VERSION "created by canmatrix"

NS_ :

BS_:

BU_: FR GW

BO_ 33 ADCU_SYNC_FUP: 8 GW
 SG_ ADCU_TSYNC_Type M : 7|8@0+ (1,0) [0|255] ""  FR
 SG_ ADCU_TSYNC_Fup_CRC m40 : 15|8@0+ (1,0) [0|255] ""  FR
 SG_ ADCU_TSYNC_Sync_CRC m32 : 15|8@0+ (1,0) [0|255] ""  FR
 SG_ ADCU_TSYNC_Fup_TimeDomain m40 : 23|4@0+ (1,0) [0|15] ""  FR
 SG_ ADCU_TSYNC_Sync_TimeDomain m32 : 23|4@0+ (1,0) [0|15] ""  FR
 SG_ ADCU_TSYNC_Fup_SeqCounter m40 : 19|4@0+ (1,0) [0|15] ""  FR
 SG_ ADCU_TSYNC_Sync_SeqCounter m32 : 19|4@0+ (1,0) [0|15] ""  FR
 SG_ ADCU_TSYNC_Fup_Reserved m40 : 31|5@0+ (1,0) [0|1] ""  FR
 SG_ ADCU_TSYNC_Sync_UserByte0 m32 : 31|8@0+ (1,0) [0|255] ""  FR
 SG_ ADCU_TSYNC_Fup_SGW m40 : 26|1@0+ (1,0) [0|1] ""  FR
 SG_ ADCU_TSYNC_Fup_OVS m40 : 25|2@0+ (1,0) [0|3] "s"  FR
 SG_ ADCU_TSYNC_Fup_SyncTimeNSec m40 : 39|32@0+ (1,0) [0|4294967295] "ns"  FR
 SG_ ADCU_TSYNC_Sync_TimeSec m32 : 39|32@0+ (1,0) [0|4294967295] "s"  FR

BO_ 48 ARS_TIME_SYNC: 16 FR
 SG_ ARS_TSYNC_TimeStampGlobSec : 7|32@0+ (1,0) [0|4294967295] "s"  GW
 SG_ ARS_TSYNC_CRC16_Checksum : 119|16@0+ (1,0) [0|65535] ""  GW
 SG_ ARS_TSYNC_TimeStampGlobNSec : 39|32@0+ (1,0) [0|4294967295] "ns"  GW
 SG_ ARS_TSYNC_MaxTimeLeap : 71|12@0+ (1,0) [0|4095] "ms"  GW
 SG_ ARS_TSYNC_LastTimeLeap : 87|12@0+ (1,0) [0|4095] "ms"  GW
 SG_ ARS_TSYNC_MsgCounter : 111|8@0+ (1,0) [0|255] ""  GW

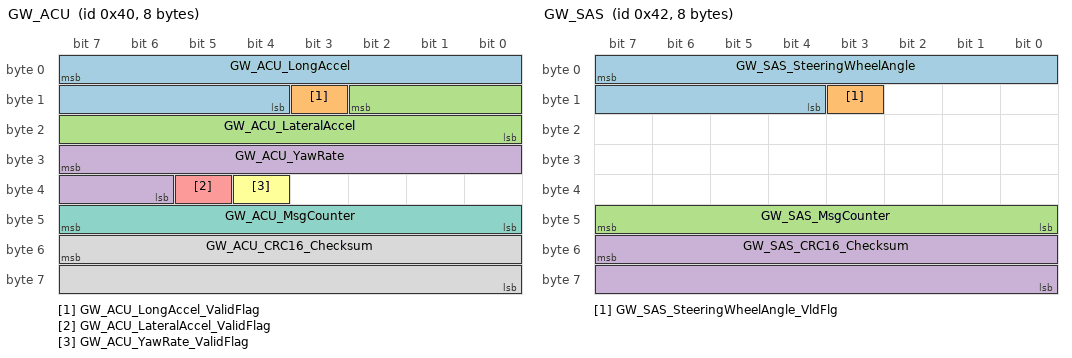
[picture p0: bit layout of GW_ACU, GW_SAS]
BO_ 64 GW_ACU: 8 GW
 SG_ GW_ACU_LongAccel : 7|12@0+ (0.01,-20.48) [-20.48|20.47] "m/s^2"  FR
 SG_ GW_ACU_LongAccel_ValidFlag : 11|1@0+ (1,0) [0|1] ""  FR
 SG_ GW_ACU_LateralAccel : 10|11@0+ (0.01,-10.24) [-10.24|10.23] "m/s^2"  FR
 SG_ GW_ACU_YawRate : 31|10@0+ (0.001,-0.511) [-0.511|0.512] "rad/s"  FR
 SG_ GW_ACU_LateralAccel_ValidFlag : 37|1@0+ (1,0) [0|1] ""  FR
 SG_ GW_ACU_YawRate_ValidFlag : 36|1@0+ (1,0) [0|1] ""  FR
 SG_ GW_ACU_MsgCounter : 47|8@0+ (1,0) [0|255] ""  FR
 SG_ GW_ACU_CRC16_Checksum : 55|16@0+ (1,0) [0|65535] ""  FR

BO_ 65 GW_ESC: 16 GW
 SG_ GW_ESC_WheelSpeed_FL : 7|13@0+ (0.01,0) [0|81.91] "m/s"  FR
 SG_ GW_ESC_MsgCounter : 111|8@0+ (1,0) [0|255] ""  FR
 SG_ GW_ESC_CRC16_Checksum : 119|16@0+ (1,0) [0|65535] ""  FR
 SG_ GW_ESC_WheelSpeed_FL_VldFlg : 10|1@0+ (1,0) [0|1] ""  FR
 SG_ GW_ESC_WheelDirection_FL : 9|2@0+ (1,0) [0|3] ""  FR
 SG_ GW_ESC_WheelSpeed_FR : 23|13@0+ (0.01,0) [0|81.91] "m/s"  FR
 SG_ GW_ESC_WheelSpeed_FR_VldFlg : 26|1@0+ (1,0) [0|1] ""  FR
 SG_ GW_ESC_WheelDirection_FR : 25|2@0+ (1,0) [0|3] ""  FR
 SG_ GW_ESC_WheelSpeed_RL : 39|13@0+ (0.01,0) [0|81.91] "m/s"  FR
 SG_ GW_ESC_WheelSpeed_RL_VldFlg : 42|1@0+ (1,0) [0|1] ""  FR
 SG_ GW_ESC_WheelDirection_RL : 41|2@0+ (1,0) [0|3] ""  FR
 SG_ GW_ESC_WheelSpeed_RR : 55|13@0+ (0.01,0) [0|81.91] "m/s"  FR
 SG_ GW_ESC_WheelSpeed_RR_VldFlg : 58|1@0+ (1,0) [0|1] ""  FR
 SG_ GW_ESC_WheelDirection_RR : 57|2@0+ (1,0) [0|3] ""  FR
 SG_ GW_ESC_WheelDirection_FL_VldFlg : 71|1@0+ (1,0) [0|1] ""  FR
 SG_ GW_ESC_WheelDirection_FR_VldFlg : 70|1@0+ (1,0) [0|1] ""  FR
 SG_ GW_ESC_WheelDirection_RL_VldFlg : 69|1@0+ (1,0) [0|1] ""  FR
 SG_ GW_ESC_WheelDirection_RR_VldFlg : 68|1@0+ (1,0) [0|1] ""  FR
 SG_ GW_ESC_ABS_ActiveFlag : 67|1@0+ (1,0) [0|1] ""  FR
 SG_ GW_ESC_ABS_ValidFlag : 66|1@0+ (1,0) [0|1] ""  FR
 SG_ GW_ESC_TCS_ActiveFlag : 65|1@0+ (1,0) [0|1] ""  FR
 SG_ GW_ESC_TCS_ValidFlag : 64|1@0+ (1,0) [0|1] ""  FR
 SG_ GW_ESC_VehicleSpeed : 79|13@0+ (0.01,0) [0|81.91] "m/s"  FR
 SG_ GW_ESC_VehicleSpeed_ValidFlag : 82|1@0+ (1,0) [0|1] ""  FR
 SG_ GW_ESC_EPB_ActiveFlag : 81|1@0+ (1,0) [0|1] ""  FR
 SG_ GW_ESC_EPB_ValidFlag : 80|1@0+ (1,0) [0|1] ""  FR

BO_ 66 GW_SAS: 8 GW
 SG_ GW_SAS_SteeringWheelAngle : 7|12@0+ (0.01,-20.48) [-20.48|20.47] "rad"  FR
 SG_ GW_SAS_SteeringWheelAngle_VldFlg : 11|1@0+ (1,0) [0|1] ""  FR
 SG_ GW_SAS_MsgCounter : 47|8@0+ (1,0) [0|255] ""  FR
 SG_ GW_SAS_CRC16_Checksum : 55|16@0+ (1,0) [0|65535] ""  FR

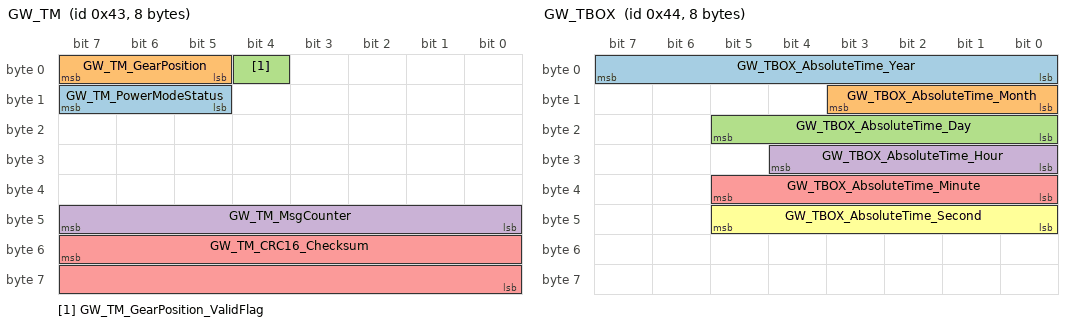
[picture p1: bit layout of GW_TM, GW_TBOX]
BO_ 67 GW_TM: 8 GW
 SG_ GW_TM_PowerModeStatus : 15|3@0+ (1,0) [0|7] ""  FR
 SG_ GW_TM_GearPosition : 7|3@0+ (1,0) [0|7] ""  FR
 SG_ GW_TM_GearPosition_ValidFlag : 4|1@0+ (1,0) [0|1] ""  FR
 SG_ GW_TM_MsgCounter : 47|8@0+ (1,0) [0|255] ""  FR
 SG_ GW_TM_CRC16_Checksum : 55|16@0+ (1,0) [0|65535] ""  FR

BO_ 68 GW_TBOX: 8 GW
 SG_ GW_TBOX_AbsoluteTime_Year : 7|8@0+ (1,1970) [1970|2100] "Year"  FR
 SG_ GW_TBOX_AbsoluteTime_Month : 11|4@0+ (1,0) [1|12] "Month"  FR
 SG_ GW_TBOX_AbsoluteTime_Day : 21|6@0+ (1,0) [1|31] "Day"  FR
 SG_ GW_TBOX_AbsoluteTime_Hour : 28|5@0+ (1,0) [0|23] "Hour"  FR
 SG_ GW_TBOX_AbsoluteTime_Minute : 37|6@0+ (1,0) [0|59] "Minute"  FR
 SG_ GW_TBOX_AbsoluteTime_Second : 45|6@0+ (1,0) [0|59] "Second"  FR

BO_ 69 GW_IDCM: 8 GW
 SG_ GW_IDCM_VehicleTotalMileage : 7|24@0+ (0.1,0) [0|999999.9] ""  FR

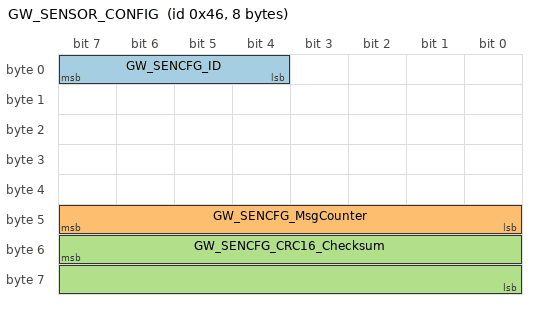
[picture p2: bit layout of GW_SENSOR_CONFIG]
BO_ 70 GW_SENSOR_CONFIG: 8 GW
 SG_ GW_SENCFG_ID : 7|4@0+ (1,0) [0|15] ""  FR
 SG_ GW_SENCFG_MsgCounter : 47|8@0+ (1,0) [0|255] ""  FR
 SG_ GW_SENCFG_CRC16_Checksum : 55|16@0+ (1,0) [0|65535] ""  FR

BO_ 80 ARS_CONFIG_STATE: 32 FR
 SG_ ARS_CFG_Mode : 7|8@0+ (1,0) [0|255] ""  GW
 SG_ ARS_CFG_VParAxisLdDistr_CFGflag : 15|1@0+ (1,0) [0|1] ""  GW
 SG_ ARS_CFG_VParCntrOGrvHght_CFGflag : 14|1@0+ (1,0) [0|1] ""  GW
 SG_ ARS_CFG_VParCntrOGrvHght : 111|10@0+ (0.001,0) [0|1.023] "m"  GW
 SG_ ARS_CFG_VParVehWeight_CFGflag : 13|1@0+ (1,0) [0|1] ""  GW
 SG_ ARS_CFG_VParTrkWdthRear_CFGflag : 12|1@0+ (1,0) [0|1] ""  GW
 SG_ ARS_CFG_VParAxisLdDistr : 127|10@0+ (0.1,0) [0|102.3] "%"  GW
 SG_ ARS_CFG_VParTrkWdthFrnt_CFGflag : 11|1@0+ (1,0) [0|1] ""  GW
 SG_ ARS_CFG_VParLatPos : 143|11@0+ (0.001,-1.023) [-1.023|1.024] "m"  GW
 SG_ ARS_CFG_VParWheelBase_CFGflag : 10|1@0+ (1,0) [0|1] ""  GW
 SG_ ARS_CFG_VParStrRatio_CFGflag : 9|1@0+ (1,0) [0|1] ""  GW
 SG_ ARS_CFG_VParLongPos : 159|13@0+ (0.001,-4.095) [-4.095|4.096] "m"  GW
 SG_ ARS_CFG_TimeSyncEnableFlag : 8|1@0+ (1,0) [0|1] ""  GW
 SG_ ARS_CFG_VParVertPos : 175|10@0+ (0.001,0) [0|1.023] "m"  GW
 SG_ ARS_CFG_VParStrRatio : 23|11@0+ (0.01,0) [0|20.47] ""  GW
 SG_ ARS_CFG_VParLatPos_CFGflag : 181|1@0+ (1,0) [0|1] ""  GW
 SG_ ARS_CFG_SensorID : 180|4@0+ (1,0) [0|15] "" Vector__XXX
 SG_ ARS_CFG_SensorID_CFGflag : 176|1@0+ (1,0) [0|1] "" Vector__XXX
 SG_ ARS_CFG_VParLngPos2CoG : 191|13@0+ (0.001,-4.095) [-4.095|4.096] "m"  GW
 SG_ ARS_CFG_VParYawAngle : 207|13@0+ (0.001,-4.095) [-4.095|4.096] "rad"  GW
 SG_ ARS_CFG_VParLongPos_CFGflag : 210|1@0+ (1,0) [0|1] ""  GW
 SG_ ARS_CFG_VParVertPos_CFGflag : 209|1@0+ (1,0) [0|1] ""  GW
 SG_ ARS_CFG_VParLngPos2CoG_CFGflag : 208|1@0+ (1,0) [0|1] ""  GW
 SG_ ARS_CFG_VParSnsrOrnt : 223|1@0+ (1,0) [0|1] ""  GW
 SG_ ARS_CFG_VParSnsrOrnt_CFGflag : 222|1@0+ (1,0) [0|1] ""  GW
 SG_ ARS_CFG_VParYawAngle_CFGflag : 221|1@0+ (1,0) [0|1] ""  GW
 SG_ ARS_CFG_VParCoverDamping_CFGflag : 220|1@0+ (1,0) [0|1] ""  GW
 SG_ ARS_CFG_VParCoverDamping : 219|12@0+ (0.001,0) [0|4.095] "dB"  GW
 SG_ ARS_CFG_MsgCounter : 239|8@0+ (1,0) [0|255] ""  GW
 SG_ ARS_CFG_CRC16_Checksum : 247|16@0+ (1,0) [0|65535] ""  GW
 SG_ ARS_CFG_VParWheelBase : 28|9@0+ (0.01,0) [0|5.11] "m"  GW
 SG_ ARS_CFG_VParTrkWdthFrnt : 47|11@0+ (0.001,0) [0|2.047] "m"  GW
 SG_ ARS_CFG_VParTrkWdthRear : 63|11@0+ (0.001,0) [0|2.047] "m"  GW
 SG_ ARS_CFG_VParVehWeight : 79|12@0+ (1,0) [0|4095] "kg"  GW

BO_ 82 ARS_SYS_PERFORM: 16 FR
 SG_ ARS_SP_OperationMode : 7|4@0+ (1,0) [0|15] ""  GW
 SG_ ARS_SP_CalibrationState : 3|3@0+ (1,0) [0|7] ""  GW
 SG_ ARS_SP_TunnelFlag : 0|1@0+ (1,0) [0|1] ""  GW
 SG_ ARS_SP_AzimuthCorrection : 15|8@0+ (0.0015,-0.1905) [-0.1905|0.192] "rad"  GW
 SG_ ARS_SP_MsgCounter : 111|8@0+ (1,0) [0|255] ""  GW
 SG_ ARS_SP_CRC16_Checksum : 119|16@0+ (1,0) [0|65535] ""  GW
 SG_ ARS_SP_ElevationCorrection : 23|8@0+ (0.0015,-0.1905) [-0.1905|0.192] "rad"  GW
 SG_ ARS_SP_ErrStateGroup_1 : 31|8@0+ (1,0) [0|255] ""  GW
 SG_ ARS_SP_ErrStateGroup_2 : 39|8@0+ (1,0) [0|255] ""  GW
 SG_ ARS_SP_ErrStateGroup_3 : 47|8@0+ (1,0) [0|255] ""  GW
 SG_ ARS_SP_ErrStateGroup_4 : 55|8@0+ (1,0) [0|255] ""  GW
 SG_ ARS_SP_VisibilityRange : 63|9@0+ (1,0) [0|511] "m"  GW
 SG_ ARS_SP_VisibilityState : 70|2@0+ (1,0) [0|3] ""  GW

BO_ 256 ARS_RDI_Header: 32 FR
 SG_ ARS_RDI_TimeStampGlobSec : 7|32@0+ (1,0) [0|4294967295] "s"  GW
 SG_ ARS_RDI_CycleCounter : 119|16@0+ (1,0) [0|65535] ""  GW
 SG_ ARS_RDI_NumOfClusters : 135|9@0+ (1,0) [0|511] ""  GW
 SG_ ARS_RDI_RangeResolution : 142|7@0+ (0.01,0) [0|1.27] "m"  GW
 SG_ ARS_RDI_MaxDetectionRange : 151|8@0+ (1,0) [0|255] "m"  GW
 SG_ ARS_RDI_EgoVelocity : 159|11@0+ (0.05,-17) [-17|85.35] "m/s"  GW
 SG_ ARS_RDI_EgoYawRate : 164|10@0+ (0.001,-0.511) [-0.511|0.512] "rad/s"  GW
 SG_ ARS_RDI_Latency : 170|11@0+ (0.1,30) [30|234.7] "ms"  GW
 SG_ ARS_RDI_EgoVelocityStd : 191|7@0+ (0.1,0) [0|12.7] "m/s"  GW
 SG_ ARS_RDI_EgoAcceleration : 184|9@0+ (0.0625,-10) [-10|21.9375] "m/s^2"  GW
 SG_ ARS_RDI_EgoCurvature : 207|10@0+ (0.001,-0.511) [-0.511|0.512] "1/m"  GW
 SG_ ARS_RDI_AmbigFreeDopplerRange : 213|12@0+ (0.01,0) [0|40.95] "m/s"  GW
 SG_ ARS_RDI_TaskValidFlag : 217|1@0+ (1,0) [0|1] ""  GW
 SG_ ARS_RDI_ExtendedCycleFlag : 216|1@0+ (1,0) [0|1] ""  GW
 SG_ ARS_RDI_MsgCounter_Header : 239|8@0+ (1,0) [0|255] ""  GW
 SG_ ARS_RDI_CRC16_Checksum_Header : 247|16@0+ (1,0) [0|65535] ""  GW
 SG_ ARS_RDI_TimeStampGlobNSec : 39|32@0+ (1,0) [0|4294967295] "ns"  GW
 SG_ ARS_RDI_TimeStampLocal : 71|32@0+ (1,0) [0|4294967295] "us"  GW
 SG_ ARS_RDI_MeasCounter : 103|16@0+ (1,0) [0|65535] ""  GW

BO_ 257 ARS_RDI_000_007: 64 FR
 SG_ ARS_RDI_Range_Clu_000 : 7|12@0+ (0.0625,0) [0|255.9375] "m"  GW
 SG_ ARS_RDI_ElevationAng_Clu_001 : 109|7@0+ (0.005,-0.315) [-0.315|0.32] "rad"  GW
 SG_ ARS_RDI_SNR_Clu_001 : 118|7@0+ (0.5,0) [0|63.5] "dB"  GW
 SG_ ARS_RDI_Range_Clu_002 : 127|12@0+ (0.0625,0) [0|255.9375] "m"  GW
 SG_ ARS_RDI_VradRel_Clu_000 : 11|11@0+ (0.1,-120) [-120|84.7] "m/s"  GW
 SG_ ARS_RDI_VradRel_Clu_002 : 131|11@0+ (0.1,-120) [-120|84.7] "m/s"  GW
 SG_ ARS_RDI_RCS_Clu_002 : 136|9@0+ (0.2,-51.2) [-51.2|51] "dBsm"  GW
 SG_ ARS_RDI_AzimuthAng_Clu_002 : 159|10@0+ (0.002,-1.022) [-1.022|1.024] "rad"  GW
 SG_ ARS_RDI_ElevationAng_Clu_002 : 165|7@0+ (0.005,-0.315) [-0.315|0.32] "rad"  GW
 SG_ ARS_RDI_SNR_Clu_002 : 174|7@0+ (0.5,0) [0|63.5] "dB"  GW
 SG_ ARS_RDI_DynProp_Clu_002 : 183|2@0+ (1,0) [0|3] ""  GW
 SG_ ARS_RDI_Quality_Clu_002 : 181|2@0+ (1,0) [0|3] ""  GW
 SG_ ARS_RDI_DynProp_Clu_003 : 179|2@0+ (1,0) [0|3] ""  GW
 SG_ ARS_RDI_Quality_Clu_003 : 177|2@0+ (1,0) [0|3] ""  GW
 SG_ ARS_RDI_Range_Clu_003 : 191|12@0+ (0.0625,0) [0|255.9375] "m"  GW
 SG_ ARS_RDI_VradRel_Clu_003 : 195|11@0+ (0.1,-120) [-120|84.7] "m/s"  GW
 SG_ ARS_RDI_RCS_Clu_003 : 200|9@0+ (0.2,-51.2) [-51.2|51] "dBsm"  GW
 SG_ ARS_RDI_AzimuthAng_Clu_003 : 223|10@0+ (0.002,-1.022) [-1.022|1.024] "rad"  GW
 SG_ ARS_RDI_ElevationAng_Clu_003 : 229|7@0+ (0.005,-0.315) [-0.315|0.32] "rad"  GW
 SG_ ARS_RDI_SNR_Clu_003 : 238|7@0+ (0.5,0) [0|63.5] "dB"  GW
 SG_ ARS_RDI_RCS_Clu_000 : 16|9@0+ (0.2,-51.2) [-51.2|51] "dBsm"  GW
 SG_ ARS_RDI_Range_Clu_004 : 247|12@0+ (0.0625,0) [0|255.9375] "m"  GW
 SG_ ARS_RDI_VradRel_Clu_004 : 251|11@0+ (0.1,-120) [-120|84.7] "m/s"  GW
 SG_ ARS_RDI_RCS_Clu_004 : 256|9@0+ (0.2,-51.2) [-51.2|51] "dBsm"  GW
 SG_ ARS_RDI_AzimuthAng_Clu_004 : 279|10@0+ (0.002,-1.022) [-1.022|1.024] "rad"  GW
 SG_ ARS_RDI_ElevationAng_Clu_004 : 285|7@0+ (0.005,-0.315) [-0.315|0.32] "rad"  GW
 SG_ ARS_RDI_SNR_Clu_004 : 294|7@0+ (0.5,0) [0|63.5] "dB"  GW
 SG_ ARS_RDI_DynProp_Clu_004 : 303|2@0+ (1,0) [0|3] ""  GW
 SG_ ARS_RDI_Quality_Clu_004 : 301|2@0+ (1,0) [0|3] ""  GW
 SG_ ARS_RDI_DynProp_Clu_005 : 299|2@0+ (1,0) [0|3] ""  GW
 SG_ ARS_RDI_Quality_Clu_005 : 297|2@0+ (1,0) [0|3] ""  GW
 SG_ ARS_RDI_Range_Clu_005 : 311|12@0+ (0.0625,0) [0|255.9375] "m"  GW
 SG_ ARS_RDI_VradRel_Clu_005 : 315|11@0+ (0.1,-120) [-120|84.7] "m/s"  GW
 SG_ ARS_RDI_RCS_Clu_005 : 320|9@0+ (0.2,-51.2) [-51.2|51] "dBsm"  GW
 SG_ ARS_RDI_AzimuthAng_Clu_000 : 39|10@0+ (0.002,-1.022) [-1.022|1.024] "rad"  GW
 SG_ ARS_RDI_AzimuthAng_Clu_005 : 343|10@0+ (0.002,-1.022) [-1.022|1.024] "rad"  GW
 SG_ ARS_RDI_ElevationAng_Clu_005 : 349|7@0+ (0.005,-0.315) [-0.315|0.32] "rad"  GW
 SG_ ARS_RDI_SNR_Clu_005 : 358|7@0+ (0.5,0) [0|63.5] "dB"  GW
 SG_ ARS_RDI_Range_Clu_006 : 367|12@0+ (0.0625,0) [0|255.9375] "m"  GW
 SG_ ARS_RDI_VradRel_Clu_006 : 371|11@0+ (0.1,-120) [-120|84.7] "m/s"  GW
 SG_ ARS_RDI_RCS_Clu_006 : 376|9@0+ (0.2,-51.2) [-51.2|51] "dBsm"  GW
 SG_ ARS_RDI_AzimuthAng_Clu_006 : 399|10@0+ (0.002,-1.022) [-1.022|1.024] "rad"  GW
 SG_ ARS_RDI_ElevationAng_Clu_006 : 405|7@0+ (0.005,-0.315) [-0.315|0.32] "rad"  GW
 SG_ ARS_RDI_SNR_Clu_006 : 414|7@0+ (0.5,0) [0|63.5] "dB"  GW
 SG_ ARS_RDI_DynProp_Clu_006 : 423|2@0+ (1,0) [0|3] ""  GW
 SG_ ARS_RDI_Quality_Clu_006 : 421|2@0+ (1,0) [0|3] ""  GW
 SG_ ARS_RDI_DynProp_Clu_007 : 419|2@0+ (1,0) [0|3] ""  GW
 SG_ ARS_RDI_Quality_Clu_007 : 417|2@0+ (1,0) [0|3] ""  GW
 SG_ ARS_RDI_Range_Clu_007 : 431|12@0+ (0.0625,0) [0|255.9375] "m"  GW
 SG_ ARS_RDI_ElevationAng_Clu_000 : 45|7@0+ (0.005,-0.315) [-0.315|0.32] "rad"  GW
 SG_ ARS_RDI_VradRel_Clu_007 : 435|11@0+ (0.1,-120) [-120|84.7] "m/s"  GW
 SG_ ARS_RDI_RCS_Clu_007 : 440|9@0+ (0.2,-51.2) [-51.2|51] "dBsm"  GW
 SG_ ARS_RDI_AzimuthAng_Clu_007 : 463|10@0+ (0.002,-1.022) [-1.022|1.024] "rad"  GW
 SG_ ARS_RDI_ElevationAng_Clu_007 : 469|7@0+ (0.005,-0.315) [-0.315|0.32] "rad"  GW
 SG_ ARS_RDI_SNR_Clu_007 : 478|7@0+ (0.5,0) [0|63.5] "dB"  GW
 SG_ ARS_RDI_MsgCounter_Clu_000_007 : 495|8@0+ (1,0) [0|255] ""  GW
 SG_ ARS_RDI_CRC16_Checksum_Clu_000_0 : 503|16@0+ (1,0) [0|65535] ""  GW
 SG_ ARS_RDI_SNR_Clu_000 : 54|7@0+ (0.5,0) [0|63.5] "dB"  GW
 SG_ ARS_RDI_DynProp_Clu_000 : 63|2@0+ (1,0) [0|3] ""  GW
 SG_ ARS_RDI_Quality_Clu_000 : 61|2@0+ (1,0) [0|3] ""  GW
 SG_ ARS_RDI_DynProp_Clu_001 : 59|2@0+ (1,0) [0|3] ""  GW
 SG_ ARS_RDI_Quality_Clu_001 : 57|2@0+ (1,0) [0|3] ""  GW
 SG_ ARS_RDI_Range_Clu_001 : 71|12@0+ (0.0625,0) [0|255.9375] "m"  GW
 SG_ ARS_RDI_VradRel_Clu_001 : 75|11@0+ (0.1,-120) [-120|84.7] "m/s"  GW
 SG_ ARS_RDI_RCS_Clu_001 : 80|9@0+ (0.2,-51.2) [-51.2|51] "dBsm"  GW
 SG_ ARS_RDI_AzimuthAng_Clu_001 : 103|10@0+ (0.002,-1.022) [-1.022|1.024] "rad"  GW

BO_ 258 ARS_RDI_008_015: 64 FR
 SG_ ARS_RDI_Range_Clu_008 : 7|12@0+ (0.0625,0) [0|255.9375] "m"  GW
 SG_ ARS_RDI_ElevationAng_Clu_009 : 109|7@0+ (0.005,-0.315) [-0.315|0.32] "rad"  GW
 SG_ ARS_RDI_SNR_Clu_009 : 118|7@0+ (0.5,0) [0|63.5] "dB"  GW
 SG_ ARS_RDI_Range_Clu_010 : 127|12@0+ (0.0625,0) [0|255.9375] "m"  GW
 SG_ ARS_RDI_VradRel_Clu_008 : 11|11@0+ (0.1,-120) [-120|84.7] "m/s"  GW
 SG_ ARS_RDI_VradRel_Clu_010 : 131|11@0+ (0.1,-120) [-120|84.7] "m/s"  GW
 SG_ ARS_RDI_RCS_Clu_010 : 136|9@0+ (0.2,-51.2) [-51.2|51] "dBsm"  GW
 SG_ ARS_RDI_AzimuthAng_Clu_010 : 159|10@0+ (0.002,-1.022) [-1.022|1.024] "rad"  GW
 SG_ ARS_RDI_ElevationAng_Clu_010 : 165|7@0+ (0.005,-0.315) [-0.315|0.32] "rad"  GW
 SG_ ARS_RDI_SNR_Clu_010 : 174|7@0+ (0.5,0) [0|63.5] "dB"  GW
 SG_ ARS_RDI_DynProp_Clu_010 : 183|2@0+ (1,0) [0|3] ""  GW
 SG_ ARS_RDI_Quality_Clu_010 : 181|2@0+ (1,0) [0|3] ""  GW
 SG_ ARS_RDI_DynProp_Clu_011 : 179|2@0+ (1,0) [0|3] ""  GW
 SG_ ARS_RDI_Quality_Clu_011 : 177|2@0+ (1,0) [0|3] ""  GW
 SG_ ARS_RDI_Range_Clu_011 : 191|12@0+ (0.0625,0) [0|255.9375] "m"  GW
 SG_ ARS_RDI_VradRel_Clu_011 : 195|11@0+ (0.1,-120) [-120|84.7] "m/s"  GW
 SG_ ARS_RDI_RCS_Clu_011 : 200|9@0+ (0.2,-51.2) [-51.2|51] "dBsm"  GW
 SG_ ARS_RDI_AzimuthAng_Clu_011 : 223|10@0+ (0.002,-1.022) [-1.022|1.024] "rad"  GW
 SG_ ARS_RDI_ElevationAng_Clu_011 : 229|7@0+ (0.005,-0.315) [-0.315|0.32] "rad"  GW
 SG_ ARS_RDI_SNR_Clu_011 : 238|7@0+ (0.5,0) [0|63.5] "dB"  GW
 SG_ ARS_RDI_RCS_Clu_008 : 16|9@0+ (0.2,-51.2) [-51.2|51] "dBsm"  GW
 SG_ ARS_RDI_Range_Clu_012 : 247|12@0+ (0.0625,0) [0|255.9375] "m"  GW
 SG_ ARS_RDI_VradRel_Clu_012 : 251|11@0+ (0.1,-120) [-120|84.7] "m/s"  GW
 SG_ ARS_RDI_RCS_Clu_012 : 256|9@0+ (0.2,-51.2) [-51.2|51] "dBsm"  GW
 SG_ ARS_RDI_AzimuthAng_Clu_012 : 279|10@0+ (0.002,-1.022) [-1.022|1.024] "rad"  GW
 SG_ ARS_RDI_ElevationAng_Clu_012 : 285|7@0+ (0.005,-0.315) [-0.315|0.32] "rad"  GW
 SG_ ARS_RDI_SNR_Clu_012 : 294|7@0+ (0.5,0) [0|63.5] "dB"  GW
 SG_ ARS_RDI_DynProp_Clu_012 : 303|2@0+ (1,0) [0|3] ""  GW
 SG_ ARS_RDI_Quality_Clu_012 : 301|2@0+ (1,0) [0|3] ""  GW
 SG_ ARS_RDI_DynProp_Clu_013 : 299|2@0+ (1,0) [0|3] ""  GW
 SG_ ARS_RDI_Quality_Clu_013 : 297|2@0+ (1,0) [0|3] ""  GW
 SG_ ARS_RDI_Range_Clu_013 : 311|12@0+ (0.0625,0) [0|255.9375] "m"  GW
 SG_ ARS_RDI_VradRel_Clu_013 : 315|11@0+ (0.1,-120) [-120|84.7] "m/s"  GW
 SG_ ARS_RDI_RCS_Clu_013 : 320|9@0+ (0.2,-51.2) [-51.2|51] "dBsm"  GW
 SG_ ARS_RDI_AzimuthAng_Clu_008 : 39|10@0+ (0.002,-1.022) [-1.022|1.024] "rad"  GW
 SG_ ARS_RDI_AzimuthAng_Clu_013 : 343|10@0+ (0.002,-1.022) [-1.022|1.024] "rad"  GW
 SG_ ARS_RDI_ElevationAng_Clu_013 : 349|7@0+ (0.005,-0.315) [-0.315|0.32] "rad"  GW
 SG_ ARS_RDI_SNR_Clu_013 : 358|7@0+ (0.5,0) [0|63.5] "dB"  GW
 SG_ ARS_RDI_Range_Clu_014 : 367|12@0+ (0.0625,0) [0|255.9375] "m"  GW
 SG_ ARS_RDI_VradRel_Clu_014 : 371|11@0+ (0.1,-120) [-120|84.7] "m/s"  GW
 SG_ ARS_RDI_RCS_Clu_014 : 376|9@0+ (0.2,-51.2) [-51.2|51] "dBsm"  GW
 SG_ ARS_RDI_AzimuthAng_Clu_014 : 399|10@0+ (0.002,-1.022) [-1.022|1.024] "rad"  GW
 SG_ ARS_RDI_ElevationAng_Clu_014 : 405|7@0+ (0.005,-0.315) [-0.315|0.32] "rad"  GW
 SG_ ARS_RDI_SNR_Clu_014 : 414|7@0+ (0.5,0) [0|63.5] "dB"  GW
 SG_ ARS_RDI_DynProp_Clu_014 : 423|2@0+ (1,0) [0|3] ""  GW
 SG_ ARS_RDI_Quality_Clu_014 : 421|2@0+ (1,0) [0|3] ""  GW
 SG_ ARS_RDI_DynProp_Clu_015 : 419|2@0+ (1,0) [0|3] ""  GW
 SG_ ARS_RDI_Quality_Clu_015 : 417|2@0+ (1,0) [0|3] ""  GW
 SG_ ARS_RDI_Range_Clu_015 : 431|12@0+ (0.0625,0) [0|255.9375] "m"  GW
 SG_ ARS_RDI_ElevationAng_Clu_008 : 45|7@0+ (0.005,-0.315) [-0.315|0.32] "rad"  GW
 SG_ ARS_RDI_VradRel_Clu_015 : 435|11@0+ (0.1,-120) [-120|84.7] "m/s"  GW
 SG_ ARS_RDI_RCS_Clu_015 : 440|9@0+ (0.2,-51.2) [-51.2|51] "dBsm"  GW
 SG_ ARS_RDI_AzimuthAng_Clu_015 : 463|10@0+ (0.002,-1.022) [-1.022|1.024] "rad"  GW
 SG_ ARS_RDI_ElevationAng_Clu_015 : 469|7@0+ (0.005,-0.315) [-0.315|0.32] "rad"  GW
 SG_ ARS_RDI_SNR_Clu_015 : 478|7@0+ (0.5,0) [0|63.5] "dB"  GW
 SG_ ARS_RDI_MsgCounter_Clu_008_015 : 495|8@0+ (1,0) [0|255] ""  GW
 SG_ ARS_RDI_CRC16_Checksum_Clu_008_0 : 503|16@0+ (1,0) [0|65535] ""  GW
 SG_ ARS_RDI_SNR_Clu_008 : 54|7@0+ (0.5,0) [0|63.5] "dB"  GW
 SG_ ARS_RDI_DynProp_Clu_008 : 63|2@0+ (1,0) [0|3] ""  GW
 SG_ ARS_RDI_Quality_Clu_008 : 61|2@0+ (1,0) [0|3] ""  GW
 SG_ ARS_RDI_DynProp_Clu_009 : 59|2@0+ (1,0) [0|3] ""  GW
 SG_ ARS_RDI_Quality_Clu_009 : 57|2@0+ (1,0) [0|3] ""  GW
 SG_ ARS_RDI_Range_Clu_009 : 71|12@0+ (0.0625,0) [0|255.9375] "m"  GW
 SG_ ARS_RDI_VradRel_Clu_009 : 75|11@0+ (0.1,-120) [-120|84.7] "m/s"  GW
 SG_ ARS_RDI_RCS_Clu_009 : 80|9@0+ (0.2,-51.2) [-51.2|51] "dBsm"  GW
 SG_ ARS_RDI_AzimuthAng_Clu_009 : 103|10@0+ (0.002,-1.022) [-1.022|1.024] "rad"  GW

BO_ 259 ARS_RDI_016_023: 64 FR
 SG_ ARS_RDI_Range_Clu_016 : 7|12@0+ (0.0625,0) [0|255.9375] "m"  GW
 SG_ ARS_RDI_ElevationAng_Clu_017 : 109|7@0+ (0.005,-0.315) [-0.315|0.32] "rad"  GW
 SG_ ARS_RDI_SNR_Clu_017 : 118|7@0+ (0.5,0) [0|63.5] "dB"  GW
 SG_ ARS_RDI_Range_Clu_018 : 127|12@0+ (0.0625,0) [0|255.9375] "m"  GW
 SG_ ARS_RDI_VradRel_Clu_016 : 11|11@0+ (0.1,-120) [-120|84.7] "m/s"  GW
 SG_ ARS_RDI_VradRel_Clu_018 : 131|11@0+ (0.1,-120) [-120|84.7] "m/s"  GW
 SG_ ARS_RDI_RCS_Clu_018 : 136|9@0+ (0.2,-51.2) [-51.2|51] "dBsm"  GW
 SG_ ARS_RDI_AzimuthAng_Clu_018 : 159|10@0+ (0.002,-1.022) [-1.022|1.024] "rad"  GW
 SG_ ARS_RDI_ElevationAng_Clu_018 : 165|7@0+ (0.005,-0.315) [-0.315|0.32] "rad"  GW
 SG_ ARS_RDI_SNR_Clu_018 : 174|7@0+ (0.5,0) [0|63.5] "dB"  GW
 SG_ ARS_RDI_DynProp_Clu_018 : 183|2@0+ (1,0) [0|3] ""  GW
 SG_ ARS_RDI_Quality_Clu_018 : 181|2@0+ (1,0) [0|3] ""  GW
 SG_ ARS_RDI_DynProp_Clu_019 : 179|2@0+ (1,0) [0|3] ""  GW
 SG_ ARS_RDI_Quality_Clu_019 : 177|2@0+ (1,0) [0|3] ""  GW
 SG_ ARS_RDI_Range_Clu_019 : 191|12@0+ (0.0625,0) [0|255.9375] "m"  GW
 SG_ ARS_RDI_VradRel_Clu_019 : 195|11@0+ (0.1,-120) [-120|84.7] "m/s"  GW
 SG_ ARS_RDI_RCS_Clu_019 : 200|9@0+ (0.2,-51.2) [-51.2|51] "dBsm"  GW
 SG_ ARS_RDI_AzimuthAng_Clu_019 : 223|10@0+ (0.002,-1.022) [-1.022|1.024] "rad"  GW
 SG_ ARS_RDI_ElevationAng_Clu_019 : 229|7@0+ (0.005,-0.315) [-0.315|0.32] "rad"  GW
 SG_ ARS_RDI_SNR_Clu_019 : 238|7@0+ (0.5,0) [0|63.5] "dB"  GW
 SG_ ARS_RDI_RCS_Clu_016 : 16|9@0+ (0.2,-51.2) [-51.2|51] "dBsm"  GW
 SG_ ARS_RDI_Range_Clu_020 : 247|12@0+ (0.0625,0) [0|255.9375] "m"  GW
 SG_ ARS_RDI_VradRel_Clu_020 : 251|11@0+ (0.1,-120) [-120|84.7] "m/s"  GW
 SG_ ARS_RDI_RCS_Clu_020 : 256|9@0+ (0.2,-51.2) [-51.2|51] "dBsm"  GW
 SG_ ARS_RDI_AzimuthAng_Clu_020 : 279|10@0+ (0.002,-1.022) [-1.022|1.024] "rad"  GW
 SG_ ARS_RDI_ElevationAng_Clu_020 : 285|7@0+ (0.005,-0.315) [-0.315|0.32] "rad"  GW
 SG_ ARS_RDI_SNR_Clu_020 : 294|7@0+ (0.5,0) [0|63.5] "dB"  GW
 SG_ ARS_RDI_DynProp_Clu_020 : 303|2@0+ (1,0) [0|3] ""  GW
 SG_ ARS_RDI_Quality_Clu_020 : 301|2@0+ (1,0) [0|3] ""  GW
 SG_ ARS_RDI_DynProp_Clu_021 : 299|2@0+ (1,0) [0|3] ""  GW
 SG_ ARS_RDI_Quality_Clu_021 : 297|2@0+ (1,0) [0|3] ""  GW
 SG_ ARS_RDI_Range_Clu_021 : 311|12@0+ (0.0625,0) [0|255.9375] "m"  GW
 SG_ ARS_RDI_VradRel_Clu_021 : 315|11@0+ (0.1,-120) [-120|84.7] "m/s"  GW
 SG_ ARS_RDI_RCS_Clu_021 : 320|9@0+ (0.2,-51.2) [-51.2|51] "dBsm"  GW
 SG_ ARS_RDI_AzimuthAng_Clu_016 : 39|10@0+ (0.002,-1.022) [-1.022|1.024] "rad"  GW
 SG_ ARS_RDI_AzimuthAng_Clu_021 : 343|10@0+ (0.002,-1.022) [-1.022|1.024] "rad"  GW
 SG_ ARS_RDI_ElevationAng_Clu_021 : 349|7@0+ (0.005,-0.315) [-0.315|0.32] "rad"  GW
 SG_ ARS_RDI_SNR_Clu_021 : 358|7@0+ (0.5,0) [0|63.5] "dB"  GW
 SG_ ARS_RDI_Range_Clu_022 : 367|12@0+ (0.0625,0) [0|255.9375] "m"  GW
 SG_ ARS_RDI_VradRel_Clu_022 : 371|11@0+ (0.1,-120) [-120|84.7] "m/s"  GW
 SG_ ARS_RDI_RCS_Clu_022 : 376|9@0+ (0.2,-51.2) [-51.2|51] "dBsm"  GW
 SG_ ARS_RDI_AzimuthAng_Clu_022 : 399|10@0+ (0.002,-1.022) [-1.022|1.024] "rad"  GW
 SG_ ARS_RDI_ElevationAng_Clu_022 : 405|7@0+ (0.005,-0.315) [-0.315|0.32] "rad"  GW
 SG_ ARS_RDI_SNR_Clu_022 : 414|7@0+ (0.5,0) [0|63.5] "dB"  GW
 SG_ ARS_RDI_DynProp_Clu_022 : 423|2@0+ (1,0) [0|3] ""  GW
 SG_ ARS_RDI_Quality_Clu_022 : 421|2@0+ (1,0) [0|3] ""  GW
 SG_ ARS_RDI_DynProp_Clu_023 : 419|2@0+ (1,0) [0|3] ""  GW
 SG_ ARS_RDI_Quality_Clu_023 : 417|2@0+ (1,0) [0|3] ""  GW
 SG_ ARS_RDI_Range_Clu_023 : 431|12@0+ (0.0625,0) [0|255.9375] "m"  GW
 SG_ ARS_RDI_ElevationAng_Clu_016 : 45|7@0+ (0.005,-0.315) [-0.315|0.32] "rad"  GW
 SG_ ARS_RDI_VradRel_Clu_023 : 435|11@0+ (0.1,-120) [-120|84.7] "m/s"  GW
 SG_ ARS_RDI_RCS_Clu_023 : 440|9@0+ (0.2,-51.2) [-51.2|51] "dBsm"  GW
 SG_ ARS_RDI_AzimuthAng_Clu_023 : 463|10@0+ (0.002,-1.022) [-1.022|1.024] "rad"  GW
 SG_ ARS_RDI_ElevationAng_Clu_023 : 469|7@0+ (0.005,-0.315) [-0.315|0.32] "rad"  GW
 SG_ ARS_RDI_SNR_Clu_023 : 478|7@0+ (0.5,0) [0|63.5] "dB"  GW
 SG_ ARS_RDI_MsgCounter_Clu_016_023 : 495|8@0+ (1,0) [0|255] ""  GW
 SG_ ARS_RDI_CRC16_Checksum_Clu_016_0 : 503|16@0+ (1,0) [0|65535] ""  GW
 SG_ ARS_RDI_SNR_Clu_016 : 54|7@0+ (0.5,0) [0|63.5] "dB"  GW
 SG_ ARS_RDI_DynProp_Clu_016 : 63|2@0+ (1,0) [0|3] ""  GW
 SG_ ARS_RDI_Quality_Clu_016 : 61|2@0+ (1,0) [0|3] ""  GW
 SG_ ARS_RDI_DynProp_Clu_017 : 59|2@0+ (1,0) [0|3] ""  GW
 SG_ ARS_RDI_Quality_Clu_017 : 57|2@0+ (1,0) [0|3] ""  GW
 SG_ ARS_RDI_Range_Clu_017 : 71|12@0+ (0.0625,0) [0|255.9375] "m"  GW
 SG_ ARS_RDI_VradRel_Clu_017 : 75|11@0+ (0.1,-120) [-120|84.7] "m/s"  GW
 SG_ ARS_RDI_RCS_Clu_017 : 80|9@0+ (0.2,-51.2) [-51.2|51] "dBsm"  GW
 SG_ ARS_RDI_AzimuthAng_Clu_017 : 103|10@0+ (0.002,-1.022) [-1.022|1.024] "rad"  GW

BO_ 260 ARS_RDI_024_031: 64 FR
 SG_ ARS_RDI_Range_Clu_024 : 7|12@0+ (0.0625,0) [0|255.9375] "m"  GW
 SG_ ARS_RDI_ElevationAng_Clu_025 : 109|7@0+ (0.005,-0.315) [-0.315|0.32] "rad"  GW
 SG_ ARS_RDI_SNR_Clu_025 : 118|7@0+ (0.5,0) [0|63.5] "dB"  GW
 SG_ ARS_RDI_Range_Clu_026 : 127|12@0+ (0.0625,0) [0|255.9375] "m"  GW
 SG_ ARS_RDI_VradRel_Clu_024 : 11|11@0+ (0.1,-120) [-120|84.7] "m/s"  GW
 SG_ ARS_RDI_VradRel_Clu_026 : 131|11@0+ (0.1,-120) [-120|84.7] "m/s"  GW
 SG_ ARS_RDI_RCS_Clu_026 : 136|9@0+ (0.2,-51.2) [-51.2|51] "dBsm"  GW
 SG_ ARS_RDI_AzimuthAng_Clu_026 : 159|10@0+ (0.002,-1.022) [-1.022|1.024] "rad"  GW
 SG_ ARS_RDI_ElevationAng_Clu_026 : 165|7@0+ (0.005,-0.315) [-0.315|0.32] "rad"  GW
 SG_ ARS_RDI_SNR_Clu_026 : 174|7@0+ (0.5,0) [0|63.5] "dB"  GW
 SG_ ARS_RDI_DynProp_Clu_026 : 183|2@0+ (1,0) [0|3] ""  GW
 SG_ ARS_RDI_Quality_Clu_026 : 181|2@0+ (1,0) [0|3] ""  GW
 SG_ ARS_RDI_DynProp_Clu_027 : 179|2@0+ (1,0) [0|3] ""  GW
 SG_ ARS_RDI_Quality_Clu_027 : 177|2@0+ (1,0) [0|3] ""  GW
 SG_ ARS_RDI_Range_Clu_027 : 191|12@0+ (0.0625,0) [0|255.9375] "m"  GW
 SG_ ARS_RDI_VradRel_Clu_027 : 195|11@0+ (0.1,-120) [-120|84.7] "m/s"  GW
 SG_ ARS_RDI_RCS_Clu_027 : 200|9@0+ (0.2,-51.2) [-51.2|51] "dBsm"  GW
 SG_ ARS_RDI_AzimuthAng_Clu_027 : 223|10@0+ (0.002,-1.022) [-1.022|1.024] "rad"  GW
 SG_ ARS_RDI_ElevationAng_Clu_027 : 229|7@0+ (0.005,-0.315) [-0.315|0.32] "rad"  GW
 SG_ ARS_RDI_SNR_Clu_027 : 238|7@0+ (0.5,0) [0|63.5] "dB"  GW
 SG_ ARS_RDI_RCS_Clu_024 : 16|9@0+ (0.2,-51.2) [-51.2|51] "dBsm"  GW
 SG_ ARS_RDI_Range_Clu_028 : 247|12@0+ (0.0625,0) [0|255.9375] "m"  GW
 SG_ ARS_RDI_VradRel_Clu_028 : 251|11@0+ (0.1,-120) [-120|84.7] "m/s"  GW
 SG_ ARS_RDI_RCS_Clu_028 : 256|9@0+ (0.2,-51.2) [-51.2|51] "dBsm"  GW
 SG_ ARS_RDI_AzimuthAng_Clu_028 : 279|10@0+ (0.002,-1.022) [-1.022|1.024] "rad"  GW
 SG_ ARS_RDI_ElevationAng_Clu_028 : 285|7@0+ (0.005,-0.315) [-0.315|0.32] "rad"  GW
 SG_ ARS_RDI_SNR_Clu_028 : 294|7@0+ (0.5,0) [0|63.5] "dB"  GW
 SG_ ARS_RDI_DynProp_Clu_028 : 303|2@0+ (1,0) [0|3] ""  GW
 SG_ ARS_RDI_Quality_Clu_028 : 301|2@0+ (1,0) [0|3] ""  GW
 SG_ ARS_RDI_DynProp_Clu_029 : 299|2@0+ (1,0) [0|3] ""  GW
 SG_ ARS_RDI_Quality_Clu_029 : 297|2@0+ (1,0) [0|3] ""  GW
 SG_ ARS_RDI_Range_Clu_029 : 311|12@0+ (0.0625,0) [0|255.9375] "m"  GW
 SG_ ARS_RDI_VradRel_Clu_029 : 315|11@0+ (0.1,-120) [-120|84.7] "m/s"  GW
 SG_ ARS_RDI_RCS_Clu_029 : 320|9@0+ (0.2,-51.2) [-51.2|51] "dBsm"  GW
 SG_ ARS_RDI_AzimuthAng_Clu_024 : 39|10@0+ (0.002,-1.022) [-1.022|1.024] "rad"  GW
 SG_ ARS_RDI_AzimuthAng_Clu_029 : 343|10@0+ (0.002,-1.022) [-1.022|1.024] "rad"  GW
 SG_ ARS_RDI_ElevationAng_Clu_029 : 349|7@0+ (0.005,-0.315) [-0.315|0.32] "rad"  GW
 SG_ ARS_RDI_SNR_Clu_029 : 358|7@0+ (0.5,0) [0|63.5] "dB"  GW
 SG_ ARS_RDI_Range_Clu_030 : 367|12@0+ (0.0625,0) [0|255.9375] "m"  GW
 SG_ ARS_RDI_VradRel_Clu_030 : 371|11@0+ (0.1,-120) [-120|84.7] "m/s"  GW
 SG_ ARS_RDI_RCS_Clu_030 : 376|9@0+ (0.2,-51.2) [-51.2|51] "dBsm"  GW
 SG_ ARS_RDI_AzimuthAng_Clu_030 : 399|10@0+ (0.002,-1.022) [-1.022|1.024] "rad"  GW
 SG_ ARS_RDI_ElevationAng_Clu_030 : 405|7@0+ (0.005,-0.315) [-0.315|0.32] "rad"  GW
 SG_ ARS_RDI_SNR_Clu_030 : 414|7@0+ (0.5,0) [0|63.5] "dB"  GW
 SG_ ARS_RDI_DynProp_Clu_030 : 423|2@0+ (1,0) [0|3] ""  GW
 SG_ ARS_RDI_Quality_Clu_030 : 421|2@0+ (1,0) [0|3] ""  GW
 SG_ ARS_RDI_DynProp_Clu_031 : 419|2@0+ (1,0) [0|3] ""  GW
 SG_ ARS_RDI_Quality_Clu_031 : 417|2@0+ (1,0) [0|3] ""  GW
 SG_ ARS_RDI_Range_Clu_031 : 431|12@0+ (0.0625,0) [0|255.9375] "m"  GW
 SG_ ARS_RDI_ElevationAng_Clu_024 : 45|7@0+ (0.005,-0.315) [-0.315|0.32] "rad"  GW
 SG_ ARS_RDI_VradRel_Clu_031 : 435|11@0+ (0.1,-120) [-120|84.7] "m/s"  GW
 SG_ ARS_RDI_RCS_Clu_031 : 440|9@0+ (0.2,-51.2) [-51.2|51] "dBsm"  GW
 SG_ ARS_RDI_AzimuthAng_Clu_031 : 463|10@0+ (0.002,-1.022) [-1.022|1.024] "rad"  GW
 SG_ ARS_RDI_ElevationAng_Clu_031 : 469|7@0+ (0.005,-0.315) [-0.315|0.32] "rad"  GW
 SG_ ARS_RDI_SNR_Clu_031 : 478|7@0+ (0.5,0) [0|63.5] "dB"  GW
 SG_ ARS_RDI_MsgCounter_Clu_024_031 : 495|8@0+ (1,0) [0|255] ""  GW
 SG_ ARS_RDI_CRC16_Checksum_Clu_024_0 : 503|16@0+ (1,0) [0|65535] ""  GW
 SG_ ARS_RDI_SNR_Clu_024 : 54|7@0+ (0.5,0) [0|63.5] "dB"  GW
 SG_ ARS_RDI_DynProp_Clu_024 : 63|2@0+ (1,0) [0|3] ""  GW
 SG_ ARS_RDI_Quality_Clu_024 : 61|2@0+ (1,0) [0|3] ""  GW
 SG_ ARS_RDI_DynProp_Clu_025 : 59|2@0+ (1,0) [0|3] ""  GW
 SG_ ARS_RDI_Quality_Clu_025 : 57|2@0+ (1,0) [0|3] ""  GW
 SG_ ARS_RDI_Range_Clu_025 : 71|12@0+ (0.0625,0) [0|255.9375] "m"  GW
 SG_ ARS_RDI_VradRel_Clu_025 : 75|11@0+ (0.1,-120) [-120|84.7] "m/s"  GW
 SG_ ARS_RDI_RCS_Clu_025 : 80|9@0+ (0.2,-51.2) [-51.2|51] "dBsm"  GW
 SG_ ARS_RDI_AzimuthAng_Clu_025 : 103|10@0+ (0.002,-1.022) [-1.022|1.024] "rad"  GW

BO_ 261 ARS_RDI_032_039: 64 FR
 SG_ ARS_RDI_Range_Clu_032 : 7|12@0+ (0.0625,0) [0|255.9375] "m"  GW
 SG_ ARS_RDI_ElevationAng_Clu_033 : 109|7@0+ (0.005,-0.315) [-0.315|0.32] "rad"  GW
 SG_ ARS_RDI_SNR_Clu_033 : 118|7@0+ (0.5,0) [0|63.5] "dB"  GW
 SG_ ARS_RDI_Range_Clu_034 : 127|12@0+ (0.0625,0) [0|255.9375] "m"  GW
 SG_ ARS_RDI_VradRel_Clu_032 : 11|11@0+ (0.1,-120) [-120|84.7] "m/s"  GW
 SG_ ARS_RDI_VradRel_Clu_034 : 131|11@0+ (0.1,-120) [-120|84.7] "m/s"  GW
 SG_ ARS_RDI_RCS_Clu_034 : 136|9@0+ (0.2,-51.2) [-51.2|51] "dBsm"  GW
 SG_ ARS_RDI_AzimuthAng_Clu_034 : 159|10@0+ (0.002,-1.022) [-1.022|1.024] "rad"  GW
 SG_ ARS_RDI_ElevationAng_Clu_034 : 165|7@0+ (0.005,-0.315) [-0.315|0.32] "rad"  GW
 SG_ ARS_RDI_SNR_Clu_034 : 174|7@0+ (0.5,0) [0|63.5] "dB"  GW
 SG_ ARS_RDI_DynProp_Clu_034 : 183|2@0+ (1,0) [0|3] ""  GW
 SG_ ARS_RDI_Quality_Clu_034 : 181|2@0+ (1,0) [0|3] ""  GW
 SG_ ARS_RDI_DynProp_Clu_035 : 179|2@0+ (1,0) [0|3] ""  GW
 SG_ ARS_RDI_Quality_Clu_035 : 177|2@0+ (1,0) [0|3] ""  GW
 SG_ ARS_RDI_Range_Clu_035 : 191|12@0+ (0.0625,0) [0|255.9375] "m"  GW
 SG_ ARS_RDI_VradRel_Clu_035 : 195|11@0+ (0.1,-120) [-120|84.7] "m/s"  GW
 SG_ ARS_RDI_RCS_Clu_035 : 200|9@0+ (0.2,-51.2) [-51.2|51] "dBsm"  GW
 SG_ ARS_RDI_AzimuthAng_Clu_035 : 223|10@0+ (0.002,-1.022) [-1.022|1.024] "rad"  GW
 SG_ ARS_RDI_ElevationAng_Clu_035 : 229|7@0+ (0.005,-0.315) [-0.315|0.32] "rad"  GW
 SG_ ARS_RDI_SNR_Clu_035 : 238|7@0+ (0.5,0) [0|63.5] "dB"  GW
 SG_ ARS_RDI_RCS_Clu_032 : 16|9@0+ (0.2,-51.2) [-51.2|51] "dBsm"  GW
 SG_ ARS_RDI_Range_Clu_036 : 247|12@0+ (0.0625,0) [0|255.9375] "m"  GW
 SG_ ARS_RDI_VradRel_Clu_036 : 251|11@0+ (0.1,-120) [-120|84.7] "m/s"  GW
 SG_ ARS_RDI_RCS_Clu_036 : 256|9@0+ (0.2,-51.2) [-51.2|51] "dBsm"  GW
 SG_ ARS_RDI_AzimuthAng_Clu_036 : 279|10@0+ (0.002,-1.022) [-1.022|1.024] "rad"  GW
 SG_ ARS_RDI_ElevationAng_Clu_036 : 285|7@0+ (0.005,-0.315) [-0.315|0.32] "rad"  GW
 SG_ ARS_RDI_SNR_Clu_036 : 294|7@0+ (0.5,0) [0|63.5] "dB"  GW
 SG_ ARS_RDI_DynProp_Clu_036 : 303|2@0+ (1,0) [0|3] ""  GW
 SG_ ARS_RDI_Quality_Clu_036 : 301|2@0+ (1,0) [0|3] ""  GW
 SG_ ARS_RDI_DynProp_Clu_037 : 299|2@0+ (1,0) [0|3] ""  GW
 SG_ ARS_RDI_Quality_Clu_037 : 297|2@0+ (1,0) [0|3] ""  GW
 SG_ ARS_RDI_Range_Clu_037 : 311|12@0+ (0.0625,0) [0|255.9375] "m"  GW
 SG_ ARS_RDI_VradRel_Clu_037 : 315|11@0+ (0.1,-120) [-120|84.7] "m/s"  GW
 SG_ ARS_RDI_RCS_Clu_037 : 320|9@0+ (0.2,-51.2) [-51.2|51] "dBsm"  GW
 SG_ ARS_RDI_AzimuthAng_Clu_032 : 39|10@0+ (0.002,-1.022) [-1.022|1.024] "rad"  GW
 SG_ ARS_RDI_AzimuthAng_Clu_037 : 343|10@0+ (0.002,-1.022) [-1.022|1.024] "rad"  GW
 SG_ ARS_RDI_ElevationAng_Clu_037 : 349|7@0+ (0.005,-0.315) [-0.315|0.32] "rad"  GW
 SG_ ARS_RDI_SNR_Clu_037 : 358|7@0+ (0.5,0) [0|63.5] "dB"  GW
 SG_ ARS_RDI_Range_Clu_038 : 367|12@0+ (0.0625,0) [0|255.9375] "m"  GW
 SG_ ARS_RDI_VradRel_Clu_038 : 371|11@0+ (0.1,-120) [-120|84.7] "m/s"  GW
 SG_ ARS_RDI_RCS_Clu_038 : 376|9@0+ (0.2,-51.2) [-51.2|51] "dBsm"  GW
 SG_ ARS_RDI_AzimuthAng_Clu_038 : 399|10@0+ (0.002,-1.022) [-1.022|1.024] "rad"  GW
 SG_ ARS_RDI_ElevationAng_Clu_038 : 405|7@0+ (0.005,-0.315) [-0.315|0.32] "rad"  GW
 SG_ ARS_RDI_SNR_Clu_038 : 414|7@0+ (0.5,0) [0|63.5] "dB"  GW
 SG_ ARS_RDI_DynProp_Clu_038 : 423|2@0+ (1,0) [0|3] ""  GW
 SG_ ARS_RDI_Quality_Clu_038 : 421|2@0+ (1,0) [0|3] ""  GW
 SG_ ARS_RDI_DynProp_Clu_039 : 419|2@0+ (1,0) [0|3] ""  GW
 SG_ ARS_RDI_Quality_Clu_039 : 417|2@0+ (1,0) [0|3] ""  GW
 SG_ ARS_RDI_Range_Clu_039 : 431|12@0+ (0.0625,0) [0|255.9375] "m"  GW
 SG_ ARS_RDI_ElevationAng_Clu_032 : 45|7@0+ (0.005,-0.315) [-0.315|0.32] "rad"  GW
 SG_ ARS_RDI_VradRel_Clu_039 : 435|11@0+ (0.1,-120) [-120|84.7] "m/s"  GW
 SG_ ARS_RDI_RCS_Clu_039 : 440|9@0+ (0.2,-51.2) [-51.2|51] "dBsm"  GW
 SG_ ARS_RDI_AzimuthAng_Clu_039 : 463|10@0+ (0.002,-1.022) [-1.022|1.024] "rad"  GW
 SG_ ARS_RDI_ElevationAng_Clu_039 : 469|7@0+ (0.005,-0.315) [-0.315|0.32] "rad"  GW
 SG_ ARS_RDI_SNR_Clu_039 : 478|7@0+ (0.5,0) [0|63.5] "dB"  GW
 SG_ ARS_RDI_MsgCounter_Clu_032_039 : 495|8@0+ (1,0) [0|255] ""  GW
 SG_ ARS_RDI_CRC16_Checksum_Clu_032_0 : 503|16@0+ (1,0) [0|65535] ""  GW
 SG_ ARS_RDI_SNR_Clu_032 : 54|7@0+ (0.5,0) [0|63.5] "dB"  GW
 SG_ ARS_RDI_DynProp_Clu_032 : 63|2@0+ (1,0) [0|3] ""  GW
 SG_ ARS_RDI_Quality_Clu_032 : 61|2@0+ (1,0) [0|3] ""  GW
 SG_ ARS_RDI_DynProp_Clu_033 : 59|2@0+ (1,0) [0|3] ""  GW
 SG_ ARS_RDI_Quality_Clu_033 : 57|2@0+ (1,0) [0|3] ""  GW
 SG_ ARS_RDI_Range_Clu_033 : 71|12@0+ (0.0625,0) [0|255.9375] "m"  GW
 SG_ ARS_RDI_VradRel_Clu_033 : 75|11@0+ (0.1,-120) [-120|84.7] "m/s"  GW
 SG_ ARS_RDI_RCS_Clu_033 : 80|9@0+ (0.2,-51.2) [-51.2|51] "dBsm"  GW
 SG_ ARS_RDI_AzimuthAng_Clu_033 : 103|10@0+ (0.002,-1.022) [-1.022|1.024] "rad"  GW

BO_ 262 ARS_RDI_040_047: 64 FR
 SG_ ARS_RDI_Range_Clu_040 : 7|12@0+ (0.0625,0) [0|255.9375] "m"  GW
 SG_ ARS_RDI_ElevationAng_Clu_041 : 109|7@0+ (0.005,-0.315) [-0.315|0.32] "rad"  GW
 SG_ ARS_RDI_SNR_Clu_041 : 118|7@0+ (0.5,0) [0|63.5] "dB"  GW
 SG_ ARS_RDI_Range_Clu_042 : 127|12@0+ (0.0625,0) [0|255.9375] "m"  GW
 SG_ ARS_RDI_VradRel_Clu_040 : 11|11@0+ (0.1,-120) [-120|84.7] "m/s"  GW
 SG_ ARS_RDI_VradRel_Clu_042 : 131|11@0+ (0.1,-120) [-120|84.7] "m/s"  GW
 SG_ ARS_RDI_RCS_Clu_042 : 136|9@0+ (0.2,-51.2) [-51.2|51] "dBsm"  GW
 SG_ ARS_RDI_AzimuthAng_Clu_042 : 159|10@0+ (0.002,-1.022) [-1.022|1.024] "rad"  GW
 SG_ ARS_RDI_ElevationAng_Clu_042 : 165|7@0+ (0.005,-0.315) [-0.315|0.32] "rad"  GW
 SG_ ARS_RDI_SNR_Clu_042 : 174|7@0+ (0.5,0) [0|63.5] "dB"  GW
 SG_ ARS_RDI_DynProp_Clu_042 : 183|2@0+ (1,0) [0|3] ""  GW
 SG_ ARS_RDI_Quality_Clu_042 : 181|2@0+ (1,0) [0|3] ""  GW
 SG_ ARS_RDI_DynProp_Clu_043 : 179|2@0+ (1,0) [0|3] ""  GW
 SG_ ARS_RDI_Quality_Clu_043 : 177|2@0+ (1,0) [0|3] ""  GW
 SG_ ARS_RDI_Range_Clu_043 : 191|12@0+ (0.0625,0) [0|255.9375] "m"  GW
 SG_ ARS_RDI_VradRel_Clu_043 : 195|11@0+ (0.1,-120) [-120|84.7] "m/s"  GW
 SG_ ARS_RDI_RCS_Clu_043 : 200|9@0+ (0.2,-51.2) [-51.2|51] "dBsm"  GW
 SG_ ARS_RDI_AzimuthAng_Clu_043 : 223|10@0+ (0.002,-1.022) [-1.022|1.024] "rad"  GW
 SG_ ARS_RDI_ElevationAng_Clu_043 : 229|7@0+ (0.005,-0.315) [-0.315|0.32] "rad"  GW
 SG_ ARS_RDI_SNR_Clu_043 : 238|7@0+ (0.5,0) [0|63.5] "dB"  GW
 SG_ ARS_RDI_RCS_Clu_040 : 16|9@0+ (0.2,-51.2) [-51.2|51] "dBsm"  GW
 SG_ ARS_RDI_Range_Clu_044 : 247|12@0+ (0.0625,0) [0|255.9375] "m"  GW
 SG_ ARS_RDI_VradRel_Clu_044 : 251|11@0+ (0.1,-120) [-120|84.7] "m/s"  GW
 SG_ ARS_RDI_RCS_Clu_044 : 256|9@0+ (0.2,-51.2) [-51.2|51] "dBsm"  GW
 SG_ ARS_RDI_AzimuthAng_Clu_044 : 279|10@0+ (0.002,-1.022) [-1.022|1.024] "rad"  GW
 SG_ ARS_RDI_ElevationAng_Clu_044 : 285|7@0+ (0.005,-0.315) [-0.315|0.32] "rad"  GW
 SG_ ARS_RDI_SNR_Clu_044 : 294|7@0+ (0.5,0) [0|63.5] "dB"  GW
 SG_ ARS_RDI_DynProp_Clu_044 : 303|2@0+ (1,0) [0|3] ""  GW
 SG_ ARS_RDI_Quality_Clu_044 : 301|2@0+ (1,0) [0|3] ""  GW
 SG_ ARS_RDI_DynProp_Clu_045 : 299|2@0+ (1,0) [0|3] ""  GW
 SG_ ARS_RDI_Quality_Clu_045 : 297|2@0+ (1,0) [0|3] ""  GW
 SG_ ARS_RDI_Range_Clu_045 : 311|12@0+ (0.0625,0) [0|255.9375] "m"  GW
 SG_ ARS_RDI_VradRel_Clu_045 : 315|11@0+ (0.1,-120) [-120|84.7] "m/s"  GW
 SG_ ARS_RDI_RCS_Clu_045 : 320|9@0+ (0.2,-51.2) [-51.2|51] "dBsm"  GW
 SG_ ARS_RDI_AzimuthAng_Clu_040 : 39|10@0+ (0.002,-1.022) [-1.022|1.024] "rad"  GW
 SG_ ARS_RDI_AzimuthAng_Clu_045 : 343|10@0+ (0.002,-1.022) [-1.022|1.024] "rad"  GW
 SG_ ARS_RDI_ElevationAng_Clu_045 : 349|7@0+ (0.005,-0.315) [-0.315|0.32] "rad"  GW
 SG_ ARS_RDI_SNR_Clu_045 : 358|7@0+ (0.5,0) [0|63.5] "dB"  GW
 SG_ ARS_RDI_Range_Clu_046 : 367|12@0+ (0.0625,0) [0|255.9375] "m"  GW
 SG_ ARS_RDI_VradRel_Clu_046 : 371|11@0+ (0.1,-120) [-120|84.7] "m/s"  GW
 SG_ ARS_RDI_RCS_Clu_046 : 376|9@0+ (0.2,-51.2) [-51.2|51] "dBsm"  GW
 SG_ ARS_RDI_AzimuthAng_Clu_046 : 399|10@0+ (0.002,-1.022) [-1.022|1.024] "rad"  GW
 SG_ ARS_RDI_ElevationAng_Clu_046 : 405|7@0+ (0.005,-0.315) [-0.315|0.32] "rad"  GW
 SG_ ARS_RDI_SNR_Clu_046 : 414|7@0+ (0.5,0) [0|63.5] "dB"  GW
 SG_ ARS_RDI_DynProp_Clu_046 : 423|2@0+ (1,0) [0|3] ""  GW
 SG_ ARS_RDI_Quality_Clu_046 : 421|2@0+ (1,0) [0|3] ""  GW
 SG_ ARS_RDI_DynProp_Clu_047 : 419|2@0+ (1,0) [0|3] ""  GW
 SG_ ARS_RDI_Quality_Clu_047 : 417|2@0+ (1,0) [0|3] ""  GW
 SG_ ARS_RDI_Range_Clu_047 : 431|12@0+ (0.0625,0) [0|255.9375] "m"  GW
 SG_ ARS_RDI_ElevationAng_Clu_040 : 45|7@0+ (0.005,-0.315) [-0.315|0.32] "rad"  GW
 SG_ ARS_RDI_VradRel_Clu_047 : 435|11@0+ (0.1,-120) [-120|84.7] "m/s"  GW
 SG_ ARS_RDI_RCS_Clu_047 : 440|9@0+ (0.2,-51.2) [-51.2|51] "dBsm"  GW
 SG_ ARS_RDI_AzimuthAng_Clu_047 : 463|10@0+ (0.002,-1.022) [-1.022|1.024] "rad"  GW
 SG_ ARS_RDI_ElevationAng_Clu_047 : 469|7@0+ (0.005,-0.315) [-0.315|0.32] "rad"  GW
 SG_ ARS_RDI_SNR_Clu_047 : 478|7@0+ (0.5,0) [0|63.5] "dB"  GW
 SG_ ARS_RDI_MsgCounter_Clu_040_047 : 495|8@0+ (1,0) [0|255] ""  GW
 SG_ ARS_RDI_CRC16_Checksum_Clu_040_0 : 503|16@0+ (1,0) [0|65535] ""  GW
 SG_ ARS_RDI_SNR_Clu_040 : 54|7@0+ (0.5,0) [0|63.5] "dB"  GW
 SG_ ARS_RDI_DynProp_Clu_040 : 63|2@0+ (1,0) [0|3] ""  GW
 SG_ ARS_RDI_Quality_Clu_040 : 61|2@0+ (1,0) [0|3] ""  GW
 SG_ ARS_RDI_DynProp_Clu_041 : 59|2@0+ (1,0) [0|3] ""  GW
 SG_ ARS_RDI_Quality_Clu_041 : 57|2@0+ (1,0) [0|3] ""  GW
 SG_ ARS_RDI_Range_Clu_041 : 71|12@0+ (0.0625,0) [0|255.9375] "m"  GW
 SG_ ARS_RDI_VradRel_Clu_041 : 75|11@0+ (0.1,-120) [-120|84.7] "m/s"  GW
 SG_ ARS_RDI_RCS_Clu_041 : 80|9@0+ (0.2,-51.2) [-51.2|51] "dBsm"  GW
 SG_ ARS_RDI_AzimuthAng_Clu_041 : 103|10@0+ (0.002,-1.022) [-1.022|1.024] "rad"  GW

BO_ 263 ARS_RDI_048_055: 64 FR
 SG_ ARS_RDI_Range_Clu_048 : 7|12@0+ (0.0625,0) [0|255.9375] "m"  GW
 SG_ ARS_RDI_ElevationAng_Clu_049 : 109|7@0+ (0.005,-0.315) [-0.315|0.32] "rad"  GW
 SG_ ARS_RDI_SNR_Clu_049 : 118|7@0+ (0.5,0) [0|63.5] "dB"  GW
 SG_ ARS_RDI_Range_Clu_050 : 127|12@0+ (0.0625,0) [0|255.9375] "m"  GW
 SG_ ARS_RDI_VradRel_Clu_048 : 11|11@0+ (0.1,-120) [-120|84.7] "m/s"  GW
 SG_ ARS_RDI_VradRel_Clu_050 : 131|11@0+ (0.1,-120) [-120|84.7] "m/s"  GW
 SG_ ARS_RDI_RCS_Clu_050 : 136|9@0+ (0.2,-51.2) [-51.2|51] "dBsm"  GW
 SG_ ARS_RDI_AzimuthAng_Clu_050 : 159|10@0+ (0.002,-1.022) [-1.022|1.024] "rad"  GW
 SG_ ARS_RDI_ElevationAng_Clu_050 : 165|7@0+ (0.005,-0.315) [-0.315|0.32] "rad"  GW
 SG_ ARS_RDI_SNR_Clu_050 : 174|7@0+ (0.5,0) [0|63.5] "dB"  GW
 SG_ ARS_RDI_DynProp_Clu_050 : 183|2@0+ (1,0) [0|3] ""  GW
 SG_ ARS_RDI_Quality_Clu_050 : 181|2@0+ (1,0) [0|3] ""  GW
 SG_ ARS_RDI_DynProp_Clu_051 : 179|2@0+ (1,0) [0|3] ""  GW
 SG_ ARS_RDI_Quality_Clu_051 : 177|2@0+ (1,0) [0|3] ""  GW
 SG_ ARS_RDI_Range_Clu_051 : 191|12@0+ (0.0625,0) [0|255.9375] "m"  GW
 SG_ ARS_RDI_VradRel_Clu_051 : 195|11@0+ (0.1,-120) [-120|84.7] "m/s"  GW
 SG_ ARS_RDI_RCS_Clu_051 : 200|9@0+ (0.2,-51.2) [-51.2|51] "dBsm"  GW
 SG_ ARS_RDI_AzimuthAng_Clu_051 : 223|10@0+ (0.002,-1.022) [-1.022|1.024] "rad"  GW
 SG_ ARS_RDI_ElevationAng_Clu_051 : 229|7@0+ (0.005,-0.315) [-0.315|0.32] "rad"  GW
 SG_ ARS_RDI_SNR_Clu_051 : 238|7@0+ (0.5,0) [0|63.5] "dB"  GW
 SG_ ARS_RDI_RCS_Clu_048 : 16|9@0+ (0.2,-51.2) [-51.2|51] "dBsm"  GW
 SG_ ARS_RDI_Range_Clu_052 : 247|12@0+ (0.0625,0) [0|255.9375] "m"  GW
 SG_ ARS_RDI_VradRel_Clu_052 : 251|11@0+ (0.1,-120) [-120|84.7] "m/s"  GW
 SG_ ARS_RDI_RCS_Clu_052 : 256|9@0+ (0.2,-51.2) [-51.2|51] "dBsm"  GW
 SG_ ARS_RDI_AzimuthAng_Clu_052 : 279|10@0+ (0.002,-1.022) [-1.022|1.024] "rad"  GW
 SG_ ARS_RDI_ElevationAng_Clu_052 : 285|7@0+ (0.005,-0.315) [-0.315|0.32] "rad"  GW
 SG_ ARS_RDI_SNR_Clu_052 : 294|7@0+ (0.5,0) [0|63.5] "dB"  GW
 SG_ ARS_RDI_DynProp_Clu_052 : 303|2@0+ (1,0) [0|3] ""  GW
 SG_ ARS_RDI_Quality_Clu_052 : 301|2@0+ (1,0) [0|3] ""  GW
 SG_ ARS_RDI_DynProp_Clu_053 : 299|2@0+ (1,0) [0|3] ""  GW
 SG_ ARS_RDI_Quality_Clu_053 : 297|2@0+ (1,0) [0|3] ""  GW
 SG_ ARS_RDI_Range_Clu_053 : 311|12@0+ (0.0625,0) [0|255.9375] "m"  GW
 SG_ ARS_RDI_VradRel_Clu_053 : 315|11@0+ (0.1,-120) [-120|84.7] "m/s"  GW
 SG_ ARS_RDI_RCS_Clu_053 : 320|9@0+ (0.2,-51.2) [-51.2|51] "dBsm"  GW
 SG_ ARS_RDI_AzimuthAng_Clu_048 : 39|10@0+ (0.002,-1.022) [-1.022|1.024] "rad"  GW
 SG_ ARS_RDI_AzimuthAng_Clu_053 : 343|10@0+ (0.002,-1.022) [-1.022|1.024] "rad"  GW
 SG_ ARS_RDI_ElevationAng_Clu_053 : 349|7@0+ (0.005,-0.315) [-0.315|0.32] "rad"  GW
 SG_ ARS_RDI_SNR_Clu_053 : 358|7@0+ (0.5,0) [0|63.5] "dB"  GW
 SG_ ARS_RDI_Range_Clu_054 : 367|12@0+ (0.0625,0) [0|255.9375] "m"  GW
 SG_ ARS_RDI_VradRel_Clu_054 : 371|11@0+ (0.1,-120) [-120|84.7] "m/s"  GW
 SG_ ARS_RDI_RCS_Clu_054 : 376|9@0+ (0.2,-51.2) [-51.2|51] "dBsm"  GW
 SG_ ARS_RDI_AzimuthAng_Clu_054 : 399|10@0+ (0.002,-1.022) [-1.022|1.024] "rad"  GW
 SG_ ARS_RDI_ElevationAng_Clu_054 : 405|7@0+ (0.005,-0.315) [-0.315|0.32] "rad"  GW
 SG_ ARS_RDI_SNR_Clu_054 : 414|7@0+ (0.5,0) [0|63.5] "dB"  GW
 SG_ ARS_RDI_DynProp_Clu_054 : 423|2@0+ (1,0) [0|3] ""  GW
 SG_ ARS_RDI_Quality_Clu_054 : 421|2@0+ (1,0) [0|3] ""  GW
 SG_ ARS_RDI_DynProp_Clu_055 : 419|2@0+ (1,0) [0|3] ""  GW
 SG_ ARS_RDI_Quality_Clu_055 : 417|2@0+ (1,0) [0|3] ""  GW
 SG_ ARS_RDI_Range_Clu_055 : 431|12@0+ (0.0625,0) [0|255.9375] "m"  GW
 SG_ ARS_RDI_ElevationAng_Clu_048 : 45|7@0+ (0.005,-0.315) [-0.315|0.32] "rad"  GW
 SG_ ARS_RDI_VradRel_Clu_055 : 435|11@0+ (0.1,-120) [-120|84.7] "m/s"  GW
 SG_ ARS_RDI_RCS_Clu_055 : 440|9@0+ (0.2,-51.2) [-51.2|51] "dBsm"  GW
 SG_ ARS_RDI_AzimuthAng_Clu_055 : 463|10@0+ (0.002,-1.022) [-1.022|1.024] "rad"  GW
 SG_ ARS_RDI_ElevationAng_Clu_055 : 469|7@0+ (0.005,-0.315) [-0.315|0.32] "rad"  GW
 SG_ ARS_RDI_SNR_Clu_055 : 478|7@0+ (0.5,0) [0|63.5] "dB"  GW
 SG_ ARS_RDI_MsgCounter_Clu_048_055 : 495|8@0+ (1,0) [0|255] ""  GW
 SG_ ARS_RDI_CRC16_Checksum_Clu_048_0 : 503|16@0+ (1,0) [0|65535] ""  GW
 SG_ ARS_RDI_SNR_Clu_048 : 54|7@0+ (0.5,0) [0|63.5] "dB"  GW
 SG_ ARS_RDI_DynProp_Clu_048 : 63|2@0+ (1,0) [0|3] ""  GW
 SG_ ARS_RDI_Quality_Clu_048 : 61|2@0+ (1,0) [0|3] ""  GW
 SG_ ARS_RDI_DynProp_Clu_049 : 59|2@0+ (1,0) [0|3] ""  GW
 SG_ ARS_RDI_Quality_Clu_049 : 57|2@0+ (1,0) [0|3] ""  GW
 SG_ ARS_RDI_Range_Clu_049 : 71|12@0+ (0.0625,0) [0|255.9375] "m"  GW
 SG_ ARS_RDI_VradRel_Clu_049 : 75|11@0+ (0.1,-120) [-120|84.7] "m/s"  GW
 SG_ ARS_RDI_RCS_Clu_049 : 80|9@0+ (0.2,-51.2) [-51.2|51] "dBsm"  GW
 SG_ ARS_RDI_AzimuthAng_Clu_049 : 103|10@0+ (0.002,-1.022) [-1.022|1.024] "rad"  GW

BO_ 264 ARS_RDI_056_063: 64 FR
 SG_ ARS_RDI_Range_Clu_056 : 7|12@0+ (0.0625,0) [0|255.9375] "m"  GW
 SG_ ARS_RDI_ElevationAng_Clu_057 : 109|7@0+ (0.005,-0.315) [-0.315|0.32] "rad"  GW
 SG_ ARS_RDI_SNR_Clu_057 : 118|7@0+ (0.5,0) [0|63.5] "dB"  GW
 SG_ ARS_RDI_Range_Clu_058 : 127|12@0+ (0.0625,0) [0|255.9375] "m"  GW
 SG_ ARS_RDI_VradRel_Clu_056 : 11|11@0+ (0.1,-120) [-120|84.7] "m/s"  GW
 SG_ ARS_RDI_VradRel_Clu_058 : 131|11@0+ (0.1,-120) [-120|84.7] "m/s"  GW
 SG_ ARS_RDI_RCS_Clu_058 : 136|9@0+ (0.2,-51.2) [-51.2|51] "dBsm"  GW
 SG_ ARS_RDI_AzimuthAng_Clu_058 : 159|10@0+ (0.002,-1.022) [-1.022|1.024] "rad"  GW
 SG_ ARS_RDI_ElevationAng_Clu_058 : 165|7@0+ (0.005,-0.315) [-0.315|0.32] "rad"  GW
 SG_ ARS_RDI_SNR_Clu_058 : 174|7@0+ (0.5,0) [0|63.5] "dB"  GW
 SG_ ARS_RDI_DynProp_Clu_058 : 183|2@0+ (1,0) [0|3] ""  GW
 SG_ ARS_RDI_Quality_Clu_058 : 181|2@0+ (1,0) [0|3] ""  GW
 SG_ ARS_RDI_DynProp_Clu_059 : 179|2@0+ (1,0) [0|3] ""  GW
 SG_ ARS_RDI_Quality_Clu_059 : 177|2@0+ (1,0) [0|3] ""  GW
 SG_ ARS_RDI_Range_Clu_059 : 191|12@0+ (0.0625,0) [0|255.9375] "m"  GW
 SG_ ARS_RDI_VradRel_Clu_059 : 195|11@0+ (0.1,-120) [-120|84.7] "m/s"  GW
 SG_ ARS_RDI_RCS_Clu_059 : 200|9@0+ (0.2,-51.2) [-51.2|51] "dBsm"  GW
 SG_ ARS_RDI_AzimuthAng_Clu_059 : 223|10@0+ (0.002,-1.022) [-1.022|1.024] "rad"  GW
 SG_ ARS_RDI_ElevationAng_Clu_059 : 229|7@0+ (0.005,-0.315) [-0.315|0.32] "rad"  GW
 SG_ ARS_RDI_SNR_Clu_059 : 238|7@0+ (0.5,0) [0|63.5] "dB"  GW
 SG_ ARS_RDI_RCS_Clu_056 : 16|9@0+ (0.2,-51.2) [-51.2|51] "dBsm"  GW
 SG_ ARS_RDI_Range_Clu_060 : 247|12@0+ (0.0625,0) [0|255.9375] "m"  GW
 SG_ ARS_RDI_VradRel_Clu_060 : 251|11@0+ (0.1,-120) [-120|84.7] "m/s"  GW
 SG_ ARS_RDI_RCS_Clu_060 : 256|9@0+ (0.2,-51.2) [-51.2|51] "dBsm"  GW
 SG_ ARS_RDI_AzimuthAng_Clu_060 : 279|10@0+ (0.002,-1.022) [-1.022|1.024] "rad"  GW
 SG_ ARS_RDI_ElevationAng_Clu_060 : 285|7@0+ (0.005,-0.315) [-0.315|0.32] "rad"  GW
 SG_ ARS_RDI_SNR_Clu_060 : 294|7@0+ (0.5,0) [0|63.5] "dB"  GW
 SG_ ARS_RDI_DynProp_Clu_060 : 303|2@0+ (1,0) [0|3] ""  GW
 SG_ ARS_RDI_Quality_Clu_060 : 301|2@0+ (1,0) [0|3] ""  GW
 SG_ ARS_RDI_DynProp_Clu_061 : 299|2@0+ (1,0) [0|3] ""  GW
 SG_ ARS_RDI_Quality_Clu_061 : 297|2@0+ (1,0) [0|3] ""  GW
 SG_ ARS_RDI_Range_Clu_061 : 311|12@0+ (0.0625,0) [0|255.9375] "m"  GW
 SG_ ARS_RDI_VradRel_Clu_061 : 315|11@0+ (0.1,-120) [-120|84.7] "m/s"  GW
 SG_ ARS_RDI_RCS_Clu_061 : 320|9@0+ (0.2,-51.2) [-51.2|51] "dBsm"  GW
 SG_ ARS_RDI_AzimuthAng_Clu_056 : 39|10@0+ (0.002,-1.022) [-1.022|1.024] "rad"  GW
 SG_ ARS_RDI_AzimuthAng_Clu_061 : 343|10@0+ (0.002,-1.022) [-1.022|1.024] "rad"  GW
 SG_ ARS_RDI_ElevationAng_Clu_061 : 349|7@0+ (0.005,-0.315) [-0.315|0.32] "rad"  GW
 SG_ ARS_RDI_SNR_Clu_061 : 358|7@0+ (0.5,0) [0|63.5] "dB"  GW
 SG_ ARS_RDI_Range_Clu_062 : 367|12@0+ (0.0625,0) [0|255.9375] "m"  GW
 SG_ ARS_RDI_VradRel_Clu_062 : 371|11@0+ (0.1,-120) [-120|84.7] "m/s"  GW
 SG_ ARS_RDI_RCS_Clu_062 : 376|9@0+ (0.2,-51.2) [-51.2|51] "dBsm"  GW
 SG_ ARS_RDI_AzimuthAng_Clu_062 : 399|10@0+ (0.002,-1.022) [-1.022|1.024] "rad"  GW
 SG_ ARS_RDI_ElevationAng_Clu_062 : 405|7@0+ (0.005,-0.315) [-0.315|0.32] "rad"  GW
 SG_ ARS_RDI_SNR_Clu_062 : 414|7@0+ (0.5,0) [0|63.5] "dB"  GW
 SG_ ARS_RDI_DynProp_Clu_062 : 423|2@0+ (1,0) [0|3] ""  GW
 SG_ ARS_RDI_Quality_Clu_062 : 421|2@0+ (1,0) [0|3] ""  GW
 SG_ ARS_RDI_DynProp_Clu_063 : 419|2@0+ (1,0) [0|3] ""  GW
 SG_ ARS_RDI_Quality_Clu_063 : 417|2@0+ (1,0) [0|3] ""  GW
 SG_ ARS_RDI_Range_Clu_063 : 431|12@0+ (0.0625,0) [0|255.9375] "m"  GW
 SG_ ARS_RDI_ElevationAng_Clu_056 : 45|7@0+ (0.005,-0.315) [-0.315|0.32] "rad"  GW
 SG_ ARS_RDI_VradRel_Clu_063 : 435|11@0+ (0.1,-120) [-120|84.7] "m/s"  GW
 SG_ ARS_RDI_RCS_Clu_063 : 440|9@0+ (0.2,-51.2) [-51.2|51] "dBsm"  GW
 SG_ ARS_RDI_AzimuthAng_Clu_063 : 463|10@0+ (0.002,-1.022) [-1.022|1.024] "rad"  GW
 SG_ ARS_RDI_ElevationAng_Clu_063 : 469|7@0+ (0.005,-0.315) [-0.315|0.32] "rad"  GW
 SG_ ARS_RDI_SNR_Clu_063 : 478|7@0+ (0.5,0) [0|63.5] "dB"  GW
 SG_ ARS_RDI_MsgCounter_Clu_056_063 : 495|8@0+ (1,0) [0|255] ""  GW
 SG_ ARS_RDI_CRC16_Checksum_Clu_056_0 : 503|16@0+ (1,0) [0|65535] ""  GW
 SG_ ARS_RDI_SNR_Clu_056 : 54|7@0+ (0.5,0) [0|63.5] "dB"  GW
 SG_ ARS_RDI_DynProp_Clu_056 : 63|2@0+ (1,0) [0|3] ""  GW
 SG_ ARS_RDI_Quality_Clu_056 : 61|2@0+ (1,0) [0|3] ""  GW
 SG_ ARS_RDI_DynProp_Clu_057 : 59|2@0+ (1,0) [0|3] ""  GW
 SG_ ARS_RDI_Quality_Clu_057 : 57|2@0+ (1,0) [0|3] ""  GW
 SG_ ARS_RDI_Range_Clu_057 : 71|12@0+ (0.0625,0) [0|255.9375] "m"  GW
 SG_ ARS_RDI_VradRel_Clu_057 : 75|11@0+ (0.1,-120) [-120|84.7] "m/s"  GW
 SG_ ARS_RDI_RCS_Clu_057 : 80|9@0+ (0.2,-51.2) [-51.2|51] "dBsm"  GW
 SG_ ARS_RDI_AzimuthAng_Clu_057 : 103|10@0+ (0.002,-1.022) [-1.022|1.024] "rad"  GW

BO_ 265 ARS_RDI_064_071: 64 FR
 SG_ ARS_RDI_Range_Clu_064 : 7|12@0+ (0.0625,0) [0|255.9375] "m"  GW
 SG_ ARS_RDI_ElevationAng_Clu_065 : 109|7@0+ (0.005,-0.315) [-0.315|0.32] "rad"  GW
 SG_ ARS_RDI_SNR_Clu_065 : 118|7@0+ (0.5,0) [0|63.5] "dB"  GW
 SG_ ARS_RDI_Range_Clu_066 : 127|12@0+ (0.0625,0) [0|255.9375] "m"  GW
 SG_ ARS_RDI_VradRel_Clu_064 : 11|11@0+ (0.1,-120) [-120|84.7] "m/s"  GW
 SG_ ARS_RDI_VradRel_Clu_066 : 131|11@0+ (0.1,-120) [-120|84.7] "m/s"  GW
 SG_ ARS_RDI_RCS_Clu_066 : 136|9@0+ (0.2,-51.2) [-51.2|51] "dBsm"  GW
 SG_ ARS_RDI_AzimuthAng_Clu_066 : 159|10@0+ (0.002,-1.022) [-1.022|1.024] "rad"  GW
 SG_ ARS_RDI_ElevationAng_Clu_066 : 165|7@0+ (0.005,-0.315) [-0.315|0.32] "rad"  GW
 SG_ ARS_RDI_SNR_Clu_066 : 174|7@0+ (0.5,0) [0|63.5] "dB"  GW
 SG_ ARS_RDI_DynProp_Clu_066 : 183|2@0+ (1,0) [0|3] ""  GW
 SG_ ARS_RDI_Quality_Clu_066 : 181|2@0+ (1,0) [0|3] ""  GW
 SG_ ARS_RDI_DynProp_Clu_067 : 179|2@0+ (1,0) [0|3] ""  GW
 SG_ ARS_RDI_Quality_Clu_067 : 177|2@0+ (1,0) [0|3] ""  GW
 SG_ ARS_RDI_Range_Clu_067 : 191|12@0+ (0.0625,0) [0|255.9375] "m"  GW
 SG_ ARS_RDI_VradRel_Clu_067 : 195|11@0+ (0.1,-120) [-120|84.7] "m/s"  GW
 SG_ ARS_RDI_RCS_Clu_067 : 200|9@0+ (0.2,-51.2) [-51.2|51] "dBsm"  GW
 SG_ ARS_RDI_AzimuthAng_Clu_067 : 223|10@0+ (0.002,-1.022) [-1.022|1.024] "rad"  GW
 SG_ ARS_RDI_ElevationAng_Clu_067 : 229|7@0+ (0.005,-0.315) [-0.315|0.32] "rad"  GW
 SG_ ARS_RDI_SNR_Clu_067 : 238|7@0+ (0.5,0) [0|63.5] "dB"  GW
 SG_ ARS_RDI_RCS_Clu_064 : 16|9@0+ (0.2,-51.2) [-51.2|51] "dBsm"  GW
 SG_ ARS_RDI_Range_Clu_068 : 247|12@0+ (0.0625,0) [0|255.9375] "m"  GW
 SG_ ARS_RDI_VradRel_Clu_068 : 251|11@0+ (0.1,-120) [-120|84.7] "m/s"  GW
 SG_ ARS_RDI_RCS_Clu_068 : 256|9@0+ (0.2,-51.2) [-51.2|51] "dBsm"  GW
 SG_ ARS_RDI_AzimuthAng_Clu_068 : 279|10@0+ (0.002,-1.022) [-1.022|1.024] "rad"  GW
 SG_ ARS_RDI_ElevationAng_Clu_068 : 285|7@0+ (0.005,-0.315) [-0.315|0.32] "rad"  GW
 SG_ ARS_RDI_SNR_Clu_068 : 294|7@0+ (0.5,0) [0|63.5] "dB"  GW
 SG_ ARS_RDI_DynProp_Clu_068 : 303|2@0+ (1,0) [0|3] ""  GW
 SG_ ARS_RDI_Quality_Clu_068 : 301|2@0+ (1,0) [0|3] ""  GW
 SG_ ARS_RDI_DynProp_Clu_069 : 299|2@0+ (1,0) [0|3] ""  GW
 SG_ ARS_RDI_Quality_Clu_069 : 297|2@0+ (1,0) [0|3] ""  GW
 SG_ ARS_RDI_Range_Clu_069 : 311|12@0+ (0.0625,0) [0|255.9375] "m"  GW
 SG_ ARS_RDI_VradRel_Clu_069 : 315|11@0+ (0.1,-120) [-120|84.7] "m/s"  GW
 SG_ ARS_RDI_RCS_Clu_069 : 320|9@0+ (0.2,-51.2) [-51.2|51] "dBsm"  GW
 SG_ ARS_RDI_AzimuthAng_Clu_064 : 39|10@0+ (0.002,-1.022) [-1.022|1.024] "rad"  GW
 SG_ ARS_RDI_AzimuthAng_Clu_069 : 343|10@0+ (0.002,-1.022) [-1.022|1.024] "rad"  GW
 SG_ ARS_RDI_ElevationAng_Clu_069 : 349|7@0+ (0.005,-0.315) [-0.315|0.32] "rad"  GW
 SG_ ARS_RDI_SNR_Clu_069 : 358|7@0+ (0.5,0) [0|63.5] "dB"  GW
 SG_ ARS_RDI_Range_Clu_070 : 367|12@0+ (0.0625,0) [0|255.9375] "m"  GW
 SG_ ARS_RDI_VradRel_Clu_070 : 371|11@0+ (0.1,-120) [-120|84.7] "m/s"  GW
 SG_ ARS_RDI_RCS_Clu_070 : 376|9@0+ (0.2,-51.2) [-51.2|51] "dBsm"  GW
 SG_ ARS_RDI_AzimuthAng_Clu_070 : 399|10@0+ (0.002,-1.022) [-1.022|1.024] "rad"  GW
 SG_ ARS_RDI_ElevationAng_Clu_070 : 405|7@0+ (0.005,-0.315) [-0.315|0.32] "rad"  GW
 SG_ ARS_RDI_SNR_Clu_070 : 414|7@0+ (0.5,0) [0|63.5] "dB"  GW
 SG_ ARS_RDI_DynProp_Clu_070 : 423|2@0+ (1,0) [0|3] ""  GW
 SG_ ARS_RDI_Quality_Clu_070 : 421|2@0+ (1,0) [0|3] ""  GW
 SG_ ARS_RDI_DynProp_Clu_071 : 419|2@0+ (1,0) [0|3] ""  GW
 SG_ ARS_RDI_Quality_Clu_071 : 417|2@0+ (1,0) [0|3] ""  GW
 SG_ ARS_RDI_Range_Clu_071 : 431|12@0+ (0.0625,0) [0|255.9375] "m"  GW
 SG_ ARS_RDI_ElevationAng_Clu_064 : 45|7@0+ (0.005,-0.315) [-0.315|0.32] "rad"  GW
 SG_ ARS_RDI_VradRel_Clu_071 : 435|11@0+ (0.1,-120) [-120|84.7] "m/s"  GW
 SG_ ARS_RDI_RCS_Clu_071 : 440|9@0+ (0.2,-51.2) [-51.2|51] "dBsm"  GW
 SG_ ARS_RDI_AzimuthAng_Clu_071 : 463|10@0+ (0.002,-1.022) [-1.022|1.024] "rad"  GW
 SG_ ARS_RDI_ElevationAng_Clu_071 : 469|7@0+ (0.005,-0.315) [-0.315|0.32] "rad"  GW
 SG_ ARS_RDI_SNR_Clu_071 : 478|7@0+ (0.5,0) [0|63.5] "dB"  GW
 SG_ ARS_RDI_MsgCounter_Clu_064_071 : 495|8@0+ (1,0) [0|255] ""  GW
 SG_ ARS_RDI_CRC16_Checksum_Clu_064_0 : 503|16@0+ (1,0) [0|65535] ""  GW
 SG_ ARS_RDI_SNR_Clu_064 : 54|7@0+ (0.5,0) [0|63.5] "dB"  GW
 SG_ ARS_RDI_DynProp_Clu_064 : 63|2@0+ (1,0) [0|3] ""  GW
 SG_ ARS_RDI_Quality_Clu_064 : 61|2@0+ (1,0) [0|3] ""  GW
 SG_ ARS_RDI_DynProp_Clu_065 : 59|2@0+ (1,0) [0|3] ""  GW
 SG_ ARS_RDI_Quality_Clu_065 : 57|2@0+ (1,0) [0|3] ""  GW
 SG_ ARS_RDI_Range_Clu_065 : 71|12@0+ (0.0625,0) [0|255.9375] "m"  GW
 SG_ ARS_RDI_VradRel_Clu_065 : 75|11@0+ (0.1,-120) [-120|84.7] "m/s"  GW
 SG_ ARS_RDI_RCS_Clu_065 : 80|9@0+ (0.2,-51.2) [-51.2|51] "dBsm"  GW
 SG_ ARS_RDI_AzimuthAng_Clu_065 : 103|10@0+ (0.002,-1.022) [-1.022|1.024] "rad"  GW

BO_ 266 ARS_RDI_072_079: 64 FR
 SG_ ARS_RDI_Range_Clu_072 : 7|12@0+ (0.0625,0) [0|255.9375] "m"  GW
 SG_ ARS_RDI_ElevationAng_Clu_073 : 109|7@0+ (0.005,-0.315) [-0.315|0.32] "rad"  GW
 SG_ ARS_RDI_SNR_Clu_073 : 118|7@0+ (0.5,0) [0|63.5] "dB"  GW
 SG_ ARS_RDI_Range_Clu_074 : 127|12@0+ (0.0625,0) [0|255.9375] "m"  GW
 SG_ ARS_RDI_VradRel_Clu_072 : 11|11@0+ (0.1,-120) [-120|84.7] "m/s"  GW
 SG_ ARS_RDI_VradRel_Clu_074 : 131|11@0+ (0.1,-120) [-120|84.7] "m/s"  GW
 SG_ ARS_RDI_RCS_Clu_074 : 136|9@0+ (0.2,-51.2) [-51.2|51] "dBsm"  GW
 SG_ ARS_RDI_AzimuthAng_Clu_074 : 159|10@0+ (0.002,-1.022) [-1.022|1.024] "rad"  GW
 SG_ ARS_RDI_ElevationAng_Clu_074 : 165|7@0+ (0.005,-0.315) [-0.315|0.32] "rad"  GW
 SG_ ARS_RDI_SNR_Clu_074 : 174|7@0+ (0.5,0) [0|63.5] "dB"  GW
 SG_ ARS_RDI_DynProp_Clu_074 : 183|2@0+ (1,0) [0|3] ""  GW
 SG_ ARS_RDI_Quality_Clu_074 : 181|2@0+ (1,0) [0|3] ""  GW
 SG_ ARS_RDI_DynProp_Clu_075 : 179|2@0+ (1,0) [0|3] ""  GW
 SG_ ARS_RDI_Quality_Clu_075 : 177|2@0+ (1,0) [0|3] ""  GW
 SG_ ARS_RDI_Range_Clu_075 : 191|12@0+ (0.0625,0) [0|255.9375] "m"  GW
 SG_ ARS_RDI_VradRel_Clu_075 : 195|11@0+ (0.1,-120) [-120|84.7] "m/s"  GW
 SG_ ARS_RDI_RCS_Clu_075 : 200|9@0+ (0.2,-51.2) [-51.2|51] "dBsm"  GW
 SG_ ARS_RDI_AzimuthAng_Clu_075 : 223|10@0+ (0.002,-1.022) [-1.022|1.024] "rad"  GW
 SG_ ARS_RDI_ElevationAng_Clu_075 : 229|7@0+ (0.005,-0.315) [-0.315|0.32] "rad"  GW
 SG_ ARS_RDI_SNR_Clu_075 : 238|7@0+ (0.5,0) [0|63.5] "dB"  GW
 SG_ ARS_RDI_RCS_Clu_072 : 16|9@0+ (0.2,-51.2) [-51.2|51] "dBsm"  GW
 SG_ ARS_RDI_Range_Clu_076 : 247|12@0+ (0.0625,0) [0|255.9375] "m"  GW
 SG_ ARS_RDI_VradRel_Clu_076 : 251|11@0+ (0.1,-120) [-120|84.7] "m/s"  GW
 SG_ ARS_RDI_RCS_Clu_076 : 256|9@0+ (0.2,-51.2) [-51.2|51] "dBsm"  GW
 SG_ ARS_RDI_AzimuthAng_Clu_076 : 279|10@0+ (0.002,-1.022) [-1.022|1.024] "rad"  GW
 SG_ ARS_RDI_ElevationAng_Clu_076 : 285|7@0+ (0.005,-0.315) [-0.315|0.32] "rad"  GW
 SG_ ARS_RDI_SNR_Clu_076 : 294|7@0+ (0.5,0) [0|63.5] "dB"  GW
 SG_ ARS_RDI_DynProp_Clu_076 : 303|2@0+ (1,0) [0|3] ""  GW
 SG_ ARS_RDI_Quality_Clu_076 : 301|2@0+ (1,0) [0|3] ""  GW
 SG_ ARS_RDI_DynProp_Clu_077 : 299|2@0+ (1,0) [0|3] ""  GW
 SG_ ARS_RDI_Quality_Clu_077 : 297|2@0+ (1,0) [0|3] ""  GW
 SG_ ARS_RDI_Range_Clu_077 : 311|12@0+ (0.0625,0) [0|255.9375] "m"  GW
 SG_ ARS_RDI_VradRel_Clu_077 : 315|11@0+ (0.1,-120) [-120|84.7] "m/s"  GW
 SG_ ARS_RDI_RCS_Clu_077 : 320|9@0+ (0.2,-51.2) [-51.2|51] "dBsm"  GW
 SG_ ARS_RDI_AzimuthAng_Clu_072 : 39|10@0+ (0.002,-1.022) [-1.022|1.024] "rad"  GW
 SG_ ARS_RDI_AzimuthAng_Clu_077 : 343|10@0+ (0.002,-1.022) [-1.022|1.024] "rad"  GW
 SG_ ARS_RDI_ElevationAng_Clu_077 : 349|7@0+ (0.005,-0.315) [-0.315|0.32] "rad"  GW
 SG_ ARS_RDI_SNR_Clu_077 : 358|7@0+ (0.5,0) [0|63.5] "dB"  GW
 SG_ ARS_RDI_Range_Clu_078 : 367|12@0+ (0.0625,0) [0|255.9375] "m"  GW
 SG_ ARS_RDI_VradRel_Clu_078 : 371|11@0+ (0.1,-120) [-120|84.7] "m/s"  GW
 SG_ ARS_RDI_RCS_Clu_078 : 376|9@0+ (0.2,-51.2) [-51.2|51] "dBsm"  GW
 SG_ ARS_RDI_AzimuthAng_Clu_078 : 399|10@0+ (0.002,-1.022) [-1.022|1.024] "rad"  GW
 SG_ ARS_RDI_ElevationAng_Clu_078 : 405|7@0+ (0.005,-0.315) [-0.315|0.32] "rad"  GW
 SG_ ARS_RDI_SNR_Clu_078 : 414|7@0+ (0.5,0) [0|63.5] "dB"  GW
 SG_ ARS_RDI_DynProp_Clu_078 : 423|2@0+ (1,0) [0|3] ""  GW
 SG_ ARS_RDI_Quality_Clu_078 : 421|2@0+ (1,0) [0|3] ""  GW
 SG_ ARS_RDI_DynProp_Clu_079 : 419|2@0+ (1,0) [0|3] ""  GW
 SG_ ARS_RDI_Quality_Clu_079 : 417|2@0+ (1,0) [0|3] ""  GW
 SG_ ARS_RDI_Range_Clu_079 : 431|12@0+ (0.0625,0) [0|255.9375] "m"  GW
 SG_ ARS_RDI_ElevationAng_Clu_072 : 45|7@0+ (0.005,-0.315) [-0.315|0.32] "rad"  GW
 SG_ ARS_RDI_VradRel_Clu_079 : 435|11@0+ (0.1,-120) [-120|84.7] "m/s"  GW
 SG_ ARS_RDI_RCS_Clu_079 : 440|9@0+ (0.2,-51.2) [-51.2|51] "dBsm"  GW
 SG_ ARS_RDI_AzimuthAng_Clu_079 : 463|10@0+ (0.002,-1.022) [-1.022|1.024] "rad"  GW
 SG_ ARS_RDI_ElevationAng_Clu_079 : 469|7@0+ (0.005,-0.315) [-0.315|0.32] "rad"  GW
 SG_ ARS_RDI_SNR_Clu_079 : 478|7@0+ (0.5,0) [0|63.5] "dB"  GW
 SG_ ARS_RDI_MsgCounter_Clu_072_079 : 495|8@0+ (1,0) [0|255] ""  GW
 SG_ ARS_RDI_CRC16_Checksum_Clu_072_0 : 503|16@0+ (1,0) [0|65535] ""  GW
 SG_ ARS_RDI_SNR_Clu_072 : 54|7@0+ (0.5,0) [0|63.5] "dB"  GW
 SG_ ARS_RDI_DynProp_Clu_072 : 63|2@0+ (1,0) [0|3] ""  GW
 SG_ ARS_RDI_Quality_Clu_072 : 61|2@0+ (1,0) [0|3] ""  GW
 SG_ ARS_RDI_DynProp_Clu_073 : 59|2@0+ (1,0) [0|3] ""  GW
 SG_ ARS_RDI_Quality_Clu_073 : 57|2@0+ (1,0) [0|3] ""  GW
 SG_ ARS_RDI_Range_Clu_073 : 71|12@0+ (0.0625,0) [0|255.9375] "m"  GW
 SG_ ARS_RDI_VradRel_Clu_073 : 75|11@0+ (0.1,-120) [-120|84.7] "m/s"  GW
 SG_ ARS_RDI_RCS_Clu_073 : 80|9@0+ (0.2,-51.2) [-51.2|51] "dBsm"  GW
 SG_ ARS_RDI_AzimuthAng_Clu_073 : 103|10@0+ (0.002,-1.022) [-1.022|1.024] "rad"  GW

BO_ 267 ARS_RDI_080_087: 64 FR
 SG_ ARS_RDI_Range_Clu_080 : 7|12@0+ (0.0625,0) [0|255.9375] "m"  GW
 SG_ ARS_RDI_ElevationAng_Clu_081 : 109|7@0+ (0.005,-0.315) [-0.315|0.32] "rad"  GW
 SG_ ARS_RDI_SNR_Clu_081 : 118|7@0+ (0.5,0) [0|63.5] "dB"  GW
 SG_ ARS_RDI_Range_Clu_082 : 127|12@0+ (0.0625,0) [0|255.9375] "m"  GW
 SG_ ARS_RDI_VradRel_Clu_080 : 11|11@0+ (0.1,-120) [-120|84.7] "m/s"  GW
 SG_ ARS_RDI_VradRel_Clu_082 : 131|11@0+ (0.1,-120) [-120|84.7] "m/s"  GW
 SG_ ARS_RDI_RCS_Clu_082 : 136|9@0+ (0.2,-51.2) [-51.2|51] "dBsm"  GW
 SG_ ARS_RDI_AzimuthAng_Clu_082 : 159|10@0+ (0.002,-1.022) [-1.022|1.024] "rad"  GW
 SG_ ARS_RDI_ElevationAng_Clu_082 : 165|7@0+ (0.005,-0.315) [-0.315|0.32] "rad"  GW
 SG_ ARS_RDI_SNR_Clu_082 : 174|7@0+ (0.5,0) [0|63.5] "dB"  GW
 SG_ ARS_RDI_DynProp_Clu_082 : 183|2@0+ (1,0) [0|3] ""  GW
 SG_ ARS_RDI_Quality_Clu_082 : 181|2@0+ (1,0) [0|3] ""  GW
 SG_ ARS_RDI_DynProp_Clu_083 : 179|2@0+ (1,0) [0|3] ""  GW
 SG_ ARS_RDI_Quality_Clu_083 : 177|2@0+ (1,0) [0|3] ""  GW
 SG_ ARS_RDI_Range_Clu_083 : 191|12@0+ (0.0625,0) [0|255.9375] "m"  GW
 SG_ ARS_RDI_VradRel_Clu_083 : 195|11@0+ (0.1,-120) [-120|84.7] "m/s"  GW
 SG_ ARS_RDI_RCS_Clu_083 : 200|9@0+ (0.2,-51.2) [-51.2|51] "dBsm"  GW
 SG_ ARS_RDI_AzimuthAng_Clu_083 : 223|10@0+ (0.002,-1.022) [-1.022|1.024] "rad"  GW
 SG_ ARS_RDI_ElevationAng_Clu_083 : 229|7@0+ (0.005,-0.315) [-0.315|0.32] "rad"  GW
 SG_ ARS_RDI_SNR_Clu_083 : 238|7@0+ (0.5,0) [0|63.5] "dB"  GW
 SG_ ARS_RDI_RCS_Clu_080 : 16|9@0+ (0.2,-51.2) [-51.2|51] "dBsm"  GW
 SG_ ARS_RDI_Range_Clu_084 : 247|12@0+ (0.0625,0) [0|255.9375] "m"  GW
 SG_ ARS_RDI_VradRel_Clu_084 : 251|11@0+ (0.1,-120) [-120|84.7] "m/s"  GW
 SG_ ARS_RDI_RCS_Clu_084 : 256|9@0+ (0.2,-51.2) [-51.2|51] "dBsm"  GW
 SG_ ARS_RDI_AzimuthAng_Clu_084 : 279|10@0+ (0.002,-1.022) [-1.022|1.024] "rad"  GW
 SG_ ARS_RDI_ElevationAng_Clu_084 : 285|7@0+ (0.005,-0.315) [-0.315|0.32] "rad"  GW
 SG_ ARS_RDI_SNR_Clu_084 : 294|7@0+ (0.5,0) [0|63.5] "dB"  GW
 SG_ ARS_RDI_DynProp_Clu_084 : 303|2@0+ (1,0) [0|3] ""  GW
 SG_ ARS_RDI_Quality_Clu_084 : 301|2@0+ (1,0) [0|3] ""  GW
 SG_ ARS_RDI_DynProp_Clu_085 : 299|2@0+ (1,0) [0|3] ""  GW
 SG_ ARS_RDI_Quality_Clu_085 : 297|2@0+ (1,0) [0|3] ""  GW
 SG_ ARS_RDI_Range_Clu_085 : 311|12@0+ (0.0625,0) [0|255.9375] "m"  GW
 SG_ ARS_RDI_VradRel_Clu_085 : 315|11@0+ (0.1,-120) [-120|84.7] "m/s"  GW
 SG_ ARS_RDI_RCS_Clu_085 : 320|9@0+ (0.2,-51.2) [-51.2|51] "dBsm"  GW
 SG_ ARS_RDI_AzimuthAng_Clu_080 : 39|10@0+ (0.002,-1.022) [-1.022|1.024] "rad"  GW
 SG_ ARS_RDI_AzimuthAng_Clu_085 : 343|10@0+ (0.002,-1.022) [-1.022|1.024] "rad"  GW
 SG_ ARS_RDI_ElevationAng_Clu_085 : 349|7@0+ (0.005,-0.315) [-0.315|0.32] "rad"  GW
 SG_ ARS_RDI_SNR_Clu_085 : 358|7@0+ (0.5,0) [0|63.5] "dB"  GW
 SG_ ARS_RDI_Range_Clu_086 : 367|12@0+ (0.0625,0) [0|255.9375] "m"  GW
 SG_ ARS_RDI_VradRel_Clu_086 : 371|11@0+ (0.1,-120) [-120|84.7] "m/s"  GW
 SG_ ARS_RDI_RCS_Clu_086 : 376|9@0+ (0.2,-51.2) [-51.2|51] "dBsm"  GW
 SG_ ARS_RDI_AzimuthAng_Clu_086 : 399|10@0+ (0.002,-1.022) [-1.022|1.024] "rad"  GW
 SG_ ARS_RDI_ElevationAng_Clu_086 : 405|7@0+ (0.005,-0.315) [-0.315|0.32] "rad"  GW
 SG_ ARS_RDI_SNR_Clu_086 : 414|7@0+ (0.5,0) [0|63.5] "dB"  GW
 SG_ ARS_RDI_DynProp_Clu_086 : 423|2@0+ (1,0) [0|3] ""  GW
 SG_ ARS_RDI_Quality_Clu_086 : 421|2@0+ (1,0) [0|3] ""  GW
 SG_ ARS_RDI_DynProp_Clu_087 : 419|2@0+ (1,0) [0|3] ""  GW
 SG_ ARS_RDI_Quality_Clu_087 : 417|2@0+ (1,0) [0|3] ""  GW
 SG_ ARS_RDI_Range_Clu_087 : 431|12@0+ (0.0625,0) [0|255.9375] "m"  GW
 SG_ ARS_RDI_ElevationAng_Clu_080 : 45|7@0+ (0.005,-0.315) [-0.315|0.32] "rad"  GW
 SG_ ARS_RDI_VradRel_Clu_087 : 435|11@0+ (0.1,-120) [-120|84.7] "m/s"  GW
 SG_ ARS_RDI_RCS_Clu_087 : 440|9@0+ (0.2,-51.2) [-51.2|51] "dBsm"  GW
 SG_ ARS_RDI_AzimuthAng_Clu_087 : 463|10@0+ (0.002,-1.022) [-1.022|1.024] "rad"  GW
 SG_ ARS_RDI_ElevationAng_Clu_087 : 469|7@0+ (0.005,-0.315) [-0.315|0.32] "rad"  GW
 SG_ ARS_RDI_SNR_Clu_087 : 478|7@0+ (0.5,0) [0|63.5] "dB"  GW
 SG_ ARS_RDI_MsgCounter_Clu_080_087 : 495|8@0+ (1,0) [0|255] ""  GW
 SG_ ARS_RDI_CRC16_Checksum_Clu_080_0 : 503|16@0+ (1,0) [0|65535] ""  GW
 SG_ ARS_RDI_SNR_Clu_080 : 54|7@0+ (0.5,0) [0|63.5] "dB"  GW
 SG_ ARS_RDI_DynProp_Clu_080 : 63|2@0+ (1,0) [0|3] ""  GW
 SG_ ARS_RDI_Quality_Clu_080 : 61|2@0+ (1,0) [0|3] ""  GW
 SG_ ARS_RDI_DynProp_Clu_081 : 59|2@0+ (1,0) [0|3] ""  GW
 SG_ ARS_RDI_Quality_Clu_081 : 57|2@0+ (1,0) [0|3] ""  GW
 SG_ ARS_RDI_Range_Clu_081 : 71|12@0+ (0.0625,0) [0|255.9375] "m"  GW
 SG_ ARS_RDI_VradRel_Clu_081 : 75|11@0+ (0.1,-120) [-120|84.7] "m/s"  GW
 SG_ ARS_RDI_RCS_Clu_081 : 80|9@0+ (0.2,-51.2) [-51.2|51] "dBsm"  GW
 SG_ ARS_RDI_AzimuthAng_Clu_081 : 103|10@0+ (0.002,-1.022) [-1.022|1.024] "rad"  GW

BO_ 268 ARS_RDI_088_095: 64 FR
 SG_ ARS_RDI_Range_Clu_088 : 7|12@0+ (0.0625,0) [0|255.9375] "m"  GW
 SG_ ARS_RDI_ElevationAng_Clu_089 : 109|7@0+ (0.005,-0.315) [-0.315|0.32] "rad"  GW
 SG_ ARS_RDI_SNR_Clu_089 : 118|7@0+ (0.5,0) [0|63.5] "dB"  GW
 SG_ ARS_RDI_Range_Clu_090 : 127|12@0+ (0.0625,0) [0|255.9375] "m"  GW
 SG_ ARS_RDI_VradRel_Clu_088 : 11|11@0+ (0.1,-120) [-120|84.7] "m/s"  GW
 SG_ ARS_RDI_VradRel_Clu_090 : 131|11@0+ (0.1,-120) [-120|84.7] "m/s"  GW
 SG_ ARS_RDI_RCS_Clu_090 : 136|9@0+ (0.2,-51.2) [-51.2|51] "dBsm"  GW
 SG_ ARS_RDI_AzimuthAng_Clu_090 : 159|10@0+ (0.002,-1.022) [-1.022|1.024] "rad"  GW
 SG_ ARS_RDI_ElevationAng_Clu_090 : 165|7@0+ (0.005,-0.315) [-0.315|0.32] "rad"  GW
 SG_ ARS_RDI_SNR_Clu_090 : 174|7@0+ (0.5,0) [0|63.5] "dB"  GW
 SG_ ARS_RDI_DynProp_Clu_090 : 183|2@0+ (1,0) [0|3] ""  GW
 SG_ ARS_RDI_Quality_Clu_090 : 181|2@0+ (1,0) [0|3] ""  GW
 SG_ ARS_RDI_DynProp_Clu_091 : 179|2@0+ (1,0) [0|3] ""  GW
 SG_ ARS_RDI_Quality_Clu_091 : 177|2@0+ (1,0) [0|3] ""  GW
 SG_ ARS_RDI_Range_Clu_091 : 191|12@0+ (0.0625,0) [0|255.9375] "m"  GW
 SG_ ARS_RDI_VradRel_Clu_091 : 195|11@0+ (0.1,-120) [-120|84.7] "m/s"  GW
 SG_ ARS_RDI_RCS_Clu_091 : 200|9@0+ (0.2,-51.2) [-51.2|51] "dBsm"  GW
 SG_ ARS_RDI_AzimuthAng_Clu_091 : 223|10@0+ (0.002,-1.022) [-1.022|1.024] "rad"  GW
 SG_ ARS_RDI_ElevationAng_Clu_091 : 229|7@0+ (0.005,-0.315) [-0.315|0.32] "rad"  GW
 SG_ ARS_RDI_SNR_Clu_091 : 238|7@0+ (0.5,0) [0|63.5] "dB"  GW
 SG_ ARS_RDI_RCS_Clu_088 : 16|9@0+ (0.2,-51.2) [-51.2|51] "dBsm"  GW
 SG_ ARS_RDI_Range_Clu_092 : 247|12@0+ (0.0625,0) [0|255.9375] "m"  GW
 SG_ ARS_RDI_VradRel_Clu_092 : 251|11@0+ (0.1,-120) [-120|84.7] "m/s"  GW
 SG_ ARS_RDI_RCS_Clu_092 : 256|9@0+ (0.2,-51.2) [-51.2|51] "dBsm"  GW
 SG_ ARS_RDI_AzimuthAng_Clu_092 : 279|10@0+ (0.002,-1.022) [-1.022|1.024] "rad"  GW
 SG_ ARS_RDI_ElevationAng_Clu_092 : 285|7@0+ (0.005,-0.315) [-0.315|0.32] "rad"  GW
 SG_ ARS_RDI_SNR_Clu_092 : 294|7@0+ (0.5,0) [0|63.5] "dB"  GW
 SG_ ARS_RDI_DynProp_Clu_092 : 303|2@0+ (1,0) [0|3] ""  GW
 SG_ ARS_RDI_Quality_Clu_092 : 301|2@0+ (1,0) [0|3] ""  GW
 SG_ ARS_RDI_DynProp_Clu_093 : 299|2@0+ (1,0) [0|3] ""  GW
 SG_ ARS_RDI_Quality_Clu_093 : 297|2@0+ (1,0) [0|3] ""  GW
 SG_ ARS_RDI_Range_Clu_093 : 311|12@0+ (0.0625,0) [0|255.9375] "m"  GW
 SG_ ARS_RDI_VradRel_Clu_093 : 315|11@0+ (0.1,-120) [-120|84.7] "m/s"  GW
 SG_ ARS_RDI_RCS_Clu_093 : 320|9@0+ (0.2,-51.2) [-51.2|51] "dBsm"  GW
 SG_ ARS_RDI_AzimuthAng_Clu_088 : 39|10@0+ (0.002,-1.022) [-1.022|1.024] "rad"  GW
 SG_ ARS_RDI_AzimuthAng_Clu_093 : 343|10@0+ (0.002,-1.022) [-1.022|1.024] "rad"  GW
 SG_ ARS_RDI_ElevationAng_Clu_093 : 349|7@0+ (0.005,-0.315) [-0.315|0.32] "rad"  GW
 SG_ ARS_RDI_SNR_Clu_093 : 358|7@0+ (0.5,0) [0|63.5] "dB"  GW
 SG_ ARS_RDI_Range_Clu_094 : 367|12@0+ (0.0625,0) [0|255.9375] "m"  GW
 SG_ ARS_RDI_VradRel_Clu_094 : 371|11@0+ (0.1,-120) [-120|84.7] "m/s"  GW
 SG_ ARS_RDI_RCS_Clu_094 : 376|9@0+ (0.2,-51.2) [-51.2|51] "dBsm"  GW
 SG_ ARS_RDI_AzimuthAng_Clu_094 : 399|10@0+ (0.002,-1.022) [-1.022|1.024] "rad"  GW
 SG_ ARS_RDI_ElevationAng_Clu_094 : 405|7@0+ (0.005,-0.315) [-0.315|0.32] "rad"  GW
 SG_ ARS_RDI_SNR_Clu_094 : 414|7@0+ (0.5,0) [0|63.5] "dB"  GW
 SG_ ARS_RDI_DynProp_Clu_094 : 423|2@0+ (1,0) [0|3] ""  GW
 SG_ ARS_RDI_Quality_Clu_094 : 421|2@0+ (1,0) [0|3] ""  GW
 SG_ ARS_RDI_DynProp_Clu_095 : 419|2@0+ (1,0) [0|3] ""  GW
 SG_ ARS_RDI_Quality_Clu_095 : 417|2@0+ (1,0) [0|3] ""  GW
 SG_ ARS_RDI_Range_Clu_095 : 431|12@0+ (0.0625,0) [0|255.9375] "m"  GW
 SG_ ARS_RDI_ElevationAng_Clu_088 : 45|7@0+ (0.005,-0.315) [-0.315|0.32] "rad"  GW
 SG_ ARS_RDI_VradRel_Clu_095 : 435|11@0+ (0.1,-120) [-120|84.7] "m/s"  GW
 SG_ ARS_RDI_RCS_Clu_095 : 440|9@0+ (0.2,-51.2) [-51.2|51] "dBsm"  GW
 SG_ ARS_RDI_AzimuthAng_Clu_095 : 463|10@0+ (0.002,-1.022) [-1.022|1.024] "rad"  GW
 SG_ ARS_RDI_ElevationAng_Clu_095 : 469|7@0+ (0.005,-0.315) [-0.315|0.32] "rad"  GW
 SG_ ARS_RDI_SNR_Clu_095 : 478|7@0+ (0.5,0) [0|63.5] "dB"  GW
 SG_ ARS_RDI_MsgCounter_Clu_088_095 : 495|8@0+ (1,0) [0|255] ""  GW
 SG_ ARS_RDI_CRC16_Checksum_Clu_088_0 : 503|16@0+ (1,0) [0|65535] ""  GW
 SG_ ARS_RDI_SNR_Clu_088 : 54|7@0+ (0.5,0) [0|63.5] "dB"  GW
 SG_ ARS_RDI_DynProp_Clu_088 : 63|2@0+ (1,0) [0|3] ""  GW
 SG_ ARS_RDI_Quality_Clu_088 : 61|2@0+ (1,0) [0|3] ""  GW
 SG_ ARS_RDI_DynProp_Clu_089 : 59|2@0+ (1,0) [0|3] ""  GW
 SG_ ARS_RDI_Quality_Clu_089 : 57|2@0+ (1,0) [0|3] ""  GW
 SG_ ARS_RDI_Range_Clu_089 : 71|12@0+ (0.0625,0) [0|255.9375] "m"  GW
 SG_ ARS_RDI_VradRel_Clu_089 : 75|11@0+ (0.1,-120) [-120|84.7] "m/s"  GW
 SG_ ARS_RDI_RCS_Clu_089 : 80|9@0+ (0.2,-51.2) [-51.2|51] "dBsm"  GW
 SG_ ARS_RDI_AzimuthAng_Clu_089 : 103|10@0+ (0.002,-1.022) [-1.022|1.024] "rad"  GW

BO_ 269 ARS_RDI_096_103: 64 FR
 SG_ ARS_RDI_Range_Clu_096 : 7|12@0+ (0.0625,0) [0|255.9375] "m"  GW
 SG_ ARS_RDI_ElevationAng_Clu_097 : 109|7@0+ (0.005,-0.315) [-0.315|0.32] "rad"  GW
 SG_ ARS_RDI_SNR_Clu_097 : 118|7@0+ (0.5,0) [0|63.5] "dB"  GW
 SG_ ARS_RDI_Range_Clu_098 : 127|12@0+ (0.0625,0) [0|255.9375] "m"  GW
 SG_ ARS_RDI_VradRel_Clu_096 : 11|11@0+ (0.1,-120) [-120|84.7] "m/s"  GW
 SG_ ARS_RDI_VradRel_Clu_098 : 131|11@0+ (0.1,-120) [-120|84.7] "m/s"  GW
 SG_ ARS_RDI_RCS_Clu_098 : 136|9@0+ (0.2,-51.2) [-51.2|51] "dBsm"  GW
 SG_ ARS_RDI_AzimuthAng_Clu_098 : 159|10@0+ (0.002,-1.022) [-1.022|1.024] "rad"  GW
 SG_ ARS_RDI_ElevationAng_Clu_098 : 165|7@0+ (0.005,-0.315) [-0.315|0.32] "rad"  GW
 SG_ ARS_RDI_SNR_Clu_098 : 174|7@0+ (0.5,0) [0|63.5] "dB"  GW
 SG_ ARS_RDI_DynProp_Clu_098 : 183|2@0+ (1,0) [0|3] ""  GW
 SG_ ARS_RDI_Quality_Clu_098 : 181|2@0+ (1,0) [0|3] ""  GW
 SG_ ARS_RDI_DynProp_Clu_099 : 179|2@0+ (1,0) [0|3] ""  GW
 SG_ ARS_RDI_Quality_Clu_099 : 177|2@0+ (1,0) [0|3] ""  GW
 SG_ ARS_RDI_Range_Clu_099 : 191|12@0+ (0.0625,0) [0|255.9375] "m"  GW
 SG_ ARS_RDI_VradRel_Clu_099 : 195|11@0+ (0.1,-120) [-120|84.7] "m/s"  GW
 SG_ ARS_RDI_RCS_Clu_099 : 200|9@0+ (0.2,-51.2) [-51.2|51] "dBsm"  GW
 SG_ ARS_RDI_AzimuthAng_Clu_099 : 223|10@0+ (0.002,-1.022) [-1.022|1.024] "rad"  GW
 SG_ ARS_RDI_ElevationAng_Clu_099 : 229|7@0+ (0.005,-0.315) [-0.315|0.32] "rad"  GW
 SG_ ARS_RDI_SNR_Clu_099 : 238|7@0+ (0.5,0) [0|63.5] "dB"  GW
 SG_ ARS_RDI_RCS_Clu_096 : 16|9@0+ (0.2,-51.2) [-51.2|51] "dBsm"  GW
 SG_ ARS_RDI_Range_Clu_100 : 247|12@0+ (0.0625,0) [0|255.9375] "m"  GW
 SG_ ARS_RDI_VradRel_Clu_100 : 251|11@0+ (0.1,-120) [-120|84.7] "m/s"  GW
 SG_ ARS_RDI_RCS_Clu_100 : 256|9@0+ (0.2,-51.2) [-51.2|51] "dBsm"  GW
 SG_ ARS_RDI_AzimuthAng_Clu_100 : 279|10@0+ (0.002,-1.022) [-1.022|1.024] "rad"  GW
 SG_ ARS_RDI_ElevationAng_Clu_100 : 285|7@0+ (0.005,-0.315) [-0.315|0.32] "rad"  GW
 SG_ ARS_RDI_SNR_Clu_100 : 294|7@0+ (0.5,0) [0|63.5] "dB"  GW
 SG_ ARS_RDI_DynProp_Clu_100 : 303|2@0+ (1,0) [0|3] ""  GW
 SG_ ARS_RDI_Quality_Clu_100 : 301|2@0+ (1,0) [0|3] ""  GW
 SG_ ARS_RDI_DynProp_Clu_101 : 299|2@0+ (1,0) [0|3] ""  GW
 SG_ ARS_RDI_Quality_Clu_101 : 297|2@0+ (1,0) [0|3] ""  GW
 SG_ ARS_RDI_Range_Clu_101 : 311|12@0+ (0.0625,0) [0|255.9375] "m"  GW
 SG_ ARS_RDI_VradRel_Clu_101 : 315|11@0+ (0.1,-120) [-120|84.7] "m/s"  GW
 SG_ ARS_RDI_RCS_Clu_101 : 320|9@0+ (0.2,-51.2) [-51.2|51] "dBsm"  GW
 SG_ ARS_RDI_AzimuthAng_Clu_096 : 39|10@0+ (0.002,-1.022) [-1.022|1.024] "rad"  GW
 SG_ ARS_RDI_AzimuthAng_Clu_101 : 343|10@0+ (0.002,-1.022) [-1.022|1.024] "rad"  GW
 SG_ ARS_RDI_ElevationAng_Clu_101 : 349|7@0+ (0.005,-0.315) [-0.315|0.32] "rad"  GW
 SG_ ARS_RDI_SNR_Clu_101 : 358|7@0+ (0.5,0) [0|63.5] "dB"  GW
 SG_ ARS_RDI_Range_Clu_102 : 367|12@0+ (0.0625,0) [0|255.9375] "m"  GW
 SG_ ARS_RDI_VradRel_Clu_102 : 371|11@0+ (0.1,-120) [-120|84.7] "m/s"  GW
 SG_ ARS_RDI_RCS_Clu_102 : 376|9@0+ (0.2,-51.2) [-51.2|51] "dBsm"  GW
 SG_ ARS_RDI_AzimuthAng_Clu_102 : 399|10@0+ (0.002,-1.022) [-1.022|1.024] "rad"  GW
 SG_ ARS_RDI_ElevationAng_Clu_102 : 405|7@0+ (0.005,-0.315) [-0.315|0.32] "rad"  GW
 SG_ ARS_RDI_SNR_Clu_102 : 414|7@0+ (0.5,0) [0|63.5] "dB"  GW
 SG_ ARS_RDI_DynProp_Clu_102 : 423|2@0+ (1,0) [0|3] ""  GW
 SG_ ARS_RDI_Quality_Clu_102 : 421|2@0+ (1,0) [0|3] ""  GW
 SG_ ARS_RDI_DynProp_Clu_103 : 419|2@0+ (1,0) [0|3] ""  GW
 SG_ ARS_RDI_Quality_Clu_103 : 417|2@0+ (1,0) [0|3] ""  GW
 SG_ ARS_RDI_Range_Clu_103 : 431|12@0+ (0.0625,0) [0|255.9375] "m"  GW
 SG_ ARS_RDI_ElevationAng_Clu_096 : 45|7@0+ (0.005,-0.315) [-0.315|0.32] "rad"  GW
 SG_ ARS_RDI_VradRel_Clu_103 : 435|11@0+ (0.1,-120) [-120|84.7] "m/s"  GW
 SG_ ARS_RDI_RCS_Clu_103 : 440|9@0+ (0.2,-51.2) [-51.2|51] "dBsm"  GW
 SG_ ARS_RDI_AzimuthAng_Clu_103 : 463|10@0+ (0.002,-1.022) [-1.022|1.024] "rad"  GW
 SG_ ARS_RDI_ElevationAng_Clu_103 : 469|7@0+ (0.005,-0.315) [-0.315|0.32] "rad"  GW
 SG_ ARS_RDI_SNR_Clu_103 : 478|7@0+ (0.5,0) [0|63.5] "dB"  GW
 SG_ ARS_RDI_MsgCounter_Clu_096_103 : 495|8@0+ (1,0) [0|255] ""  GW
 SG_ ARS_RDI_CRC16_Checksum_Clu_096_1 : 503|16@0+ (1,0) [0|65535] ""  GW
 SG_ ARS_RDI_SNR_Clu_096 : 54|7@0+ (0.5,0) [0|63.5] "dB"  GW
 SG_ ARS_RDI_DynProp_Clu_096 : 63|2@0+ (1,0) [0|3] ""  GW
 SG_ ARS_RDI_Quality_Clu_096 : 61|2@0+ (1,0) [0|3] ""  GW
 SG_ ARS_RDI_DynProp_Clu_097 : 59|2@0+ (1,0) [0|3] ""  GW
 SG_ ARS_RDI_Quality_Clu_097 : 57|2@0+ (1,0) [0|3] ""  GW
 SG_ ARS_RDI_Range_Clu_097 : 71|12@0+ (0.0625,0) [0|255.9375] "m"  GW
 SG_ ARS_RDI_VradRel_Clu_097 : 75|11@0+ (0.1,-120) [-120|84.7] "m/s"  GW
 SG_ ARS_RDI_RCS_Clu_097 : 80|9@0+ (0.2,-51.2) [-51.2|51] "dBsm"  GW
 SG_ ARS_RDI_AzimuthAng_Clu_097 : 103|10@0+ (0.002,-1.022) [-1.022|1.024] "rad"  GW

BO_ 270 ARS_RDI_104_111: 64 FR
 SG_ ARS_RDI_Range_Clu_104 : 7|12@0+ (0.0625,0) [0|255.9375] "m"  GW
 SG_ ARS_RDI_ElevationAng_Clu_105 : 109|7@0+ (0.005,-0.315) [-0.315|0.32] "rad"  GW
 SG_ ARS_RDI_SNR_Clu_105 : 118|7@0+ (0.5,0) [0|63.5] "dB"  GW
 SG_ ARS_RDI_Range_Clu_106 : 127|12@0+ (0.0625,0) [0|255.9375] "m"  GW
 SG_ ARS_RDI_VradRel_Clu_104 : 11|11@0+ (0.1,-120) [-120|84.7] "m/s"  GW
 SG_ ARS_RDI_VradRel_Clu_106 : 131|11@0+ (0.1,-120) [-120|84.7] "m/s"  GW
 SG_ ARS_RDI_RCS_Clu_106 : 136|9@0+ (0.2,-51.2) [-51.2|51] "dBsm"  GW
 SG_ ARS_RDI_AzimuthAng_Clu_106 : 159|10@0+ (0.002,-1.022) [-1.022|1.024] "rad"  GW
 SG_ ARS_RDI_ElevationAng_Clu_106 : 165|7@0+ (0.005,-0.315) [-0.315|0.32] "rad"  GW
 SG_ ARS_RDI_SNR_Clu_106 : 174|7@0+ (0.5,0) [0|63.5] "dB"  GW
 SG_ ARS_RDI_DynProp_Clu_106 : 183|2@0+ (1,0) [0|3] ""  GW
 SG_ ARS_RDI_Quality_Clu_106 : 181|2@0+ (1,0) [0|3] ""  GW
 SG_ ARS_RDI_DynProp_Clu_107 : 179|2@0+ (1,0) [0|3] ""  GW
 SG_ ARS_RDI_Quality_Clu_107 : 177|2@0+ (1,0) [0|3] ""  GW
 SG_ ARS_RDI_Range_Clu_107 : 191|12@0+ (0.0625,0) [0|255.9375] "m"  GW
 SG_ ARS_RDI_VradRel_Clu_107 : 195|11@0+ (0.1,-120) [-120|84.7] "m/s"  GW
 SG_ ARS_RDI_RCS_Clu_107 : 200|9@0+ (0.2,-51.2) [-51.2|51] "dBsm"  GW
 SG_ ARS_RDI_AzimuthAng_Clu_107 : 223|10@0+ (0.002,-1.022) [-1.022|1.024] "rad"  GW
 SG_ ARS_RDI_ElevationAng_Clu_107 : 229|7@0+ (0.005,-0.315) [-0.315|0.32] "rad"  GW
 SG_ ARS_RDI_SNR_Clu_107 : 238|7@0+ (0.5,0) [0|63.5] "dB"  GW
 SG_ ARS_RDI_RCS_Clu_104 : 16|9@0+ (0.2,-51.2) [-51.2|51] "dBsm"  GW
 SG_ ARS_RDI_Range_Clu_108 : 247|12@0+ (0.0625,0) [0|255.9375] "m"  GW
 SG_ ARS_RDI_VradRel_Clu_108 : 251|11@0+ (0.1,-120) [-120|84.7] "m/s"  GW
 SG_ ARS_RDI_RCS_Clu_108 : 256|9@0+ (0.2,-51.2) [-51.2|51] "dBsm"  GW
 SG_ ARS_RDI_AzimuthAng_Clu_108 : 279|10@0+ (0.002,-1.022) [-1.022|1.024] "rad"  GW
 SG_ ARS_RDI_ElevationAng_Clu_108 : 285|7@0+ (0.005,-0.315) [-0.315|0.32] "rad"  GW
 SG_ ARS_RDI_SNR_Clu_108 : 294|7@0+ (0.5,0) [0|63.5] "dB"  GW
 SG_ ARS_RDI_DynProp_Clu_108 : 303|2@0+ (1,0) [0|3] ""  GW
 SG_ ARS_RDI_Quality_Clu_108 : 301|2@0+ (1,0) [0|3] ""  GW
 SG_ ARS_RDI_DynProp_Clu_109 : 299|2@0+ (1,0) [0|3] ""  GW
 SG_ ARS_RDI_Quality_Clu_109 : 297|2@0+ (1,0) [0|3] ""  GW
 SG_ ARS_RDI_Range_Clu_109 : 311|12@0+ (0.0625,0) [0|255.9375] "m"  GW
 SG_ ARS_RDI_VradRel_Clu_109 : 315|11@0+ (0.1,-120) [-120|84.7] "m/s"  GW
 SG_ ARS_RDI_RCS_Clu_109 : 320|9@0+ (0.2,-51.2) [-51.2|51] "dBsm"  GW
 SG_ ARS_RDI_AzimuthAng_Clu_104 : 39|10@0+ (0.002,-1.022) [-1.022|1.024] "rad"  GW
 SG_ ARS_RDI_AzimuthAng_Clu_109 : 343|10@0+ (0.002,-1.022) [-1.022|1.024] "rad"  GW
 SG_ ARS_RDI_ElevationAng_Clu_109 : 349|7@0+ (0.005,-0.315) [-0.315|0.32] "rad"  GW
 SG_ ARS_RDI_SNR_Clu_109 : 358|7@0+ (0.5,0) [0|63.5] "dB"  GW
 SG_ ARS_RDI_Range_Clu_110 : 367|12@0+ (0.0625,0) [0|255.9375] "m"  GW
 SG_ ARS_RDI_VradRel_Clu_110 : 371|11@0+ (0.1,-120) [-120|84.7] "m/s"  GW
 SG_ ARS_RDI_RCS_Clu_110 : 376|9@0+ (0.2,-51.2) [-51.2|51] "dBsm"  GW
 SG_ ARS_RDI_AzimuthAng_Clu_110 : 399|10@0+ (0.002,-1.022) [-1.022|1.024] "rad"  GW
 SG_ ARS_RDI_ElevationAng_Clu_110 : 405|7@0+ (0.005,-0.315) [-0.315|0.32] "rad"  GW
 SG_ ARS_RDI_SNR_Clu_110 : 414|7@0+ (0.5,0) [0|63.5] "dB"  GW
 SG_ ARS_RDI_DynProp_Clu_110 : 423|2@0+ (1,0) [0|3] ""  GW
 SG_ ARS_RDI_Quality_Clu_110 : 421|2@0+ (1,0) [0|3] ""  GW
 SG_ ARS_RDI_DynProp_Clu_111 : 419|2@0+ (1,0) [0|3] ""  GW
 SG_ ARS_RDI_Quality_Clu_111 : 417|2@0+ (1,0) [0|3] ""  GW
 SG_ ARS_RDI_Range_Clu_111 : 431|12@0+ (0.0625,0) [0|255.9375] "m"  GW
 SG_ ARS_RDI_ElevationAng_Clu_104 : 45|7@0+ (0.005,-0.315) [-0.315|0.32] "rad"  GW
 SG_ ARS_RDI_VradRel_Clu_111 : 435|11@0+ (0.1,-120) [-120|84.7] "m/s"  GW
 SG_ ARS_RDI_RCS_Clu_111 : 440|9@0+ (0.2,-51.2) [-51.2|51] "dBsm"  GW
 SG_ ARS_RDI_AzimuthAng_Clu_111 : 463|10@0+ (0.002,-1.022) [-1.022|1.024] "rad"  GW
 SG_ ARS_RDI_ElevationAng_Clu_111 : 469|7@0+ (0.005,-0.315) [-0.315|0.32] "rad"  GW
 SG_ ARS_RDI_SNR_Clu_111 : 478|7@0+ (0.5,0) [0|63.5] "dB"  GW
 SG_ ARS_RDI_MsgCounter_Clu_104_111 : 495|8@0+ (1,0) [0|255] ""  GW
 SG_ ARS_RDI_CRC16_Checksum_Clu_104_1 : 503|16@0+ (1,0) [0|65535] ""  GW
 SG_ ARS_RDI_SNR_Clu_104 : 54|7@0+ (0.5,0) [0|63.5] "dB"  GW
 SG_ ARS_RDI_DynProp_Clu_104 : 63|2@0+ (1,0) [0|3] ""  GW
 SG_ ARS_RDI_Quality_Clu_104 : 61|2@0+ (1,0) [0|3] ""  GW
 SG_ ARS_RDI_DynProp_Clu_105 : 59|2@0+ (1,0) [0|3] ""  GW
 SG_ ARS_RDI_Quality_Clu_105 : 57|2@0+ (1,0) [0|3] ""  GW
 SG_ ARS_RDI_Range_Clu_105 : 71|12@0+ (0.0625,0) [0|255.9375] "m"  GW
 SG_ ARS_RDI_VradRel_Clu_105 : 75|11@0+ (0.1,-120) [-120|84.7] "m/s"  GW
 SG_ ARS_RDI_RCS_Clu_105 : 80|9@0+ (0.2,-51.2) [-51.2|51] "dBsm"  GW
 SG_ ARS_RDI_AzimuthAng_Clu_105 : 103|10@0+ (0.002,-1.022) [-1.022|1.024] "rad"  GW

BO_ 271 ARS_RDI_112_119: 64 FR
 SG_ ARS_RDI_Range_Clu_112 : 7|12@0+ (0.0625,0) [0|255.9375] "m"  GW
 SG_ ARS_RDI_ElevationAng_Clu_113 : 109|7@0+ (0.005,-0.315) [-0.315|0.32] "rad"  GW
 SG_ ARS_RDI_SNR_Clu_113 : 118|7@0+ (0.5,0) [0|63.5] "dB"  GW
 SG_ ARS_RDI_Range_Clu_114 : 127|12@0+ (0.0625,0) [0|255.9375] "m"  GW
 SG_ ARS_RDI_VradRel_Clu_112 : 11|11@0+ (0.1,-120) [-120|84.7] "m/s"  GW
 SG_ ARS_RDI_VradRel_Clu_114 : 131|11@0+ (0.1,-120) [-120|84.7] "m/s"  GW
 SG_ ARS_RDI_RCS_Clu_114 : 136|9@0+ (0.2,-51.2) [-51.2|51] "dBsm"  GW
 SG_ ARS_RDI_AzimuthAng_Clu_114 : 159|10@0+ (0.002,-1.022) [-1.022|1.024] "rad"  GW
 SG_ ARS_RDI_ElevationAng_Clu_114 : 165|7@0+ (0.005,-0.315) [-0.315|0.32] "rad"  GW
 SG_ ARS_RDI_SNR_Clu_114 : 174|7@0+ (0.5,0) [0|63.5] "dB"  GW
 SG_ ARS_RDI_DynProp_Clu_114 : 183|2@0+ (1,0) [0|3] ""  GW
 SG_ ARS_RDI_Quality_Clu_114 : 181|2@0+ (1,0) [0|3] ""  GW
 SG_ ARS_RDI_DynProp_Clu_115 : 179|2@0+ (1,0) [0|3] ""  GW
 SG_ ARS_RDI_Quality_Clu_115 : 177|2@0+ (1,0) [0|3] ""  GW
 SG_ ARS_RDI_Range_Clu_115 : 191|12@0+ (0.0625,0) [0|255.9375] "m"  GW
 SG_ ARS_RDI_VradRel_Clu_115 : 195|11@0+ (0.1,-120) [-120|84.7] "m/s"  GW
 SG_ ARS_RDI_RCS_Clu_115 : 200|9@0+ (0.2,-51.2) [-51.2|51] "dBsm"  GW
 SG_ ARS_RDI_AzimuthAng_Clu_115 : 223|10@0+ (0.002,-1.022) [-1.022|1.024] "rad"  GW
 SG_ ARS_RDI_ElevationAng_Clu_115 : 229|7@0+ (0.005,-0.315) [-0.315|0.32] "rad"  GW
 SG_ ARS_RDI_SNR_Clu_115 : 238|7@0+ (0.5,0) [0|63.5] "dB"  GW
 SG_ ARS_RDI_RCS_Clu_112 : 16|9@0+ (0.2,-51.2) [-51.2|51] "dBsm"  GW
 SG_ ARS_RDI_Range_Clu_116 : 247|12@0+ (0.0625,0) [0|255.9375] "m"  GW
 SG_ ARS_RDI_VradRel_Clu_116 : 251|11@0+ (0.1,-120) [-120|84.7] "m/s"  GW
 SG_ ARS_RDI_RCS_Clu_116 : 256|9@0+ (0.2,-51.2) [-51.2|51] "dBsm"  GW
 SG_ ARS_RDI_AzimuthAng_Clu_116 : 279|10@0+ (0.002,-1.022) [-1.022|1.024] "rad"  GW
 SG_ ARS_RDI_ElevationAng_Clu_116 : 285|7@0+ (0.005,-0.315) [-0.315|0.32] "rad"  GW
 SG_ ARS_RDI_SNR_Clu_116 : 294|7@0+ (0.5,0) [0|63.5] "dB"  GW
 SG_ ARS_RDI_DynProp_Clu_116 : 303|2@0+ (1,0) [0|3] ""  GW
 SG_ ARS_RDI_Quality_Clu_116 : 301|2@0+ (1,0) [0|3] ""  GW
 SG_ ARS_RDI_DynProp_Clu_117 : 299|2@0+ (1,0) [0|3] ""  GW
 SG_ ARS_RDI_Quality_Clu_117 : 297|2@0+ (1,0) [0|3] ""  GW
 SG_ ARS_RDI_Range_Clu_117 : 311|12@0+ (0.0625,0) [0|255.9375] "m"  GW
 SG_ ARS_RDI_VradRel_Clu_117 : 315|11@0+ (0.1,-120) [-120|84.7] "m/s"  GW
 SG_ ARS_RDI_RCS_Clu_117 : 320|9@0+ (0.2,-51.2) [-51.2|51] "dBsm"  GW
 SG_ ARS_RDI_AzimuthAng_Clu_112 : 39|10@0+ (0.002,-1.022) [-1.022|1.024] "rad"  GW
 SG_ ARS_RDI_AzimuthAng_Clu_117 : 343|10@0+ (0.002,-1.022) [-1.022|1.024] "rad"  GW
 SG_ ARS_RDI_ElevationAng_Clu_117 : 349|7@0+ (0.005,-0.315) [-0.315|0.32] "rad"  GW
 SG_ ARS_RDI_SNR_Clu_117 : 358|7@0+ (0.5,0) [0|63.5] "dB"  GW
 SG_ ARS_RDI_Range_Clu_118 : 367|12@0+ (0.0625,0) [0|255.9375] "m"  GW
 SG_ ARS_RDI_VradRel_Clu_118 : 371|11@0+ (0.1,-120) [-120|84.7] "m/s"  GW
 SG_ ARS_RDI_RCS_Clu_118 : 376|9@0+ (0.2,-51.2) [-51.2|51] "dBsm"  GW
 SG_ ARS_RDI_AzimuthAng_Clu_118 : 399|10@0+ (0.002,-1.022) [-1.022|1.024] "rad"  GW
 SG_ ARS_RDI_ElevationAng_Clu_118 : 405|7@0+ (0.005,-0.315) [-0.315|0.32] "rad"  GW
 SG_ ARS_RDI_SNR_Clu_118 : 414|7@0+ (0.5,0) [0|63.5] "dB"  GW
 SG_ ARS_RDI_DynProp_Clu_118 : 423|2@0+ (1,0) [0|3] ""  GW
 SG_ ARS_RDI_Quality_Clu_118 : 421|2@0+ (1,0) [0|3] ""  GW
 SG_ ARS_RDI_DynProp_Clu_119 : 419|2@0+ (1,0) [0|3] ""  GW
 SG_ ARS_RDI_Quality_Clu_119 : 417|2@0+ (1,0) [0|3] ""  GW
 SG_ ARS_RDI_Range_Clu_119 : 431|12@0+ (0.0625,0) [0|255.9375] "m"  GW
 SG_ ARS_RDI_ElevationAng_Clu_112 : 45|7@0+ (0.005,-0.315) [-0.315|0.32] "rad"  GW
 SG_ ARS_RDI_VradRel_Clu_119 : 435|11@0+ (0.1,-120) [-120|84.7] "m/s"  GW
 SG_ ARS_RDI_RCS_Clu_119 : 440|9@0+ (0.2,-51.2) [-51.2|51] "dBsm"  GW
 SG_ ARS_RDI_AzimuthAng_Clu_119 : 463|10@0+ (0.002,-1.022) [-1.022|1.024] "rad"  GW
 SG_ ARS_RDI_ElevationAng_Clu_119 : 469|7@0+ (0.005,-0.315) [-0.315|0.32] "rad"  GW
 SG_ ARS_RDI_SNR_Clu_119 : 478|7@0+ (0.5,0) [0|63.5] "dB"  GW
 SG_ ARS_RDI_MsgCounter_Clu_112_119 : 495|8@0+ (1,0) [0|255] ""  GW
 SG_ ARS_RDI_CRC16_Checksum_Clu_112_1 : 503|16@0+ (1,0) [0|65535] ""  GW
 SG_ ARS_RDI_SNR_Clu_112 : 54|7@0+ (0.5,0) [0|63.5] "dB"  GW
 SG_ ARS_RDI_DynProp_Clu_112 : 63|2@0+ (1,0) [0|3] ""  GW
 SG_ ARS_RDI_Quality_Clu_112 : 61|2@0+ (1,0) [0|3] ""  GW
 SG_ ARS_RDI_DynProp_Clu_113 : 59|2@0+ (1,0) [0|3] ""  GW
 SG_ ARS_RDI_Quality_Clu_113 : 57|2@0+ (1,0) [0|3] ""  GW
 SG_ ARS_RDI_Range_Clu_113 : 71|12@0+ (0.0625,0) [0|255.9375] "m"  GW
 SG_ ARS_RDI_VradRel_Clu_113 : 75|11@0+ (0.1,-120) [-120|84.7] "m/s"  GW
 SG_ ARS_RDI_RCS_Clu_113 : 80|9@0+ (0.2,-51.2) [-51.2|51] "dBsm"  GW
 SG_ ARS_RDI_AzimuthAng_Clu_113 : 103|10@0+ (0.002,-1.022) [-1.022|1.024] "rad"  GW

BO_ 272 ARS_RDI_120_127: 64 FR
 SG_ ARS_RDI_Range_Clu_120 : 7|12@0+ (0.0625,0) [0|255.9375] "m"  GW
 SG_ ARS_RDI_ElevationAng_Clu_121 : 109|7@0+ (0.005,-0.315) [-0.315|0.32] "rad"  GW
 SG_ ARS_RDI_SNR_Clu_121 : 118|7@0+ (0.5,0) [0|63.5] "dB"  GW
 SG_ ARS_RDI_Range_Clu_122 : 127|12@0+ (0.0625,0) [0|255.9375] "m"  GW
 SG_ ARS_RDI_VradRel_Clu_120 : 11|11@0+ (0.1,-120) [-120|84.7] "m/s"  GW
 SG_ ARS_RDI_VradRel_Clu_122 : 131|11@0+ (0.1,-120) [-120|84.7] "m/s"  GW
 SG_ ARS_RDI_RCS_Clu_122 : 136|9@0+ (0.2,-51.2) [-51.2|51] "dBsm"  GW
 SG_ ARS_RDI_AzimuthAng_Clu_122 : 159|10@0+ (0.002,-1.022) [-1.022|1.024] "rad"  GW
 SG_ ARS_RDI_ElevationAng_Clu_122 : 165|7@0+ (0.005,-0.315) [-0.315|0.32] "rad"  GW
 SG_ ARS_RDI_SNR_Clu_122 : 174|7@0+ (0.5,0) [0|63.5] "dB"  GW
 SG_ ARS_RDI_DynProp_Clu_122 : 183|2@0+ (1,0) [0|3] ""  GW
 SG_ ARS_RDI_Quality_Clu_122 : 181|2@0+ (1,0) [0|3] ""  GW
 SG_ ARS_RDI_DynProp_Clu_123 : 179|2@0+ (1,0) [0|3] ""  GW
 SG_ ARS_RDI_Quality_Clu_123 : 177|2@0+ (1,0) [0|3] ""  GW
 SG_ ARS_RDI_Range_Clu_123 : 191|12@0+ (0.0625,0) [0|255.9375] "m"  GW
 SG_ ARS_RDI_VradRel_Clu_123 : 195|11@0+ (0.1,-120) [-120|84.7] "m/s"  GW
 SG_ ARS_RDI_RCS_Clu_123 : 200|9@0+ (0.2,-51.2) [-51.2|51] "dBsm"  GW
 SG_ ARS_RDI_AzimuthAng_Clu_123 : 223|10@0+ (0.002,-1.022) [-1.022|1.024] "rad"  GW
 SG_ ARS_RDI_ElevationAng_Clu_123 : 229|7@0+ (0.005,-0.315) [-0.315|0.32] "rad"  GW
 SG_ ARS_RDI_SNR_Clu_123 : 238|7@0+ (0.5,0) [0|63.5] "dB"  GW
 SG_ ARS_RDI_RCS_Clu_120 : 16|9@0+ (0.2,-51.2) [-51.2|51] "dBsm"  GW
 SG_ ARS_RDI_Range_Clu_124 : 247|12@0+ (0.0625,0) [0|255.9375] "m"  GW
 SG_ ARS_RDI_VradRel_Clu_124 : 251|11@0+ (0.1,-120) [-120|84.7] "m/s"  GW
 SG_ ARS_RDI_RCS_Clu_124 : 256|9@0+ (0.2,-51.2) [-51.2|51] "dBsm"  GW
 SG_ ARS_RDI_AzimuthAng_Clu_124 : 279|10@0+ (0.002,-1.022) [-1.022|1.024] "rad"  GW
 SG_ ARS_RDI_ElevationAng_Clu_124 : 285|7@0+ (0.005,-0.315) [-0.315|0.32] "rad"  GW
 SG_ ARS_RDI_SNR_Clu_124 : 294|7@0+ (0.5,0) [0|63.5] "dB"  GW
 SG_ ARS_RDI_DynProp_Clu_124 : 303|2@0+ (1,0) [0|3] ""  GW
 SG_ ARS_RDI_Quality_Clu_124 : 301|2@0+ (1,0) [0|3] ""  GW
 SG_ ARS_RDI_DynProp_Clu_125 : 299|2@0+ (1,0) [0|3] ""  GW
 SG_ ARS_RDI_Quality_Clu_125 : 297|2@0+ (1,0) [0|3] ""  GW
 SG_ ARS_RDI_Range_Clu_125 : 311|12@0+ (0.0625,0) [0|255.9375] "m"  GW
 SG_ ARS_RDI_VradRel_Clu_125 : 315|11@0+ (0.1,-120) [-120|84.7] "m/s"  GW
 SG_ ARS_RDI_RCS_Clu_125 : 320|9@0+ (0.2,-51.2) [-51.2|51] "dBsm"  GW
 SG_ ARS_RDI_AzimuthAng_Clu_120 : 39|10@0+ (0.002,-1.022) [-1.022|1.024] "rad"  GW
 SG_ ARS_RDI_AzimuthAng_Clu_125 : 343|10@0+ (0.002,-1.022) [-1.022|1.024] "rad"  GW
 SG_ ARS_RDI_ElevationAng_Clu_125 : 349|7@0+ (0.005,-0.315) [-0.315|0.32] "rad"  GW
 SG_ ARS_RDI_SNR_Clu_125 : 358|7@0+ (0.5,0) [0|63.5] "dB"  GW
 SG_ ARS_RDI_Range_Clu_126 : 367|12@0+ (0.0625,0) [0|255.9375] "m"  GW
 SG_ ARS_RDI_VradRel_Clu_126 : 371|11@0+ (0.1,-120) [-120|84.7] "m/s"  GW
 SG_ ARS_RDI_RCS_Clu_126 : 376|9@0+ (0.2,-51.2) [-51.2|51] "dBsm"  GW
 SG_ ARS_RDI_AzimuthAng_Clu_126 : 399|10@0+ (0.002,-1.022) [-1.022|1.024] "rad"  GW
 SG_ ARS_RDI_ElevationAng_Clu_126 : 405|7@0+ (0.005,-0.315) [-0.315|0.32] "rad"  GW
 SG_ ARS_RDI_SNR_Clu_126 : 414|7@0+ (0.5,0) [0|63.5] "dB"  GW
 SG_ ARS_RDI_DynProp_Clu_126 : 423|2@0+ (1,0) [0|3] ""  GW
 SG_ ARS_RDI_Quality_Clu_126 : 421|2@0+ (1,0) [0|3] ""  GW
 SG_ ARS_RDI_DynProp_Clu_127 : 419|2@0+ (1,0) [0|3] ""  GW
 SG_ ARS_RDI_Quality_Clu_127 : 417|2@0+ (1,0) [0|3] ""  GW
 SG_ ARS_RDI_Range_Clu_127 : 431|12@0+ (0.0625,0) [0|255.9375] "m"  GW
 SG_ ARS_RDI_ElevationAng_Clu_120 : 45|7@0+ (0.005,-0.315) [-0.315|0.32] "rad"  GW
 SG_ ARS_RDI_VradRel_Clu_127 : 435|11@0+ (0.1,-120) [-120|84.7] "m/s"  GW
 SG_ ARS_RDI_RCS_Clu_127 : 440|9@0+ (0.2,-51.2) [-51.2|51] "dBsm"  GW
 SG_ ARS_RDI_AzimuthAng_Clu_127 : 463|10@0+ (0.002,-1.022) [-1.022|1.024] "rad"  GW
 SG_ ARS_RDI_ElevationAng_Clu_127 : 469|7@0+ (0.005,-0.315) [-0.315|0.32] "rad"  GW
 SG_ ARS_RDI_SNR_Clu_127 : 478|7@0+ (0.5,0) [0|63.5] "dB"  GW
 SG_ ARS_RDI_MsgCounter_Clu_120_127 : 495|8@0+ (1,0) [0|255] ""  GW
 SG_ ARS_RDI_CRC16_Checksum_Clu_120_1 : 503|16@0+ (1,0) [0|65535] ""  GW
 SG_ ARS_RDI_SNR_Clu_120 : 54|7@0+ (0.5,0) [0|63.5] "dB"  GW
 SG_ ARS_RDI_DynProp_Clu_120 : 63|2@0+ (1,0) [0|3] ""  GW
 SG_ ARS_RDI_Quality_Clu_120 : 61|2@0+ (1,0) [0|3] ""  GW
 SG_ ARS_RDI_DynProp_Clu_121 : 59|2@0+ (1,0) [0|3] ""  GW
 SG_ ARS_RDI_Quality_Clu_121 : 57|2@0+ (1,0) [0|3] ""  GW
 SG_ ARS_RDI_Range_Clu_121 : 71|12@0+ (0.0625,0) [0|255.9375] "m"  GW
 SG_ ARS_RDI_VradRel_Clu_121 : 75|11@0+ (0.1,-120) [-120|84.7] "m/s"  GW
 SG_ ARS_RDI_RCS_Clu_121 : 80|9@0+ (0.2,-51.2) [-51.2|51] "dBsm"  GW
 SG_ ARS_RDI_AzimuthAng_Clu_121 : 103|10@0+ (0.002,-1.022) [-1.022|1.024] "rad"  GW

CM_ SG_ 33 ADCU_TSYNC_Type "  Multiplexor signal for frame indication of SYNC and FUP";
CM_ SG_ 48 ARS_TSYNC_TimeStampGlobSec "Synchronized global timestamp when the cyclic event is triggered (second part)
?????,???????????(???)";
CM_ SG_ 48 ARS_TSYNC_TimeStampGlobNSec "Synchronized global timestamp when the cyclic event is triggered (nannosecond part)
?????,???????????(????)";
CM_ SG_ 48 ARS_TSYNC_MaxTimeLeap "Maximal time leap in current Ignition-On cycle";
CM_ SG_ 48 ARS_TSYNC_LastTimeLeap "Last time leap in current Ignition-On cycle";
CM_ SG_ 80 ARS_CFG_Mode "Radar sensor working mode, MODE A by default
?????????,???? MODE A";
CM_ SG_ 80 ARS_CFG_VParAxisLdDistr_CFGflag "Configuration flag of AxisLoadDistr
??????????";
CM_ SG_ 80 ARS_CFG_VParCntrOGrvHght_CFGflag "Configuration flag of CntrOfGravHeight
?????????";
CM_ SG_ 80 ARS_CFG_VParCntrOGrvHght "Height of center of gravity
????";
CM_ SG_ 80 ARS_CFG_VParVehWeight_CFGflag "Configuration flag of VehWeight
???????????";
CM_ SG_ 80 ARS_CFG_VParTrkWdthRear_CFGflag "Configuration flag of TrackWidthRear
????????";
CM_ SG_ 80 ARS_CFG_VParAxisLdDistr "Ratio between rear axle load and total load
?????";
CM_ SG_ 80 ARS_CFG_VParTrkWdthFrnt_CFGflag "Configuration flag of TrackWidthFront
????????";
CM_ SG_ 80 ARS_CFG_VParLatPos "Lateral displacment related to vehicle reference point
????????";
CM_ SG_ 80 ARS_CFG_VParWheelBase_CFGflag "Configuration flag of WheelBase
???????";
CM_ SG_ 80 ARS_CFG_VParStrRatio_CFGflag "Configuration flag of SteeringRatio
????????";
CM_ SG_ 80 ARS_CFG_VParLongPos "Longitudinal displacment related to vehicle reference point
????????";
CM_ SG_ 80 ARS_CFG_TimeSyncEnableFlag "Time synchronization enabling flag, DISABLED by default
?????????,????";
CM_ SG_ 80 ARS_CFG_VParVertPos "Vertical displacemnt (height) over ground
????????";
CM_ SG_ 80 ARS_CFG_VParStrRatio "Overall steering ratio
???";
CM_ SG_ 80 ARS_CFG_VParLatPos_CFGflag "Configuration flag of LatPos
?????????????";
CM_ SG_ 80 ARS_CFG_SensorID_CFGflag "Configuration flag of YawAngle
????????????";
CM_ SG_ 80 ARS_CFG_VParLngPos2CoG "Longitudinal displacment related to vehicle center of gravity
??????????";
CM_ SG_ 80 ARS_CFG_VParYawAngle "Angular displacemnt about vehicle vertical axis
???????";
CM_ SG_ 80 ARS_CFG_VParLongPos_CFGflag "Configuration flag of LongPos
?????????????";
CM_ SG_ 80 ARS_CFG_VParVertPos_CFGflag "Configuration flag of VertPos
?????????????";
CM_ SG_ 80 ARS_CFG_VParLngPos2CoG_CFGflag "Configuration flag of LongPosToCoG
???????????????";
CM_ SG_ 80 ARS_CFG_VParSnsrOrnt "Sensor connector pointing direction
???????";
CM_ SG_ 80 ARS_CFG_VParSnsrOrnt_CFGflag "Configuration flag of SensorOrientation
????????????";
CM_ SG_ 80 ARS_CFG_VParYawAngle_CFGflag "Configuration flag of YawAngle
????????????";
CM_ SG_ 80 ARS_CFG_VParCoverDamping_CFGflag "Configuration flag of CoverDamping
????????????";
CM_ SG_ 80 ARS_CFG_VParCoverDamping "Attenuation of secondary surface (two-way) in dB
???????";
CM_ SG_ 80 ARS_CFG_VParWheelBase "Distance between front and rear axle
??";
CM_ SG_ 80 ARS_CFG_VParTrkWdthFrnt "wheel distance for front axle
???";
CM_ SG_ 80 ARS_CFG_VParTrkWdthRear "wheel distance for rear axle
???";
CM_ SG_ 80 ARS_CFG_VParVehWeight "curb weight of vehicle
??????";
CM_ SG_ 82 ARS_SP_OperationMode "Operation mode of current SW cycle";
CM_ SG_ 82 ARS_SP_CalibrationState "Calibration state of current SW cycle
?????????????";
CM_ SG_ 82 ARS_SP_TunnelFlag "Indicator whether tunnel has been detected";
CM_ SG_ 82 ARS_SP_AzimuthCorrection "Azimuth correction value applied in current SW cycle
?????????????";
CM_ SG_ 82 ARS_SP_ElevationCorrection "Elevation correction value applied in current SW cycle
?????????????";
CM_ SG_ 82 ARS_SP_ErrStateGroup_1 "Sensor error state signal group 1";
CM_ SG_ 82 ARS_SP_ErrStateGroup_2 "Sensor error state signal group 2";
CM_ SG_ 82 ARS_SP_ErrStateGroup_3 "Sensor error state signal group 3";
CM_ SG_ 82 ARS_SP_ErrStateGroup_4 "Sensor error state signal group 4";
CM_ SG_ 82 ARS_SP_VisibilityRange "Estimated visualibity range of current SW cycle";
CM_ SG_ 82 ARS_SP_VisibilityState "Detection visibility state of current Ignition-On cycle";
CM_ SG_ 256 ARS_RDI_TimeStampGlobSec "Synchronized global timestamp when RDI-task corresponding RF task is done (second part)
?????,RDI?????RF????????(???)";
CM_ SG_ 256 ARS_RDI_CycleCounter "Internal coutner that increments if RDI task executes once
??RDI?????";
CM_ SG_ 256 ARS_RDI_NumOfClusters "Number of clusters
????";
CM_ SG_ 256 ARS_RDI_RangeResolution "Range resolution
?????";
CM_ SG_ 256 ARS_RDI_MaxDetectionRange "Maximal detection range
??????";
CM_ SG_ 256 ARS_RDI_EgoVelocity "Ego velocity filtered by Radar Algorithm
????????????";
CM_ SG_ 256 ARS_RDI_EgoYawRate "Ego yaw rate filtered by Radar Algorithm
???????????????";
CM_ SG_ 256 ARS_RDI_Latency "Time difference between RF task and RDI task (signal processing time)
RF???RDI??????(??????)";
CM_ SG_ 256 ARS_RDI_EgoVelocityStd "Ego velocity standard deviation filtered by Radar Algorithm
???????????????";
CM_ SG_ 256 ARS_RDI_EgoAcceleration "Ego acceleration filtered by Radar Algorithm
?????????????";
CM_ SG_ 256 ARS_RDI_EgoCurvature "Ego curvature filtered by Radar Algorithm
??????????????";
CM_ SG_ 256 ARS_RDI_AmbigFreeDopplerRange "Maximal unambiguous doppler range
??????????";
CM_ SG_ 256 ARS_RDI_TaskValidFlag "Flag indicates RDI task is valid
RDI????????";
CM_ SG_ 256 ARS_RDI_ExtendedCycleFlag "Flag indicates RDI task takes two cycles time to execute
???????(?RDI????????????)";
CM_ SG_ 256 ARS_RDI_TimeStampGlobNSec "Synchronized global timestamp when RDI-task corresponding RF task is done (nannosecond part)
?????,RDI?????RF????????(????)";
CM_ SG_ 256 ARS_RDI_TimeStampLocal "Unsynchronized local timestamp when RDI-task corresponding RF task is done
??????,RDI?????RF??????????";
CM_ SG_ 256 ARS_RDI_MeasCounter "Internal counter that increments if RF task executes once
??RF?????";
CM_ SG_ 257 ARS_RDI_Range_Clu_000 "Range of cluster_000
000??????";
CM_ SG_ 257 ARS_RDI_VradRel_Clu_000 "Relative radial velocity of cluster_000
000??????????";
CM_ SG_ 257 ARS_RDI_RCS_Clu_000 "RCS of cluster_000
000?????????";
CM_ SG_ 257 ARS_RDI_AzimuthAng_Clu_000 "Azimuth angle of cluster_000
000???????";
CM_ SG_ 257 ARS_RDI_ElevationAng_Clu_000 "Elevation angle of cluster_000
000???????";
CM_ SG_ 257 ARS_RDI_SNR_Clu_000 "SNR of cluster_000
000???????";
CM_ SG_ 257 ARS_RDI_DynProp_Clu_000 "Dynamic property of cluster_000
000????????";
CM_ SG_ 257 ARS_RDI_Quality_Clu_000 "Quality of cluster_000
000??????";
BA_DEF_ BO_  "DiagRequest" ENUM  "no","yes";
BA_DEF_ BO_  "DiagResponse" ENUM  "no","yes";
BA_DEF_ BO_  "GenMsgCycleTime" INT 0 0;
BA_DEF_ BO_  "GenMsgSendType" ENUM  "Cyclic","NotUsed","Event","NotUsed","NotUsed","NotUsed","NotUsed","IfActive","NoMsgSendType","NotUsed";
BA_DEF_ BO_  "VFrameFormat" ENUM  "StandardCAN","ExtendedCAN","RESERVED","RESERVED","RESERVED","RESERVED","RESERVED","RESERVED","RESERVED","RESERVED","RESERVED","RESERVED","RESERVED","RESERVED","StandardCAN_FD","ExtendedCAN_FD";
BA_DEF_ SG_  "GenSigSendType" ENUM  "Cyclic","OnWrite","OnWriteWithRepetition","OnChange","OnChangeWithRepetition","IfActive","IfActiveWithRepetition","NoSigSendType","NotUsed","NotUsed","NotUsed","NotUsed","NotUsed";
BA_DEF_ SG_  "GenSigStartValue" INT 0 0;
BA_DEF_ BU_  "NmAsrCanMsgReducedTime" INT 1 65535;
BA_DEF_ BU_  "NmAsrNodeIdentifier" HEX 0 255;
BA_DEF_ BU_  "NodeLayerModules" STRING ;
BA_DEF_  "Baudrate" INT 0 1000000;
BA_DEF_  "BusType" STRING ;
BA_DEF_  "DBName" STRING ;
BA_DEF_  "Manufacturer" STRING ;
BA_DEF_  "NmAsrBaseAddress" HEX 0 2047;
BA_DEF_  "NmAsrCanMsgCycleTime" INT 1 65535;
BA_DEF_  "NmAsrMessageCount" INT 1 256;
BA_DEF_  "NmAsrRepeatMessageTime" INT 0 65535;
BA_DEF_  "NmAsrTimeoutTime" INT 1 65535;
BA_DEF_  "NmAsrWaitBusSleepTime" INT 0 65535;
BA_DEF_  "NmType" STRING ;
BA_DEF_ SG_  "SystemSignalLongSymbol" STRING ;
BA_DEF_DEF_  "DiagRequest" "no";
BA_DEF_DEF_  "DiagResponse" "no";
BA_DEF_DEF_  "GenMsgCycleTime" 0;
BA_DEF_DEF_  "GenMsgSendType" "Cyclic";
BA_DEF_DEF_  "VFrameFormat" "ExtendedCAN_FD";
BA_DEF_DEF_  "GenSigSendType" "Cyclic";
BA_DEF_DEF_  "GenSigStartValue" 0;
BA_DEF_DEF_  "NmAsrCanMsgReducedTime" 320;
BA_DEF_DEF_  "NmAsrNodeIdentifier" 50;
BA_DEF_DEF_  "NodeLayerModules" " ";
BA_DEF_DEF_  "Baudrate" 500000;
BA_DEF_DEF_  "BusType" "";
BA_DEF_DEF_  "DBName" "";
BA_DEF_DEF_  "Manufacturer" "Vector";
BA_DEF_DEF_  "NmAsrBaseAddress" 1280;
BA_DEF_DEF_  "NmAsrCanMsgCycleTime" 640;
BA_DEF_DEF_  "NmAsrMessageCount" 128;
BA_DEF_DEF_  "NmAsrRepeatMessageTime" 3200;
BA_DEF_DEF_  "NmAsrTimeoutTime" 2000;
BA_DEF_DEF_  "NmAsrWaitBusSleepTime" 1500;
BA_DEF_DEF_  "NmType" "";
BA_DEF_DEF_  "SystemSignalLongSymbol" "";
BA_ "NmType" "NmAsr";
BA_ "NmAsrWaitBusSleepTime" 2000;
BA_ "BusType" "CAN FD";
BA_ "GenMsgCycleTime" BO_ 33 500;
BA_ "VFrameFormat" BO_ 33 14;
BA_ "GenMsgCycleTime" BO_ 48 50;
BA_ "VFrameFormat" BO_ 48 14;
BA_ "GenMsgCycleTime" BO_ 64 10;
BA_ "VFrameFormat" BO_ 64 14;
BA_ "GenMsgCycleTime" BO_ 65 10;
BA_ "VFrameFormat" BO_ 65 14;
BA_ "GenMsgCycleTime" BO_ 66 10;
BA_ "VFrameFormat" BO_ 66 14;
BA_ "GenMsgCycleTime" BO_ 67 10;
BA_ "VFrameFormat" BO_ 67 14;
BA_ "GenMsgCycleTime" BO_ 68 500;
BA_ "VFrameFormat" BO_ 68 14;
BA_ "GenMsgCycleTime" BO_ 69 500;
BA_ "VFrameFormat" BO_ 69 14;
BA_ "GenMsgCycleTime" BO_ 70 500;
BA_ "VFrameFormat" BO_ 70 14;
BA_ "GenMsgCycleTime" BO_ 80 500;
BA_ "VFrameFormat" BO_ 80 14;
BA_ "GenMsgCycleTime" BO_ 82 50;
BA_ "VFrameFormat" BO_ 82 14;
BA_ "GenMsgSendType" BO_ 256 2;
BA_ "VFrameFormat" BO_ 256 14;
BA_ "GenMsgSendType" BO_ 257 2;
BA_ "VFrameFormat" BO_ 257 14;
BA_ "GenMsgSendType" BO_ 258 2;
BA_ "VFrameFormat" BO_ 258 14;
BA_ "GenMsgSendType" BO_ 259 2;
BA_ "VFrameFormat" BO_ 259 14;
BA_ "GenMsgSendType" BO_ 260 2;
BA_ "VFrameFormat" BO_ 260 14;
BA_ "GenMsgSendType" BO_ 261 2;
BA_ "VFrameFormat" BO_ 261 14;
BA_ "GenMsgSendType" BO_ 262 2;
BA_ "VFrameFormat" BO_ 262 14;
BA_ "GenMsgSendType" BO_ 263 2;
BA_ "VFrameFormat" BO_ 263 14;
BA_ "GenMsgSendType" BO_ 264 2;
BA_ "VFrameFormat" BO_ 264 14;
BA_ "GenMsgSendType" BO_ 265 2;
BA_ "VFrameFormat" BO_ 265 14;
BA_ "GenMsgSendType" BO_ 266 2;
BA_ "VFrameFormat" BO_ 266 14;
BA_ "GenMsgSendType" BO_ 267 2;
BA_ "VFrameFormat" BO_ 267 14;
BA_ "GenMsgSendType" BO_ 268 2;
BA_ "VFrameFormat" BO_ 268 14;
BA_ "GenMsgSendType" BO_ 269 2;
BA_ "VFrameFormat" BO_ 269 14;
BA_ "GenMsgSendType" BO_ 270 2;
BA_ "VFrameFormat" BO_ 270 14;
BA_ "GenMsgSendType" BO_ 271 2;
BA_ "VFrameFormat" BO_ 271 14;
BA_ "GenMsgSendType" BO_ 272 2;
BA_ "VFrameFormat" BO_ 272 14;
BA_ "GenSigStartValue" SG_ 68 GW_TBOX_AbsoluteTime_Year 255;
BA_ "GenSigStartValue" SG_ 68 GW_TBOX_AbsoluteTime_Month 15;
BA_ "GenSigStartValue" SG_ 68 GW_TBOX_AbsoluteTime_Day 63;
BA_ "GenSigStartValue" SG_ 68 GW_TBOX_AbsoluteTime_Hour 31;
BA_ "GenSigStartValue" SG_ 68 GW_TBOX_AbsoluteTime_Minute 63;
BA_ "GenSigStartValue" SG_ 68 GW_TBOX_AbsoluteTime_Second 63;
BA_ "GenSigStartValue" SG_ 69 GW_IDCM_VehicleTotalMileage 16777215;
BA_ "GenSigStartValue" SG_ 80 ARS_CFG_VParLatPos 1023;
BA_ "GenSigStartValue" SG_ 80 ARS_CFG_VParLongPos 4095;
BA_ "GenSigStartValue" SG_ 80 ARS_CFG_VParLngPos2CoG 4095;
BA_ "GenSigStartValue" SG_ 80 ARS_CFG_VParYawAngle 4095;
BA_ "GenSigStartValue" SG_ 82 ARS_SP_AzimuthCorrection 127;
BA_ "GenSigStartValue" SG_ 82 ARS_SP_ElevationCorrection 127;
BA_ "GenSigStartValue" SG_ 256 ARS_RDI_EgoVelocity 340;
BA_ "GenSigStartValue" SG_ 256 ARS_RDI_EgoYawRate 511;
BA_ "GenSigStartValue" SG_ 256 ARS_RDI_EgoAcceleration 160;
BA_ "GenSigStartValue" SG_ 256 ARS_RDI_EgoCurvature 511;
BA_ "GenSigStartValue" SG_ 257 ARS_RDI_ElevationAng_Clu_001 63;
BA_ "GenSigStartValue" SG_ 257 ARS_RDI_VradRel_Clu_000 1200;
BA_ "GenSigStartValue" SG_ 257 ARS_RDI_VradRel_Clu_002 1200;
BA_ "GenSigStartValue" SG_ 257 ARS_RDI_RCS_Clu_002 256;
BA_ "GenSigStartValue" SG_ 257 ARS_RDI_AzimuthAng_Clu_002 511;
BA_ "GenSigStartValue" SG_ 257 ARS_RDI_ElevationAng_Clu_002 63;
BA_ "GenSigStartValue" SG_ 257 ARS_RDI_VradRel_Clu_003 1200;
BA_ "GenSigStartValue" SG_ 257 ARS_RDI_RCS_Clu_003 256;
BA_ "GenSigStartValue" SG_ 257 ARS_RDI_AzimuthAng_Clu_003 511;
BA_ "GenSigStartValue" SG_ 257 ARS_RDI_ElevationAng_Clu_003 63;
BA_ "GenSigStartValue" SG_ 257 ARS_RDI_RCS_Clu_000 256;
BA_ "GenSigStartValue" SG_ 257 ARS_RDI_VradRel_Clu_004 1200;
BA_ "GenSigStartValue" SG_ 257 ARS_RDI_RCS_Clu_004 256;
BA_ "GenSigStartValue" SG_ 257 ARS_RDI_AzimuthAng_Clu_004 511;
BA_ "GenSigStartValue" SG_ 257 ARS_RDI_ElevationAng_Clu_004 63;
BA_ "GenSigStartValue" SG_ 257 ARS_RDI_VradRel_Clu_005 1200;
BA_ "GenSigStartValue" SG_ 257 ARS_RDI_RCS_Clu_005 256;
BA_ "GenSigStartValue" SG_ 257 ARS_RDI_AzimuthAng_Clu_000 511;
BA_ "GenSigStartValue" SG_ 257 ARS_RDI_AzimuthAng_Clu_005 511;
BA_ "GenSigStartValue" SG_ 257 ARS_RDI_ElevationAng_Clu_005 63;
BA_ "GenSigStartValue" SG_ 257 ARS_RDI_VradRel_Clu_006 1200;
BA_ "GenSigStartValue" SG_ 257 ARS_RDI_RCS_Clu_006 256;
BA_ "GenSigStartValue" SG_ 257 ARS_RDI_AzimuthAng_Clu_006 511;
BA_ "GenSigStartValue" SG_ 257 ARS_RDI_ElevationAng_Clu_006 63;
BA_ "GenSigStartValue" SG_ 257 ARS_RDI_ElevationAng_Clu_000 63;
BA_ "GenSigStartValue" SG_ 257 ARS_RDI_VradRel_Clu_007 1200;
BA_ "GenSigStartValue" SG_ 257 ARS_RDI_RCS_Clu_007 256;
BA_ "GenSigStartValue" SG_ 257 ARS_RDI_AzimuthAng_Clu_007 511;
BA_ "GenSigStartValue" SG_ 257 ARS_RDI_ElevationAng_Clu_007 63;
BA_ "SystemSignalLongSymbol" SG_ 257 ARS_RDI_CRC16_Checksum_Clu_000_0 "ARS_RDI_CRC16_Checksum_Clu_000_007";
BA_ "GenSigStartValue" SG_ 257 ARS_RDI_VradRel_Clu_001 1200;
BA_ "GenSigStartValue" SG_ 257 ARS_RDI_RCS_Clu_001 256;
BA_ "GenSigStartValue" SG_ 257 ARS_RDI_AzimuthAng_Clu_001 511;
BA_ "GenSigStartValue" SG_ 258 ARS_RDI_ElevationAng_Clu_009 63;
BA_ "GenSigStartValue" SG_ 258 ARS_RDI_VradRel_Clu_008 1200;
BA_ "GenSigStartValue" SG_ 258 ARS_RDI_VradRel_Clu_010 1200;
BA_ "GenSigStartValue" SG_ 258 ARS_RDI_RCS_Clu_010 256;
BA_ "GenSigStartValue" SG_ 258 ARS_RDI_AzimuthAng_Clu_010 511;
BA_ "GenSigStartValue" SG_ 258 ARS_RDI_ElevationAng_Clu_010 63;
BA_ "GenSigStartValue" SG_ 258 ARS_RDI_VradRel_Clu_011 1200;
BA_ "GenSigStartValue" SG_ 258 ARS_RDI_RCS_Clu_011 256;
BA_ "GenSigStartValue" SG_ 258 ARS_RDI_AzimuthAng_Clu_011 511;
BA_ "GenSigStartValue" SG_ 258 ARS_RDI_ElevationAng_Clu_011 63;
BA_ "GenSigStartValue" SG_ 258 ARS_RDI_RCS_Clu_008 256;
BA_ "GenSigStartValue" SG_ 258 ARS_RDI_VradRel_Clu_012 1200;
BA_ "GenSigStartValue" SG_ 258 ARS_RDI_RCS_Clu_012 256;
BA_ "GenSigStartValue" SG_ 258 ARS_RDI_AzimuthAng_Clu_012 511;
BA_ "GenSigStartValue" SG_ 258 ARS_RDI_ElevationAng_Clu_012 63;
BA_ "GenSigStartValue" SG_ 258 ARS_RDI_VradRel_Clu_013 1200;
BA_ "GenSigStartValue" SG_ 258 ARS_RDI_RCS_Clu_013 256;
BA_ "GenSigStartValue" SG_ 258 ARS_RDI_AzimuthAng_Clu_008 511;
BA_ "GenSigStartValue" SG_ 258 ARS_RDI_AzimuthAng_Clu_013 511;
BA_ "GenSigStartValue" SG_ 258 ARS_RDI_ElevationAng_Clu_013 63;
BA_ "GenSigStartValue" SG_ 258 ARS_RDI_VradRel_Clu_014 1200;
BA_ "GenSigStartValue" SG_ 258 ARS_RDI_RCS_Clu_014 256;
BA_ "GenSigStartValue" SG_ 258 ARS_RDI_AzimuthAng_Clu_014 511;
BA_ "GenSigStartValue" SG_ 258 ARS_RDI_ElevationAng_Clu_014 63;
BA_ "GenSigStartValue" SG_ 258 ARS_RDI_ElevationAng_Clu_008 63;
BA_ "GenSigStartValue" SG_ 258 ARS_RDI_VradRel_Clu_015 1200;
BA_ "GenSigStartValue" SG_ 258 ARS_RDI_RCS_Clu_015 256;
BA_ "GenSigStartValue" SG_ 258 ARS_RDI_AzimuthAng_Clu_015 511;
BA_ "GenSigStartValue" SG_ 258 ARS_RDI_ElevationAng_Clu_015 63;
BA_ "SystemSignalLongSymbol" SG_ 258 ARS_RDI_CRC16_Checksum_Clu_008_0 "ARS_RDI_CRC16_Checksum_Clu_008_015";
BA_ "GenSigStartValue" SG_ 258 ARS_RDI_VradRel_Clu_009 1200;
BA_ "GenSigStartValue" SG_ 258 ARS_RDI_RCS_Clu_009 256;
BA_ "GenSigStartValue" SG_ 258 ARS_RDI_AzimuthAng_Clu_009 511;
BA_ "GenSigStartValue" SG_ 259 ARS_RDI_ElevationAng_Clu_017 63;
BA_ "GenSigStartValue" SG_ 259 ARS_RDI_VradRel_Clu_016 1200;
BA_ "GenSigStartValue" SG_ 259 ARS_RDI_VradRel_Clu_018 1200;
BA_ "GenSigStartValue" SG_ 259 ARS_RDI_RCS_Clu_018 256;
BA_ "GenSigStartValue" SG_ 259 ARS_RDI_AzimuthAng_Clu_018 511;
BA_ "GenSigStartValue" SG_ 259 ARS_RDI_ElevationAng_Clu_018 63;
BA_ "GenSigStartValue" SG_ 259 ARS_RDI_VradRel_Clu_019 1200;
BA_ "GenSigStartValue" SG_ 259 ARS_RDI_RCS_Clu_019 256;
BA_ "GenSigStartValue" SG_ 259 ARS_RDI_AzimuthAng_Clu_019 511;
BA_ "GenSigStartValue" SG_ 259 ARS_RDI_ElevationAng_Clu_019 63;
BA_ "GenSigStartValue" SG_ 259 ARS_RDI_RCS_Clu_016 256;
BA_ "GenSigStartValue" SG_ 259 ARS_RDI_VradRel_Clu_020 1200;
BA_ "GenSigStartValue" SG_ 259 ARS_RDI_RCS_Clu_020 256;
BA_ "GenSigStartValue" SG_ 259 ARS_RDI_AzimuthAng_Clu_020 511;
BA_ "GenSigStartValue" SG_ 259 ARS_RDI_ElevationAng_Clu_020 63;
BA_ "GenSigStartValue" SG_ 259 ARS_RDI_VradRel_Clu_021 1200;
BA_ "GenSigStartValue" SG_ 259 ARS_RDI_RCS_Clu_021 256;
BA_ "GenSigStartValue" SG_ 259 ARS_RDI_AzimuthAng_Clu_016 511;
BA_ "GenSigStartValue" SG_ 259 ARS_RDI_AzimuthAng_Clu_021 511;
BA_ "GenSigStartValue" SG_ 259 ARS_RDI_ElevationAng_Clu_021 63;
BA_ "GenSigStartValue" SG_ 259 ARS_RDI_VradRel_Clu_022 1200;
BA_ "GenSigStartValue" SG_ 259 ARS_RDI_RCS_Clu_022 256;
BA_ "GenSigStartValue" SG_ 259 ARS_RDI_AzimuthAng_Clu_022 511;
BA_ "GenSigStartValue" SG_ 259 ARS_RDI_ElevationAng_Clu_022 63;
BA_ "GenSigStartValue" SG_ 259 ARS_RDI_ElevationAng_Clu_016 63;
BA_ "GenSigStartValue" SG_ 259 ARS_RDI_VradRel_Clu_023 1200;
BA_ "GenSigStartValue" SG_ 259 ARS_RDI_RCS_Clu_023 256;
BA_ "GenSigStartValue" SG_ 259 ARS_RDI_AzimuthAng_Clu_023 511;
BA_ "GenSigStartValue" SG_ 259 ARS_RDI_ElevationAng_Clu_023 63;
BA_ "SystemSignalLongSymbol" SG_ 259 ARS_RDI_CRC16_Checksum_Clu_016_0 "ARS_RDI_CRC16_Checksum_Clu_016_023";
BA_ "GenSigStartValue" SG_ 259 ARS_RDI_VradRel_Clu_017 1200;
BA_ "GenSigStartValue" SG_ 259 ARS_RDI_RCS_Clu_017 256;
BA_ "GenSigStartValue" SG_ 259 ARS_RDI_AzimuthAng_Clu_017 511;
BA_ "GenSigStartValue" SG_ 260 ARS_RDI_ElevationAng_Clu_025 63;
BA_ "GenSigStartValue" SG_ 260 ARS_RDI_VradRel_Clu_024 1200;
BA_ "GenSigStartValue" SG_ 260 ARS_RDI_VradRel_Clu_026 1200;
BA_ "GenSigStartValue" SG_ 260 ARS_RDI_RCS_Clu_026 256;
BA_ "GenSigStartValue" SG_ 260 ARS_RDI_AzimuthAng_Clu_026 511;
BA_ "GenSigStartValue" SG_ 260 ARS_RDI_ElevationAng_Clu_026 63;
BA_ "GenSigStartValue" SG_ 260 ARS_RDI_VradRel_Clu_027 1200;
BA_ "GenSigStartValue" SG_ 260 ARS_RDI_RCS_Clu_027 256;
BA_ "GenSigStartValue" SG_ 260 ARS_RDI_AzimuthAng_Clu_027 511;
BA_ "GenSigStartValue" SG_ 260 ARS_RDI_ElevationAng_Clu_027 63;
BA_ "GenSigStartValue" SG_ 260 ARS_RDI_RCS_Clu_024 256;
BA_ "GenSigStartValue" SG_ 260 ARS_RDI_VradRel_Clu_028 1200;
BA_ "GenSigStartValue" SG_ 260 ARS_RDI_RCS_Clu_028 256;
BA_ "GenSigStartValue" SG_ 260 ARS_RDI_AzimuthAng_Clu_028 511;
BA_ "GenSigStartValue" SG_ 260 ARS_RDI_ElevationAng_Clu_028 63;
BA_ "GenSigStartValue" SG_ 260 ARS_RDI_VradRel_Clu_029 1200;
BA_ "GenSigStartValue" SG_ 260 ARS_RDI_RCS_Clu_029 256;
BA_ "GenSigStartValue" SG_ 260 ARS_RDI_AzimuthAng_Clu_024 511;
BA_ "GenSigStartValue" SG_ 260 ARS_RDI_AzimuthAng_Clu_029 511;
BA_ "GenSigStartValue" SG_ 260 ARS_RDI_ElevationAng_Clu_029 63;
BA_ "GenSigStartValue" SG_ 260 ARS_RDI_VradRel_Clu_030 1200;
BA_ "GenSigStartValue" SG_ 260 ARS_RDI_RCS_Clu_030 256;
BA_ "GenSigStartValue" SG_ 260 ARS_RDI_AzimuthAng_Clu_030 511;
BA_ "GenSigStartValue" SG_ 260 ARS_RDI_ElevationAng_Clu_030 63;
BA_ "GenSigStartValue" SG_ 260 ARS_RDI_ElevationAng_Clu_024 63;
BA_ "GenSigStartValue" SG_ 260 ARS_RDI_VradRel_Clu_031 1200;
BA_ "GenSigStartValue" SG_ 260 ARS_RDI_RCS_Clu_031 256;
BA_ "GenSigStartValue" SG_ 260 ARS_RDI_AzimuthAng_Clu_031 511;
BA_ "GenSigStartValue" SG_ 260 ARS_RDI_ElevationAng_Clu_031 63;
BA_ "SystemSignalLongSymbol" SG_ 260 ARS_RDI_CRC16_Checksum_Clu_024_0 "ARS_RDI_CRC16_Checksum_Clu_024_031";
BA_ "GenSigStartValue" SG_ 260 ARS_RDI_VradRel_Clu_025 1200;
BA_ "GenSigStartValue" SG_ 260 ARS_RDI_RCS_Clu_025 256;
BA_ "GenSigStartValue" SG_ 260 ARS_RDI_AzimuthAng_Clu_025 511;
BA_ "GenSigStartValue" SG_ 261 ARS_RDI_ElevationAng_Clu_033 63;
BA_ "GenSigStartValue" SG_ 261 ARS_RDI_VradRel_Clu_032 1200;
BA_ "GenSigStartValue" SG_ 261 ARS_RDI_VradRel_Clu_034 1200;
BA_ "GenSigStartValue" SG_ 261 ARS_RDI_RCS_Clu_034 256;
BA_ "GenSigStartValue" SG_ 261 ARS_RDI_AzimuthAng_Clu_034 511;
BA_ "GenSigStartValue" SG_ 261 ARS_RDI_ElevationAng_Clu_034 63;
BA_ "GenSigStartValue" SG_ 261 ARS_RDI_VradRel_Clu_035 1200;
BA_ "GenSigStartValue" SG_ 261 ARS_RDI_RCS_Clu_035 256;
BA_ "GenSigStartValue" SG_ 261 ARS_RDI_AzimuthAng_Clu_035 511;
BA_ "GenSigStartValue" SG_ 261 ARS_RDI_ElevationAng_Clu_035 63;
BA_ "GenSigStartValue" SG_ 261 ARS_RDI_RCS_Clu_032 256;
BA_ "GenSigStartValue" SG_ 261 ARS_RDI_VradRel_Clu_036 1200;
BA_ "GenSigStartValue" SG_ 261 ARS_RDI_RCS_Clu_036 256;
BA_ "GenSigStartValue" SG_ 261 ARS_RDI_AzimuthAng_Clu_036 511;
BA_ "GenSigStartValue" SG_ 261 ARS_RDI_ElevationAng_Clu_036 63;
BA_ "GenSigStartValue" SG_ 261 ARS_RDI_VradRel_Clu_037 1200;
BA_ "GenSigStartValue" SG_ 261 ARS_RDI_RCS_Clu_037 256;
BA_ "GenSigStartValue" SG_ 261 ARS_RDI_AzimuthAng_Clu_032 511;
BA_ "GenSigStartValue" SG_ 261 ARS_RDI_AzimuthAng_Clu_037 511;
BA_ "GenSigStartValue" SG_ 261 ARS_RDI_ElevationAng_Clu_037 63;
BA_ "GenSigStartValue" SG_ 261 ARS_RDI_VradRel_Clu_038 1200;
BA_ "GenSigStartValue" SG_ 261 ARS_RDI_RCS_Clu_038 256;
BA_ "GenSigStartValue" SG_ 261 ARS_RDI_AzimuthAng_Clu_038 511;
BA_ "GenSigStartValue" SG_ 261 ARS_RDI_ElevationAng_Clu_038 63;
BA_ "GenSigStartValue" SG_ 261 ARS_RDI_ElevationAng_Clu_032 63;
BA_ "GenSigStartValue" SG_ 261 ARS_RDI_VradRel_Clu_039 1200;
BA_ "GenSigStartValue" SG_ 261 ARS_RDI_RCS_Clu_039 256;
BA_ "GenSigStartValue" SG_ 261 ARS_RDI_AzimuthAng_Clu_039 511;
BA_ "GenSigStartValue" SG_ 261 ARS_RDI_ElevationAng_Clu_039 63;
BA_ "SystemSignalLongSymbol" SG_ 261 ARS_RDI_CRC16_Checksum_Clu_032_0 "ARS_RDI_CRC16_Checksum_Clu_032_039";
BA_ "GenSigStartValue" SG_ 261 ARS_RDI_VradRel_Clu_033 1200;
BA_ "GenSigStartValue" SG_ 261 ARS_RDI_RCS_Clu_033 256;
BA_ "GenSigStartValue" SG_ 261 ARS_RDI_AzimuthAng_Clu_033 511;
BA_ "GenSigStartValue" SG_ 262 ARS_RDI_ElevationAng_Clu_041 63;
BA_ "GenSigStartValue" SG_ 262 ARS_RDI_VradRel_Clu_040 1200;
BA_ "GenSigStartValue" SG_ 262 ARS_RDI_VradRel_Clu_042 1200;
BA_ "GenSigStartValue" SG_ 262 ARS_RDI_RCS_Clu_042 256;
BA_ "GenSigStartValue" SG_ 262 ARS_RDI_AzimuthAng_Clu_042 511;
BA_ "GenSigStartValue" SG_ 262 ARS_RDI_ElevationAng_Clu_042 63;
BA_ "GenSigStartValue" SG_ 262 ARS_RDI_VradRel_Clu_043 1200;
BA_ "GenSigStartValue" SG_ 262 ARS_RDI_RCS_Clu_043 256;
BA_ "GenSigStartValue" SG_ 262 ARS_RDI_AzimuthAng_Clu_043 511;
BA_ "GenSigStartValue" SG_ 262 ARS_RDI_ElevationAng_Clu_043 63;
BA_ "GenSigStartValue" SG_ 262 ARS_RDI_RCS_Clu_040 256;
BA_ "GenSigStartValue" SG_ 262 ARS_RDI_VradRel_Clu_044 1200;
BA_ "GenSigStartValue" SG_ 262 ARS_RDI_RCS_Clu_044 256;
BA_ "GenSigStartValue" SG_ 262 ARS_RDI_AzimuthAng_Clu_044 511;
BA_ "GenSigStartValue" SG_ 262 ARS_RDI_ElevationAng_Clu_044 63;
BA_ "GenSigStartValue" SG_ 262 ARS_RDI_VradRel_Clu_045 1200;
BA_ "GenSigStartValue" SG_ 262 ARS_RDI_RCS_Clu_045 256;
BA_ "GenSigStartValue" SG_ 262 ARS_RDI_AzimuthAng_Clu_040 511;
BA_ "GenSigStartValue" SG_ 262 ARS_RDI_AzimuthAng_Clu_045 511;
BA_ "GenSigStartValue" SG_ 262 ARS_RDI_ElevationAng_Clu_045 63;
BA_ "GenSigStartValue" SG_ 262 ARS_RDI_VradRel_Clu_046 1200;
BA_ "GenSigStartValue" SG_ 262 ARS_RDI_RCS_Clu_046 256;
BA_ "GenSigStartValue" SG_ 262 ARS_RDI_AzimuthAng_Clu_046 511;
BA_ "GenSigStartValue" SG_ 262 ARS_RDI_ElevationAng_Clu_046 63;
BA_ "GenSigStartValue" SG_ 262 ARS_RDI_ElevationAng_Clu_040 63;
BA_ "GenSigStartValue" SG_ 262 ARS_RDI_VradRel_Clu_047 1200;
BA_ "GenSigStartValue" SG_ 262 ARS_RDI_RCS_Clu_047 256;
BA_ "GenSigStartValue" SG_ 262 ARS_RDI_AzimuthAng_Clu_047 511;
BA_ "GenSigStartValue" SG_ 262 ARS_RDI_ElevationAng_Clu_047 63;
BA_ "SystemSignalLongSymbol" SG_ 262 ARS_RDI_CRC16_Checksum_Clu_040_0 "ARS_RDI_CRC16_Checksum_Clu_040_047";
BA_ "GenSigStartValue" SG_ 262 ARS_RDI_VradRel_Clu_041 1200;
BA_ "GenSigStartValue" SG_ 262 ARS_RDI_RCS_Clu_041 256;
BA_ "GenSigStartValue" SG_ 262 ARS_RDI_AzimuthAng_Clu_041 511;
BA_ "GenSigStartValue" SG_ 263 ARS_RDI_ElevationAng_Clu_049 63;
BA_ "GenSigStartValue" SG_ 263 ARS_RDI_VradRel_Clu_048 1200;
BA_ "GenSigStartValue" SG_ 263 ARS_RDI_VradRel_Clu_050 1200;
BA_ "GenSigStartValue" SG_ 263 ARS_RDI_RCS_Clu_050 256;
BA_ "GenSigStartValue" SG_ 263 ARS_RDI_AzimuthAng_Clu_050 511;
BA_ "GenSigStartValue" SG_ 263 ARS_RDI_ElevationAng_Clu_050 63;
BA_ "GenSigStartValue" SG_ 263 ARS_RDI_VradRel_Clu_051 1200;
BA_ "GenSigStartValue" SG_ 263 ARS_RDI_RCS_Clu_051 256;
BA_ "GenSigStartValue" SG_ 263 ARS_RDI_AzimuthAng_Clu_051 511;
BA_ "GenSigStartValue" SG_ 263 ARS_RDI_ElevationAng_Clu_051 63;
BA_ "GenSigStartValue" SG_ 263 ARS_RDI_RCS_Clu_048 256;
BA_ "GenSigStartValue" SG_ 263 ARS_RDI_VradRel_Clu_052 1200;
BA_ "GenSigStartValue" SG_ 263 ARS_RDI_RCS_Clu_052 256;
BA_ "GenSigStartValue" SG_ 263 ARS_RDI_AzimuthAng_Clu_052 511;
BA_ "GenSigStartValue" SG_ 263 ARS_RDI_ElevationAng_Clu_052 63;
BA_ "GenSigStartValue" SG_ 263 ARS_RDI_VradRel_Clu_053 1200;
BA_ "GenSigStartValue" SG_ 263 ARS_RDI_RCS_Clu_053 256;
BA_ "GenSigStartValue" SG_ 263 ARS_RDI_AzimuthAng_Clu_048 511;
BA_ "GenSigStartValue" SG_ 263 ARS_RDI_AzimuthAng_Clu_053 511;
BA_ "GenSigStartValue" SG_ 263 ARS_RDI_ElevationAng_Clu_053 63;
BA_ "GenSigStartValue" SG_ 263 ARS_RDI_VradRel_Clu_054 1200;
BA_ "GenSigStartValue" SG_ 263 ARS_RDI_RCS_Clu_054 256;
BA_ "GenSigStartValue" SG_ 263 ARS_RDI_AzimuthAng_Clu_054 511;
BA_ "GenSigStartValue" SG_ 263 ARS_RDI_ElevationAng_Clu_054 63;
BA_ "GenSigStartValue" SG_ 263 ARS_RDI_ElevationAng_Clu_048 63;
BA_ "GenSigStartValue" SG_ 263 ARS_RDI_VradRel_Clu_055 1200;
BA_ "GenSigStartValue" SG_ 263 ARS_RDI_RCS_Clu_055 256;
BA_ "GenSigStartValue" SG_ 263 ARS_RDI_AzimuthAng_Clu_055 511;
BA_ "GenSigStartValue" SG_ 263 ARS_RDI_ElevationAng_Clu_055 63;
BA_ "SystemSignalLongSymbol" SG_ 263 ARS_RDI_CRC16_Checksum_Clu_048_0 "ARS_RDI_CRC16_Checksum_Clu_048_055";
BA_ "GenSigStartValue" SG_ 263 ARS_RDI_VradRel_Clu_049 1200;
BA_ "GenSigStartValue" SG_ 263 ARS_RDI_RCS_Clu_049 256;
BA_ "GenSigStartValue" SG_ 263 ARS_RDI_AzimuthAng_Clu_049 511;
BA_ "GenSigStartValue" SG_ 264 ARS_RDI_ElevationAng_Clu_057 63;
BA_ "GenSigStartValue" SG_ 264 ARS_RDI_VradRel_Clu_056 1200;
BA_ "GenSigStartValue" SG_ 264 ARS_RDI_VradRel_Clu_058 1200;
BA_ "GenSigStartValue" SG_ 264 ARS_RDI_RCS_Clu_058 256;
BA_ "GenSigStartValue" SG_ 264 ARS_RDI_AzimuthAng_Clu_058 511;
BA_ "GenSigStartValue" SG_ 264 ARS_RDI_ElevationAng_Clu_058 63;
BA_ "GenSigStartValue" SG_ 264 ARS_RDI_VradRel_Clu_059 1200;
BA_ "GenSigStartValue" SG_ 264 ARS_RDI_RCS_Clu_059 256;
BA_ "GenSigStartValue" SG_ 264 ARS_RDI_AzimuthAng_Clu_059 511;
BA_ "GenSigStartValue" SG_ 264 ARS_RDI_ElevationAng_Clu_059 63;
BA_ "GenSigStartValue" SG_ 264 ARS_RDI_RCS_Clu_056 256;
BA_ "GenSigStartValue" SG_ 264 ARS_RDI_VradRel_Clu_060 1200;
BA_ "GenSigStartValue" SG_ 264 ARS_RDI_RCS_Clu_060 256;
BA_ "GenSigStartValue" SG_ 264 ARS_RDI_AzimuthAng_Clu_060 511;
BA_ "GenSigStartValue" SG_ 264 ARS_RDI_ElevationAng_Clu_060 63;
BA_ "GenSigStartValue" SG_ 264 ARS_RDI_VradRel_Clu_061 1200;
BA_ "GenSigStartValue" SG_ 264 ARS_RDI_RCS_Clu_061 256;
BA_ "GenSigStartValue" SG_ 264 ARS_RDI_AzimuthAng_Clu_056 511;
BA_ "GenSigStartValue" SG_ 264 ARS_RDI_AzimuthAng_Clu_061 511;
BA_ "GenSigStartValue" SG_ 264 ARS_RDI_ElevationAng_Clu_061 63;
BA_ "GenSigStartValue" SG_ 264 ARS_RDI_VradRel_Clu_062 1200;
BA_ "GenSigStartValue" SG_ 264 ARS_RDI_RCS_Clu_062 256;
BA_ "GenSigStartValue" SG_ 264 ARS_RDI_AzimuthAng_Clu_062 511;
BA_ "GenSigStartValue" SG_ 264 ARS_RDI_ElevationAng_Clu_062 63;
BA_ "GenSigStartValue" SG_ 264 ARS_RDI_ElevationAng_Clu_056 63;
BA_ "GenSigStartValue" SG_ 264 ARS_RDI_VradRel_Clu_063 1200;
BA_ "GenSigStartValue" SG_ 264 ARS_RDI_RCS_Clu_063 256;
BA_ "GenSigStartValue" SG_ 264 ARS_RDI_AzimuthAng_Clu_063 511;
BA_ "GenSigStartValue" SG_ 264 ARS_RDI_ElevationAng_Clu_063 63;
BA_ "SystemSignalLongSymbol" SG_ 264 ARS_RDI_CRC16_Checksum_Clu_056_0 "ARS_RDI_CRC16_Checksum_Clu_056_063";
BA_ "GenSigStartValue" SG_ 264 ARS_RDI_VradRel_Clu_057 1200;
BA_ "GenSigStartValue" SG_ 264 ARS_RDI_RCS_Clu_057 256;
BA_ "GenSigStartValue" SG_ 264 ARS_RDI_AzimuthAng_Clu_057 511;
BA_ "GenSigStartValue" SG_ 265 ARS_RDI_ElevationAng_Clu_065 63;
BA_ "GenSigStartValue" SG_ 265 ARS_RDI_VradRel_Clu_064 1200;
BA_ "GenSigStartValue" SG_ 265 ARS_RDI_VradRel_Clu_066 1200;
BA_ "GenSigStartValue" SG_ 265 ARS_RDI_RCS_Clu_066 256;
BA_ "GenSigStartValue" SG_ 265 ARS_RDI_AzimuthAng_Clu_066 511;
BA_ "GenSigStartValue" SG_ 265 ARS_RDI_ElevationAng_Clu_066 63;
BA_ "GenSigStartValue" SG_ 265 ARS_RDI_VradRel_Clu_067 1200;
BA_ "GenSigStartValue" SG_ 265 ARS_RDI_RCS_Clu_067 256;
BA_ "GenSigStartValue" SG_ 265 ARS_RDI_AzimuthAng_Clu_067 511;
BA_ "GenSigStartValue" SG_ 265 ARS_RDI_ElevationAng_Clu_067 63;
BA_ "GenSigStartValue" SG_ 265 ARS_RDI_RCS_Clu_064 256;
BA_ "GenSigStartValue" SG_ 265 ARS_RDI_VradRel_Clu_068 1200;
BA_ "GenSigStartValue" SG_ 265 ARS_RDI_RCS_Clu_068 256;
BA_ "GenSigStartValue" SG_ 265 ARS_RDI_AzimuthAng_Clu_068 511;
BA_ "GenSigStartValue" SG_ 265 ARS_RDI_ElevationAng_Clu_068 63;
BA_ "GenSigStartValue" SG_ 265 ARS_RDI_VradRel_Clu_069 1200;
BA_ "GenSigStartValue" SG_ 265 ARS_RDI_RCS_Clu_069 256;
BA_ "GenSigStartValue" SG_ 265 ARS_RDI_AzimuthAng_Clu_064 511;
BA_ "GenSigStartValue" SG_ 265 ARS_RDI_AzimuthAng_Clu_069 511;
BA_ "GenSigStartValue" SG_ 265 ARS_RDI_ElevationAng_Clu_069 63;
BA_ "GenSigStartValue" SG_ 265 ARS_RDI_VradRel_Clu_070 1200;
BA_ "GenSigStartValue" SG_ 265 ARS_RDI_RCS_Clu_070 256;
BA_ "GenSigStartValue" SG_ 265 ARS_RDI_AzimuthAng_Clu_070 511;
BA_ "GenSigStartValue" SG_ 265 ARS_RDI_ElevationAng_Clu_070 63;
BA_ "GenSigStartValue" SG_ 265 ARS_RDI_ElevationAng_Clu_064 63;
BA_ "GenSigStartValue" SG_ 265 ARS_RDI_VradRel_Clu_071 1200;
BA_ "GenSigStartValue" SG_ 265 ARS_RDI_RCS_Clu_071 256;
BA_ "GenSigStartValue" SG_ 265 ARS_RDI_AzimuthAng_Clu_071 511;
BA_ "GenSigStartValue" SG_ 265 ARS_RDI_ElevationAng_Clu_071 63;
BA_ "SystemSignalLongSymbol" SG_ 265 ARS_RDI_CRC16_Checksum_Clu_064_0 "ARS_RDI_CRC16_Checksum_Clu_064_071";
BA_ "GenSigStartValue" SG_ 265 ARS_RDI_VradRel_Clu_065 1200;
BA_ "GenSigStartValue" SG_ 265 ARS_RDI_RCS_Clu_065 256;
BA_ "GenSigStartValue" SG_ 265 ARS_RDI_AzimuthAng_Clu_065 511;
BA_ "GenSigStartValue" SG_ 266 ARS_RDI_ElevationAng_Clu_073 63;
BA_ "GenSigStartValue" SG_ 266 ARS_RDI_VradRel_Clu_072 1200;
BA_ "GenSigStartValue" SG_ 266 ARS_RDI_VradRel_Clu_074 1200;
BA_ "GenSigStartValue" SG_ 266 ARS_RDI_RCS_Clu_074 256;
BA_ "GenSigStartValue" SG_ 266 ARS_RDI_AzimuthAng_Clu_074 511;
BA_ "GenSigStartValue" SG_ 266 ARS_RDI_ElevationAng_Clu_074 63;
BA_ "GenSigStartValue" SG_ 266 ARS_RDI_VradRel_Clu_075 1200;
BA_ "GenSigStartValue" SG_ 266 ARS_RDI_RCS_Clu_075 256;
BA_ "GenSigStartValue" SG_ 266 ARS_RDI_AzimuthAng_Clu_075 511;
BA_ "GenSigStartValue" SG_ 266 ARS_RDI_ElevationAng_Clu_075 63;
BA_ "GenSigStartValue" SG_ 266 ARS_RDI_RCS_Clu_072 256;
BA_ "GenSigStartValue" SG_ 266 ARS_RDI_VradRel_Clu_076 1200;
BA_ "GenSigStartValue" SG_ 266 ARS_RDI_RCS_Clu_076 256;
BA_ "GenSigStartValue" SG_ 266 ARS_RDI_AzimuthAng_Clu_076 511;
BA_ "GenSigStartValue" SG_ 266 ARS_RDI_ElevationAng_Clu_076 63;
BA_ "GenSigStartValue" SG_ 266 ARS_RDI_VradRel_Clu_077 1200;
BA_ "GenSigStartValue" SG_ 266 ARS_RDI_RCS_Clu_077 256;
BA_ "GenSigStartValue" SG_ 266 ARS_RDI_AzimuthAng_Clu_072 511;
BA_ "GenSigStartValue" SG_ 266 ARS_RDI_AzimuthAng_Clu_077 511;
BA_ "GenSigStartValue" SG_ 266 ARS_RDI_ElevationAng_Clu_077 63;
BA_ "GenSigStartValue" SG_ 266 ARS_RDI_VradRel_Clu_078 1200;
BA_ "GenSigStartValue" SG_ 266 ARS_RDI_RCS_Clu_078 256;
BA_ "GenSigStartValue" SG_ 266 ARS_RDI_AzimuthAng_Clu_078 511;
BA_ "GenSigStartValue" SG_ 266 ARS_RDI_ElevationAng_Clu_078 63;
BA_ "GenSigStartValue" SG_ 266 ARS_RDI_ElevationAng_Clu_072 63;
BA_ "GenSigStartValue" SG_ 266 ARS_RDI_VradRel_Clu_079 1200;
BA_ "GenSigStartValue" SG_ 266 ARS_RDI_RCS_Clu_079 256;
BA_ "GenSigStartValue" SG_ 266 ARS_RDI_AzimuthAng_Clu_079 511;
BA_ "GenSigStartValue" SG_ 266 ARS_RDI_ElevationAng_Clu_079 63;
BA_ "SystemSignalLongSymbol" SG_ 266 ARS_RDI_CRC16_Checksum_Clu_072_0 "ARS_RDI_CRC16_Checksum_Clu_072_079";
BA_ "GenSigStartValue" SG_ 266 ARS_RDI_VradRel_Clu_073 1200;
BA_ "GenSigStartValue" SG_ 266 ARS_RDI_RCS_Clu_073 256;
BA_ "GenSigStartValue" SG_ 266 ARS_RDI_AzimuthAng_Clu_073 511;
BA_ "GenSigStartValue" SG_ 267 ARS_RDI_ElevationAng_Clu_081 63;
BA_ "GenSigStartValue" SG_ 267 ARS_RDI_VradRel_Clu_080 1200;
BA_ "GenSigStartValue" SG_ 267 ARS_RDI_VradRel_Clu_082 1200;
BA_ "GenSigStartValue" SG_ 267 ARS_RDI_RCS_Clu_082 256;
BA_ "GenSigStartValue" SG_ 267 ARS_RDI_AzimuthAng_Clu_082 511;
BA_ "GenSigStartValue" SG_ 267 ARS_RDI_ElevationAng_Clu_082 63;
BA_ "GenSigStartValue" SG_ 267 ARS_RDI_VradRel_Clu_083 1200;
BA_ "GenSigStartValue" SG_ 267 ARS_RDI_RCS_Clu_083 256;
BA_ "GenSigStartValue" SG_ 267 ARS_RDI_AzimuthAng_Clu_083 511;
BA_ "GenSigStartValue" SG_ 267 ARS_RDI_ElevationAng_Clu_083 63;
BA_ "GenSigStartValue" SG_ 267 ARS_RDI_RCS_Clu_080 256;
BA_ "GenSigStartValue" SG_ 267 ARS_RDI_VradRel_Clu_084 1200;
BA_ "GenSigStartValue" SG_ 267 ARS_RDI_RCS_Clu_084 256;
BA_ "GenSigStartValue" SG_ 267 ARS_RDI_AzimuthAng_Clu_084 511;
BA_ "GenSigStartValue" SG_ 267 ARS_RDI_ElevationAng_Clu_084 63;
BA_ "GenSigStartValue" SG_ 267 ARS_RDI_VradRel_Clu_085 1200;
BA_ "GenSigStartValue" SG_ 267 ARS_RDI_RCS_Clu_085 256;
BA_ "GenSigStartValue" SG_ 267 ARS_RDI_AzimuthAng_Clu_080 511;
BA_ "GenSigStartValue" SG_ 267 ARS_RDI_AzimuthAng_Clu_085 511;
BA_ "GenSigStartValue" SG_ 267 ARS_RDI_ElevationAng_Clu_085 63;
BA_ "GenSigStartValue" SG_ 267 ARS_RDI_VradRel_Clu_086 1200;
BA_ "GenSigStartValue" SG_ 267 ARS_RDI_RCS_Clu_086 256;
BA_ "GenSigStartValue" SG_ 267 ARS_RDI_AzimuthAng_Clu_086 511;
BA_ "GenSigStartValue" SG_ 267 ARS_RDI_ElevationAng_Clu_086 63;
BA_ "GenSigStartValue" SG_ 267 ARS_RDI_ElevationAng_Clu_080 63;
BA_ "GenSigStartValue" SG_ 267 ARS_RDI_VradRel_Clu_087 1200;
BA_ "GenSigStartValue" SG_ 267 ARS_RDI_RCS_Clu_087 256;
BA_ "GenSigStartValue" SG_ 267 ARS_RDI_AzimuthAng_Clu_087 511;
BA_ "GenSigStartValue" SG_ 267 ARS_RDI_ElevationAng_Clu_087 63;
BA_ "SystemSignalLongSymbol" SG_ 267 ARS_RDI_CRC16_Checksum_Clu_080_0 "ARS_RDI_CRC16_Checksum_Clu_080_087";
BA_ "GenSigStartValue" SG_ 267 ARS_RDI_VradRel_Clu_081 1200;
BA_ "GenSigStartValue" SG_ 267 ARS_RDI_RCS_Clu_081 256;
BA_ "GenSigStartValue" SG_ 267 ARS_RDI_AzimuthAng_Clu_081 511;
BA_ "GenSigStartValue" SG_ 268 ARS_RDI_ElevationAng_Clu_089 63;
BA_ "GenSigStartValue" SG_ 268 ARS_RDI_VradRel_Clu_088 1200;
BA_ "GenSigStartValue" SG_ 268 ARS_RDI_VradRel_Clu_090 1200;
BA_ "GenSigStartValue" SG_ 268 ARS_RDI_RCS_Clu_090 256;
BA_ "GenSigStartValue" SG_ 268 ARS_RDI_AzimuthAng_Clu_090 511;
BA_ "GenSigStartValue" SG_ 268 ARS_RDI_ElevationAng_Clu_090 63;
BA_ "GenSigStartValue" SG_ 268 ARS_RDI_VradRel_Clu_091 1200;
BA_ "GenSigStartValue" SG_ 268 ARS_RDI_RCS_Clu_091 256;
BA_ "GenSigStartValue" SG_ 268 ARS_RDI_AzimuthAng_Clu_091 511;
BA_ "GenSigStartValue" SG_ 268 ARS_RDI_ElevationAng_Clu_091 63;
BA_ "GenSigStartValue" SG_ 268 ARS_RDI_RCS_Clu_088 256;
BA_ "GenSigStartValue" SG_ 268 ARS_RDI_VradRel_Clu_092 1200;
BA_ "GenSigStartValue" SG_ 268 ARS_RDI_RCS_Clu_092 256;
BA_ "GenSigStartValue" SG_ 268 ARS_RDI_AzimuthAng_Clu_092 511;
BA_ "GenSigStartValue" SG_ 268 ARS_RDI_ElevationAng_Clu_092 63;
BA_ "GenSigStartValue" SG_ 268 ARS_RDI_VradRel_Clu_093 1200;
BA_ "GenSigStartValue" SG_ 268 ARS_RDI_RCS_Clu_093 256;
BA_ "GenSigStartValue" SG_ 268 ARS_RDI_AzimuthAng_Clu_088 511;
BA_ "GenSigStartValue" SG_ 268 ARS_RDI_AzimuthAng_Clu_093 511;
BA_ "GenSigStartValue" SG_ 268 ARS_RDI_ElevationAng_Clu_093 63;
BA_ "GenSigStartValue" SG_ 268 ARS_RDI_VradRel_Clu_094 1200;
BA_ "GenSigStartValue" SG_ 268 ARS_RDI_RCS_Clu_094 256;
BA_ "GenSigStartValue" SG_ 268 ARS_RDI_AzimuthAng_Clu_094 511;
BA_ "GenSigStartValue" SG_ 268 ARS_RDI_ElevationAng_Clu_094 63;
BA_ "GenSigStartValue" SG_ 268 ARS_RDI_ElevationAng_Clu_088 63;
BA_ "GenSigStartValue" SG_ 268 ARS_RDI_VradRel_Clu_095 1200;
BA_ "GenSigStartValue" SG_ 268 ARS_RDI_RCS_Clu_095 256;
BA_ "GenSigStartValue" SG_ 268 ARS_RDI_AzimuthAng_Clu_095 511;
BA_ "GenSigStartValue" SG_ 268 ARS_RDI_ElevationAng_Clu_095 63;
BA_ "SystemSignalLongSymbol" SG_ 268 ARS_RDI_CRC16_Checksum_Clu_088_0 "ARS_RDI_CRC16_Checksum_Clu_088_095";
BA_ "GenSigStartValue" SG_ 268 ARS_RDI_VradRel_Clu_089 1200;
BA_ "GenSigStartValue" SG_ 268 ARS_RDI_RCS_Clu_089 256;
BA_ "GenSigStartValue" SG_ 268 ARS_RDI_AzimuthAng_Clu_089 511;
BA_ "GenSigStartValue" SG_ 269 ARS_RDI_ElevationAng_Clu_097 63;
BA_ "GenSigStartValue" SG_ 269 ARS_RDI_VradRel_Clu_096 1200;
BA_ "GenSigStartValue" SG_ 269 ARS_RDI_VradRel_Clu_098 1200;
BA_ "GenSigStartValue" SG_ 269 ARS_RDI_RCS_Clu_098 256;
BA_ "GenSigStartValue" SG_ 269 ARS_RDI_AzimuthAng_Clu_098 511;
BA_ "GenSigStartValue" SG_ 269 ARS_RDI_ElevationAng_Clu_098 63;
BA_ "GenSigStartValue" SG_ 269 ARS_RDI_VradRel_Clu_099 1200;
BA_ "GenSigStartValue" SG_ 269 ARS_RDI_RCS_Clu_099 256;
BA_ "GenSigStartValue" SG_ 269 ARS_RDI_AzimuthAng_Clu_099 511;
BA_ "GenSigStartValue" SG_ 269 ARS_RDI_ElevationAng_Clu_099 63;
BA_ "GenSigStartValue" SG_ 269 ARS_RDI_RCS_Clu_096 256;
BA_ "GenSigStartValue" SG_ 269 ARS_RDI_VradRel_Clu_100 1200;
BA_ "GenSigStartValue" SG_ 269 ARS_RDI_RCS_Clu_100 256;
BA_ "GenSigStartValue" SG_ 269 ARS_RDI_AzimuthAng_Clu_100 511;
BA_ "GenSigStartValue" SG_ 269 ARS_RDI_ElevationAng_Clu_100 63;
BA_ "GenSigStartValue" SG_ 269 ARS_RDI_VradRel_Clu_101 1200;
BA_ "GenSigStartValue" SG_ 269 ARS_RDI_RCS_Clu_101 256;
BA_ "GenSigStartValue" SG_ 269 ARS_RDI_AzimuthAng_Clu_096 511;
BA_ "GenSigStartValue" SG_ 269 ARS_RDI_AzimuthAng_Clu_101 511;
BA_ "GenSigStartValue" SG_ 269 ARS_RDI_ElevationAng_Clu_101 63;
BA_ "GenSigStartValue" SG_ 269 ARS_RDI_VradRel_Clu_102 1200;
BA_ "GenSigStartValue" SG_ 269 ARS_RDI_RCS_Clu_102 256;
BA_ "GenSigStartValue" SG_ 269 ARS_RDI_AzimuthAng_Clu_102 511;
BA_ "GenSigStartValue" SG_ 269 ARS_RDI_ElevationAng_Clu_102 63;
BA_ "GenSigStartValue" SG_ 269 ARS_RDI_ElevationAng_Clu_096 63;
BA_ "GenSigStartValue" SG_ 269 ARS_RDI_VradRel_Clu_103 1200;
BA_ "GenSigStartValue" SG_ 269 ARS_RDI_RCS_Clu_103 256;
BA_ "GenSigStartValue" SG_ 269 ARS_RDI_AzimuthAng_Clu_103 511;
BA_ "GenSigStartValue" SG_ 269 ARS_RDI_ElevationAng_Clu_103 63;
BA_ "SystemSignalLongSymbol" SG_ 269 ARS_RDI_CRC16_Checksum_Clu_096_1 "ARS_RDI_CRC16_Checksum_Clu_096_103";
BA_ "GenSigStartValue" SG_ 269 ARS_RDI_VradRel_Clu_097 1200;
BA_ "GenSigStartValue" SG_ 269 ARS_RDI_RCS_Clu_097 256;
BA_ "GenSigStartValue" SG_ 269 ARS_RDI_AzimuthAng_Clu_097 511;
BA_ "GenSigStartValue" SG_ 270 ARS_RDI_ElevationAng_Clu_105 63;
BA_ "GenSigStartValue" SG_ 270 ARS_RDI_VradRel_Clu_104 1200;
BA_ "GenSigStartValue" SG_ 270 ARS_RDI_VradRel_Clu_106 1200;
BA_ "GenSigStartValue" SG_ 270 ARS_RDI_RCS_Clu_106 256;
BA_ "GenSigStartValue" SG_ 270 ARS_RDI_AzimuthAng_Clu_106 511;
BA_ "GenSigStartValue" SG_ 270 ARS_RDI_ElevationAng_Clu_106 63;
BA_ "GenSigStartValue" SG_ 270 ARS_RDI_VradRel_Clu_107 1200;
BA_ "GenSigStartValue" SG_ 270 ARS_RDI_RCS_Clu_107 256;
BA_ "GenSigStartValue" SG_ 270 ARS_RDI_AzimuthAng_Clu_107 511;
BA_ "GenSigStartValue" SG_ 270 ARS_RDI_ElevationAng_Clu_107 63;
BA_ "GenSigStartValue" SG_ 270 ARS_RDI_RCS_Clu_104 256;
BA_ "GenSigStartValue" SG_ 270 ARS_RDI_VradRel_Clu_108 1200;
BA_ "GenSigStartValue" SG_ 270 ARS_RDI_RCS_Clu_108 256;
BA_ "GenSigStartValue" SG_ 270 ARS_RDI_AzimuthAng_Clu_108 511;
BA_ "GenSigStartValue" SG_ 270 ARS_RDI_ElevationAng_Clu_108 63;
BA_ "GenSigStartValue" SG_ 270 ARS_RDI_VradRel_Clu_109 1200;
BA_ "GenSigStartValue" SG_ 270 ARS_RDI_RCS_Clu_109 256;
BA_ "GenSigStartValue" SG_ 270 ARS_RDI_AzimuthAng_Clu_104 511;
BA_ "GenSigStartValue" SG_ 270 ARS_RDI_AzimuthAng_Clu_109 511;
BA_ "GenSigStartValue" SG_ 270 ARS_RDI_ElevationAng_Clu_109 63;
BA_ "GenSigStartValue" SG_ 270 ARS_RDI_VradRel_Clu_110 1200;
BA_ "GenSigStartValue" SG_ 270 ARS_RDI_RCS_Clu_110 256;
BA_ "GenSigStartValue" SG_ 270 ARS_RDI_AzimuthAng_Clu_110 511;
BA_ "GenSigStartValue" SG_ 270 ARS_RDI_ElevationAng_Clu_110 63;
BA_ "GenSigStartValue" SG_ 270 ARS_RDI_ElevationAng_Clu_104 63;
BA_ "GenSigStartValue" SG_ 270 ARS_RDI_VradRel_Clu_111 1200;
BA_ "GenSigStartValue" SG_ 270 ARS_RDI_RCS_Clu_111 256;
BA_ "GenSigStartValue" SG_ 270 ARS_RDI_AzimuthAng_Clu_111 511;
BA_ "GenSigStartValue" SG_ 270 ARS_RDI_ElevationAng_Clu_111 63;
BA_ "SystemSignalLongSymbol" SG_ 270 ARS_RDI_CRC16_Checksum_Clu_104_1 "ARS_RDI_CRC16_Checksum_Clu_104_111";
BA_ "GenSigStartValue" SG_ 270 ARS_RDI_VradRel_Clu_105 1200;
BA_ "GenSigStartValue" SG_ 270 ARS_RDI_RCS_Clu_105 256;
BA_ "GenSigStartValue" SG_ 270 ARS_RDI_AzimuthAng_Clu_105 511;
BA_ "GenSigStartValue" SG_ 271 ARS_RDI_ElevationAng_Clu_113 63;
BA_ "GenSigStartValue" SG_ 271 ARS_RDI_VradRel_Clu_112 1200;
BA_ "GenSigStartValue" SG_ 271 ARS_RDI_VradRel_Clu_114 1200;
BA_ "GenSigStartValue" SG_ 271 ARS_RDI_RCS_Clu_114 256;
BA_ "GenSigStartValue" SG_ 271 ARS_RDI_AzimuthAng_Clu_114 511;
BA_ "GenSigStartValue" SG_ 271 ARS_RDI_ElevationAng_Clu_114 63;
BA_ "GenSigStartValue" SG_ 271 ARS_RDI_VradRel_Clu_115 1200;
BA_ "GenSigStartValue" SG_ 271 ARS_RDI_RCS_Clu_115 256;
BA_ "GenSigStartValue" SG_ 271 ARS_RDI_AzimuthAng_Clu_115 511;
BA_ "GenSigStartValue" SG_ 271 ARS_RDI_ElevationAng_Clu_115 63;
BA_ "GenSigStartValue" SG_ 271 ARS_RDI_RCS_Clu_112 256;
BA_ "GenSigStartValue" SG_ 271 ARS_RDI_VradRel_Clu_116 1200;
BA_ "GenSigStartValue" SG_ 271 ARS_RDI_RCS_Clu_116 256;
BA_ "GenSigStartValue" SG_ 271 ARS_RDI_AzimuthAng_Clu_116 511;
BA_ "GenSigStartValue" SG_ 271 ARS_RDI_ElevationAng_Clu_116 63;
BA_ "GenSigStartValue" SG_ 271 ARS_RDI_VradRel_Clu_117 1200;
BA_ "GenSigStartValue" SG_ 271 ARS_RDI_RCS_Clu_117 256;
BA_ "GenSigStartValue" SG_ 271 ARS_RDI_AzimuthAng_Clu_112 511;
BA_ "GenSigStartValue" SG_ 271 ARS_RDI_AzimuthAng_Clu_117 511;
BA_ "GenSigStartValue" SG_ 271 ARS_RDI_ElevationAng_Clu_117 63;
BA_ "GenSigStartValue" SG_ 271 ARS_RDI_VradRel_Clu_118 1200;
BA_ "GenSigStartValue" SG_ 271 ARS_RDI_RCS_Clu_118 256;
BA_ "GenSigStartValue" SG_ 271 ARS_RDI_AzimuthAng_Clu_118 511;
BA_ "GenSigStartValue" SG_ 271 ARS_RDI_ElevationAng_Clu_118 63;
BA_ "GenSigStartValue" SG_ 271 ARS_RDI_ElevationAng_Clu_112 63;
BA_ "GenSigStartValue" SG_ 271 ARS_RDI_VradRel_Clu_119 1200;
BA_ "GenSigStartValue" SG_ 271 ARS_RDI_RCS_Clu_119 256;
BA_ "GenSigStartValue" SG_ 271 ARS_RDI_AzimuthAng_Clu_119 511;
BA_ "GenSigStartValue" SG_ 271 ARS_RDI_ElevationAng_Clu_119 63;
BA_ "SystemSignalLongSymbol" SG_ 271 ARS_RDI_CRC16_Checksum_Clu_112_1 "ARS_RDI_CRC16_Checksum_Clu_112_119";
BA_ "GenSigStartValue" SG_ 271 ARS_RDI_VradRel_Clu_113 1200;
BA_ "GenSigStartValue" SG_ 271 ARS_RDI_RCS_Clu_113 256;
BA_ "GenSigStartValue" SG_ 271 ARS_RDI_AzimuthAng_Clu_113 511;
BA_ "GenSigStartValue" SG_ 272 ARS_RDI_ElevationAng_Clu_121 63;
BA_ "GenSigStartValue" SG_ 272 ARS_RDI_VradRel_Clu_120 1200;
BA_ "GenSigStartValue" SG_ 272 ARS_RDI_VradRel_Clu_122 1200;
BA_ "GenSigStartValue" SG_ 272 ARS_RDI_RCS_Clu_122 256;
BA_ "GenSigStartValue" SG_ 272 ARS_RDI_AzimuthAng_Clu_122 511;
BA_ "GenSigStartValue" SG_ 272 ARS_RDI_ElevationAng_Clu_122 63;
BA_ "GenSigStartValue" SG_ 272 ARS_RDI_VradRel_Clu_123 1200;
BA_ "GenSigStartValue" SG_ 272 ARS_RDI_RCS_Clu_123 256;
BA_ "GenSigStartValue" SG_ 272 ARS_RDI_AzimuthAng_Clu_123 511;
BA_ "GenSigStartValue" SG_ 272 ARS_RDI_ElevationAng_Clu_123 63;
BA_ "GenSigStartValue" SG_ 272 ARS_RDI_RCS_Clu_120 256;
BA_ "GenSigStartValue" SG_ 272 ARS_RDI_VradRel_Clu_124 1200;
BA_ "GenSigStartValue" SG_ 272 ARS_RDI_RCS_Clu_124 256;
BA_ "GenSigStartValue" SG_ 272 ARS_RDI_AzimuthAng_Clu_124 511;
BA_ "GenSigStartValue" SG_ 272 ARS_RDI_ElevationAng_Clu_124 63;
BA_ "GenSigStartValue" SG_ 272 ARS_RDI_VradRel_Clu_125 1200;
BA_ "GenSigStartValue" SG_ 272 ARS_RDI_RCS_Clu_125 256;
BA_ "GenSigStartValue" SG_ 272 ARS_RDI_AzimuthAng_Clu_120 511;
BA_ "GenSigStartValue" SG_ 272 ARS_RDI_AzimuthAng_Clu_125 511;
BA_ "GenSigStartValue" SG_ 272 ARS_RDI_ElevationAng_Clu_125 63;
BA_ "GenSigStartValue" SG_ 272 ARS_RDI_VradRel_Clu_126 1200;
BA_ "GenSigStartValue" SG_ 272 ARS_RDI_RCS_Clu_126 256;
BA_ "GenSigStartValue" SG_ 272 ARS_RDI_AzimuthAng_Clu_126 511;
BA_ "GenSigStartValue" SG_ 272 ARS_RDI_ElevationAng_Clu_126 63;
BA_ "GenSigStartValue" SG_ 272 ARS_RDI_ElevationAng_Clu_120 63;
BA_ "GenSigStartValue" SG_ 272 ARS_RDI_VradRel_Clu_127 1200;
BA_ "GenSigStartValue" SG_ 272 ARS_RDI_RCS_Clu_127 256;
BA_ "GenSigStartValue" SG_ 272 ARS_RDI_AzimuthAng_Clu_127 511;
BA_ "GenSigStartValue" SG_ 272 ARS_RDI_ElevationAng_Clu_127 63;
BA_ "SystemSignalLongSymbol" SG_ 272 ARS_RDI_CRC16_Checksum_Clu_120_1 "ARS_RDI_CRC16_Checksum_Clu_120_127";
BA_ "GenSigStartValue" SG_ 272 ARS_RDI_VradRel_Clu_121 1200;
BA_ "GenSigStartValue" SG_ 272 ARS_RDI_RCS_Clu_121 256;
BA_ "GenSigStartValue" SG_ 272 ARS_RDI_AzimuthAng_Clu_121 511;
VAL_ 33 ADCU_TSYNC_Type 32 "SYNC" 40 "FUP" ;
VAL_ 64 GW_ACU_LongAccel_ValidFlag 0 "INVALID" 1 "VALID" ;
VAL_ 64 GW_ACU_LateralAccel_ValidFlag 0 "INVALID" 1 "VALID" ;
VAL_ 64 GW_ACU_YawRate_ValidFlag 0 "INVALID" 1 "VALID" ;
VAL_ 65 GW_ESC_WheelSpeed_FL_VldFlg 0 "INVALID" 1 "VALID" ;
VAL_ 65 GW_ESC_WheelDirection_FL 0 "INVALID" 1 "FORWARD" 2 "BACKWARD" 3 "STANDSTILL" ;
VAL_ 65 GW_ESC_WheelSpeed_FR_VldFlg 0 "INVALID" 1 "VALID" ;
VAL_ 65 GW_ESC_WheelDirection_FR 0 "INVALID" 1 "FORWARD" 2 "BACKWARD" 3 "STANDSTILL" ;
VAL_ 65 GW_ESC_WheelSpeed_RL_VldFlg 0 "INVALID" 1 "VALID" ;
VAL_ 65 GW_ESC_WheelDirection_RL 0 "INVALID" 1 "FORWARD" 2 "BACKWARD" 3 "STANDSTILL" ;
VAL_ 65 GW_ESC_WheelSpeed_RR_VldFlg 0 "INVALID" 1 "VALID" ;
VAL_ 65 GW_ESC_WheelDirection_RR 0 "INVALID" 1 "FORWARD" 2 "BACKWARD" 3 "STANDSTILL" ;
VAL_ 65 GW_ESC_WheelDirection_FL_VldFlg 0 "INVALID" 1 "VALID" ;
VAL_ 65 GW_ESC_WheelDirection_FR_VldFlg 0 "INVALID" 1 "VALID" ;
VAL_ 65 GW_ESC_WheelDirection_RL_VldFlg 0 "INVALID" 1 "VALID" ;
VAL_ 65 GW_ESC_WheelDirection_RR_VldFlg 0 "INVALID" 1 "VALID" ;
VAL_ 65 GW_ESC_ABS_ActiveFlag 0 "INACTIVATE" 1 "ACTIVATE" ;
VAL_ 65 GW_ESC_ABS_ValidFlag 0 "INVALID" 1 "VALID" ;
VAL_ 65 GW_ESC_TCS_ActiveFlag 0 "INACTIVATE" 1 "ACTIVATE" ;
VAL_ 65 GW_ESC_TCS_ValidFlag 0 "INVALID" 1 "VALID" ;
VAL_ 65 GW_ESC_VehicleSpeed_ValidFlag 0 "INVALID" 1 "VALID" ;
VAL_ 65 GW_ESC_EPB_ActiveFlag 0 "INACTIVATE" 1 "ACTIVATE" ;
VAL_ 65 GW_ESC_EPB_ValidFlag 0 "INVALID" 1 "VALID" ;
VAL_ 66 GW_SAS_SteeringWheelAngle_VldFlg 0 "INVALID" 1 "VALID" ;
VAL_ 67 GW_TM_PowerModeStatus 3 "RUN" 2 "ACC" 1 "AWAKE" 0 "OFF" ;
VAL_ 67 GW_TM_GearPosition 7 "RESERVED" 6 "RESERVED" 5 "RESERVED" 4 "RESERVED" 3 "SHIFT_IN_DRIVE" 2 "SHIFT_IN_NEUTRAL" 0 "SHIFT_IN_PARKING" 1 "SHIFT_IN_REVERSE" ;
VAL_ 67 GW_TM_GearPosition_ValidFlag 0 "INVALID" 1 "VALID" ;
VAL_ 68 GW_TBOX_AbsoluteTime_Year 255 "INVALID" ;
VAL_ 68 GW_TBOX_AbsoluteTime_Month 15 "INVALID" ;
VAL_ 68 GW_TBOX_AbsoluteTime_Day 63 "INVALID" ;
VAL_ 68 GW_TBOX_AbsoluteTime_Hour 31 "INVALID" ;
VAL_ 68 GW_TBOX_AbsoluteTime_Minute 63 "INVALID" ;
VAL_ 68 GW_TBOX_AbsoluteTime_Second 63 "INVALID" ;
VAL_ 69 GW_IDCM_VehicleTotalMileage 16777215 "INVALID" ;
VAL_ 70 GW_SENCFG_ID 5 "REAR" 4 "REAR_RIGHT" 3 "REAR_LEFT" 2 "FRONT_RIGHT" 1 "FRONT_LEFT" 15 "INVALID" 0 "FRONT" ;
VAL_ 80 ARS_CFG_Mode 1 "MODE_A" 2 "MODE_B" 4 "MODE_C" 8 "RESERVED" 16 "RESERVED" 64 "RESERVED" 128 "RESERVED" ;
VAL_ 80 ARS_CFG_VParAxisLdDistr_CFGflag 0 "DEFAULT" 1 "CONFIGURED" ;
VAL_ 80 ARS_CFG_VParCntrOGrvHght_CFGflag 0 "DEFAULT" 1 "CONFIGURED" ;
VAL_ 80 ARS_CFG_VParVehWeight_CFGflag 0 "DEFAULT" 1 "CONFIGURED" ;
VAL_ 80 ARS_CFG_VParTrkWdthRear_CFGflag 0 "DEFAULT" 1 "CONFIGURED" ;
VAL_ 80 ARS_CFG_VParTrkWdthFrnt_CFGflag 0 "DEFAULT" 1 "CONFIGURED" ;
VAL_ 80 ARS_CFG_VParWheelBase_CFGflag 0 "DEFAULT" 1 "CONFIGURED" ;
VAL_ 80 ARS_CFG_VParStrRatio_CFGflag 0 "DEFAULT" 1 "CONFIGURED" ;
VAL_ 80 ARS_CFG_TimeSyncEnableFlag 0 "DISABLED" 1 "ENABLED" ;
VAL_ 80 ARS_CFG_VParLatPos_CFGflag 0 "DEFAULT" 1 "CONFIGURED" ;
VAL_ 80 ARS_CFG_SensorID 5 "REAR" 0 "FRONT" ;
VAL_ 80 ARS_CFG_SensorID_CFGflag 0 "DEFAULT" 1 "CONFIGURED" ;
VAL_ 80 ARS_CFG_VParLongPos_CFGflag 0 "DEFAULT" 1 "CONFIGURED" ;
VAL_ 80 ARS_CFG_VParVertPos_CFGflag 0 "DEFAULT" 1 "CONFIGURED" ;
VAL_ 80 ARS_CFG_VParLngPos2CoG_CFGflag 0 "DEFAULT" 1 "CONFIGURED" ;
VAL_ 80 ARS_CFG_VParSnsrOrnt 0 "DRIVER_SID" 1 "PASSENGER_SID" ;
VAL_ 80 ARS_CFG_VParSnsrOrnt_CFGflag 0 "DEFAULT" 1 "CONFIGURED" ;
VAL_ 80 ARS_CFG_VParYawAngle_CFGflag 0 "DEFAULT" 1 "CONFIGURED" ;
VAL_ 80 ARS_CFG_VParCoverDamping_CFGflag 0 "DEFAULT" 1 "CONFIGURED" ;
VAL_ 82 ARS_SP_OperationMode 0 "OPMODE_INIT" 1 "OPMODE_SELFTEST" 2 "OPMODE_NORMAL" 3 "OPMODE_DEGRADED" 4 "OPMODE_PARTIAL_BLOCKED" 5 "OPMODE_BLOCKED" 6 "OPMODE_EOL" 7 "OPMODE_SA" 8 "OPMODE_AUTO_ALIGN" 9 "RESERVED" 10 "RESERVED" 11 "RESERVED" 12 "RESERVED" 13 "RESERVED" 14 "RESERVED" 15 "RESERVED" ;
VAL_ 82 ARS_SP_CalibrationState 0 "SENSOR_NEVER_ALIGNED" 1 "SENSOR_CALIBRATED" 2 "MISALIGNMENT_DETECTED" 3 "CALIBRATION_IN_PROGRESS" 4 "RESERVED" 5 "RESERVED" 6 "RESERVED" 7 "RESERVED" ;
VAL_ 82 ARS_SP_TunnelFlag 0 "FALSE" 1 "TRUE" ;
VAL_ 82 ARS_SP_ErrStateGroup_1 1 "VOLTAGE_TOO_LOW" 2 "VOLTAGE_TOO_HIGH" 4 "SENSOR_NEVER_ALIGNED" 8 "EOL_SERVICE_ALIGNMENT_FAILED" 16 "ONLINE_CALIBRATION_FAILED" 32 "HW_DEFECT" 64 "HW_PLAUSIBILITY_CHECK_FAILED" 128 "TEMPERATURE_MON_FAILED" ;
VAL_ 82 ARS_SP_ErrStateGroup_2 1 "PARTIAL_BLOCKAGE" 2 "FULL_BLOCKAGE" 4 "VEH_PAR_EXCEPTION" 8 "VEH_SIG_EXCEPTION" 16 "NVM_ACCESS_ERROR" 32 "LOST_COMMUNICATION" 64 "BUS_OFF" 128 "TIME_SYNC_ERROR" ;
VAL_ 82 ARS_SP_ErrStateGroup_3 128 "RESERVED" 64 "RESERVED" 32 "RESERVED" 1 "CHECKSUM_ERROR" 2 "ROLLING_COUNTER_ERROR" 4 "ARS_POS_NOT_CONFIG" 8 "ARS_POS_CONFIG_FAIL" 16 "ARS_POS_CONFIG_UPDATE" ;
VAL_ 82 ARS_SP_VisibilityState 0 "SELFTEST_NOT_STARTING" 1 "SELFTEST_IN_PROGRESS" 2 "SELFTEST_SUCCESSED" 3 "SELFTEST_FAILED" ;
VAL_ 256 ARS_RDI_TaskValidFlag 0 "INVALID" 1 "VALID" ;
VAL_ 256 ARS_RDI_ExtendedCycleFlag 0 "FALSE" 1 "TRUE" ;
VAL_ 257 ARS_RDI_DynProp_Clu_002 0 "STATIONARY" 1 "MOVING" 2 "AMBIGUOUS" 3 "RESERVED" ;
VAL_ 257 ARS_RDI_Quality_Clu_002 0 "INVALID" 1 "LOW" 2 "MID" 3 "HIGH" ;
VAL_ 257 ARS_RDI_DynProp_Clu_003 0 "STATIONARY" 1 "MOVING" 2 "AMBIGUOUS" 3 "RESERVED" ;
VAL_ 257 ARS_RDI_Quality_Clu_003 0 "INVALID" 1 "LOW" 2 "MID" 3 "HIGH" ;
VAL_ 257 ARS_RDI_DynProp_Clu_004 0 "STATIONARY" 1 "MOVING" 2 "AMBIGUOUS" 3 "RESERVED" ;
VAL_ 257 ARS_RDI_Quality_Clu_004 0 "INVALID" 1 "LOW" 2 "MID" 3 "HIGH" ;
VAL_ 257 ARS_RDI_DynProp_Clu_005 0 "STATIONARY" 1 "MOVING" 2 "AMBIGUOUS" 3 "RESERVED" ;
VAL_ 257 ARS_RDI_Quality_Clu_005 0 "INVALID" 1 "LOW" 2 "MID" 3 "HIGH" ;
VAL_ 257 ARS_RDI_DynProp_Clu_006 0 "STATIONARY" 1 "MOVING" 2 "AMBIGUOUS" 3 "RESERVED" ;
VAL_ 257 ARS_RDI_Quality_Clu_006 0 "INVALID" 1 "LOW" 2 "MID" 3 "HIGH" ;
VAL_ 257 ARS_RDI_DynProp_Clu_007 0 "STATIONARY" 1 "MOVING" 2 "AMBIGUOUS" 3 "RESERVED" ;
VAL_ 257 ARS_RDI_Quality_Clu_007 0 "INVALID" 1 "LOW" 2 "MID" 3 "HIGH" ;
VAL_ 257 ARS_RDI_DynProp_Clu_000 0 "STATIONARY" 1 "MOVING" 2 "AMBIGUOUS" 3 "RESERVED" ;
VAL_ 257 ARS_RDI_Quality_Clu_000 0 "INVALID" 1 "LOW" 2 "MID" 3 "HIGH" ;
VAL_ 257 ARS_RDI_DynProp_Clu_001 0 "STATIONARY" 1 "MOVING" 2 "AMBIGUOUS" 3 "RESERVED" ;
VAL_ 257 ARS_RDI_Quality_Clu_001 0 "INVALID" 1 "LOW" 2 "MID" 3 "HIGH" ;
VAL_ 258 ARS_RDI_DynProp_Clu_010 0 "STATIONARY" 1 "MOVING" 2 "AMBIGUOUS" 3 "RESERVED" ;
VAL_ 258 ARS_RDI_Quality_Clu_010 0 "INVALID" 1 "LOW" 2 "MID" 3 "HIGH" ;
VAL_ 258 ARS_RDI_DynProp_Clu_011 0 "STATIONARY" 1 "MOVING" 2 "AMBIGUOUS" 3 "RESERVED" ;
VAL_ 258 ARS_RDI_Quality_Clu_011 0 "INVALID" 1 "LOW" 2 "MID" 3 "HIGH" ;
VAL_ 258 ARS_RDI_DynProp_Clu_012 0 "STATIONARY" 1 "MOVING" 2 "AMBIGUOUS" 3 "RESERVED" ;
VAL_ 258 ARS_RDI_Quality_Clu_012 0 "INVALID" 1 "LOW" 2 "MID" 3 "HIGH" ;
VAL_ 258 ARS_RDI_DynProp_Clu_013 0 "STATIONARY" 1 "MOVING" 2 "AMBIGUOUS" 3 "RESERVED" ;
VAL_ 258 ARS_RDI_Quality_Clu_013 0 "INVALID" 1 "LOW" 2 "MID" 3 "HIGH" ;
VAL_ 258 ARS_RDI_DynProp_Clu_014 0 "STATIONARY" 1 "MOVING" 2 "AMBIGUOUS" 3 "RESERVED" ;
VAL_ 258 ARS_RDI_Quality_Clu_014 0 "INVALID" 1 "LOW" 2 "MID" 3 "HIGH" ;
VAL_ 258 ARS_RDI_DynProp_Clu_015 0 "STATIONARY" 1 "MOVING" 2 "AMBIGUOUS" 3 "RESERVED" ;
VAL_ 258 ARS_RDI_Quality_Clu_015 0 "INVALID" 1 "LOW" 2 "MID" 3 "HIGH" ;
VAL_ 258 ARS_RDI_DynProp_Clu_008 0 "STATIONARY" 1 "MOVING" 2 "AMBIGUOUS" 3 "RESERVED" ;
VAL_ 258 ARS_RDI_Quality_Clu_008 0 "INVALID" 1 "LOW" 2 "MID" 3 "HIGH" ;
VAL_ 258 ARS_RDI_DynProp_Clu_009 0 "STATIONARY" 1 "MOVING" 2 "AMBIGUOUS" 3 "RESERVED" ;
VAL_ 258 ARS_RDI_Quality_Clu_009 0 "INVALID" 1 "LOW" 2 "MID" 3 "HIGH" ;
VAL_ 259 ARS_RDI_DynProp_Clu_018 0 "STATIONARY" 1 "MOVING" 2 "AMBIGUOUS" 3 "RESERVED" ;
VAL_ 259 ARS_RDI_Quality_Clu_018 0 "INVALID" 1 "LOW" 2 "MID" 3 "HIGH" ;
VAL_ 259 ARS_RDI_DynProp_Clu_019 0 "STATIONARY" 1 "MOVING" 2 "AMBIGUOUS" 3 "RESERVED" ;
VAL_ 259 ARS_RDI_Quality_Clu_019 0 "INVALID" 1 "LOW" 2 "MID" 3 "HIGH" ;
VAL_ 259 ARS_RDI_DynProp_Clu_020 0 "STATIONARY" 1 "MOVING" 2 "AMBIGUOUS" 3 "RESERVED" ;
VAL_ 259 ARS_RDI_Quality_Clu_020 0 "INVALID" 1 "LOW" 2 "MID" 3 "HIGH" ;
VAL_ 259 ARS_RDI_DynProp_Clu_021 0 "STATIONARY" 1 "MOVING" 2 "AMBIGUOUS" 3 "RESERVED" ;
VAL_ 259 ARS_RDI_Quality_Clu_021 0 "INVALID" 1 "LOW" 2 "MID" 3 "HIGH" ;
VAL_ 259 ARS_RDI_DynProp_Clu_022 0 "STATIONARY" 1 "MOVING" 2 "AMBIGUOUS" 3 "RESERVED" ;
VAL_ 259 ARS_RDI_Quality_Clu_022 0 "INVALID" 1 "LOW" 2 "MID" 3 "HIGH" ;
VAL_ 259 ARS_RDI_DynProp_Clu_023 0 "STATIONARY" 1 "MOVING" 2 "AMBIGUOUS" 3 "RESERVED" ;
VAL_ 259 ARS_RDI_Quality_Clu_023 0 "INVALID" 1 "LOW" 2 "MID" 3 "HIGH" ;
VAL_ 259 ARS_RDI_DynProp_Clu_016 0 "STATIONARY" 1 "MOVING" 2 "AMBIGUOUS" 3 "RESERVED" ;
VAL_ 259 ARS_RDI_Quality_Clu_016 0 "INVALID" 1 "LOW" 2 "MID" 3 "HIGH" ;
VAL_ 259 ARS_RDI_DynProp_Clu_017 0 "STATIONARY" 1 "MOVING" 2 "AMBIGUOUS" 3 "RESERVED" ;
VAL_ 259 ARS_RDI_Quality_Clu_017 0 "INVALID" 1 "LOW" 2 "MID" 3 "HIGH" ;
VAL_ 260 ARS_RDI_DynProp_Clu_026 0 "STATIONARY" 1 "MOVING" 2 "AMBIGUOUS" 3 "RESERVED" ;
VAL_ 260 ARS_RDI_Quality_Clu_026 0 "INVALID" 1 "LOW" 2 "MID" 3 "HIGH" ;
VAL_ 260 ARS_RDI_DynProp_Clu_027 0 "STATIONARY" 1 "MOVING" 2 "AMBIGUOUS" 3 "RESERVED" ;
VAL_ 260 ARS_RDI_Quality_Clu_027 0 "INVALID" 1 "LOW" 2 "MID" 3 "HIGH" ;
VAL_ 260 ARS_RDI_DynProp_Clu_028 0 "STATIONARY" 1 "MOVING" 2 "AMBIGUOUS" 3 "RESERVED" ;
VAL_ 260 ARS_RDI_Quality_Clu_028 0 "INVALID" 1 "LOW" 2 "MID" 3 "HIGH" ;
VAL_ 260 ARS_RDI_DynProp_Clu_029 0 "STATIONARY" 1 "MOVING" 2 "AMBIGUOUS" 3 "RESERVED" ;
VAL_ 260 ARS_RDI_Quality_Clu_029 0 "INVALID" 1 "LOW" 2 "MID" 3 "HIGH" ;
VAL_ 260 ARS_RDI_DynProp_Clu_030 0 "STATIONARY" 1 "MOVING" 2 "AMBIGUOUS" 3 "RESERVED" ;
VAL_ 260 ARS_RDI_Quality_Clu_030 0 "INVALID" 1 "LOW" 2 "MID" 3 "HIGH" ;
VAL_ 260 ARS_RDI_DynProp_Clu_031 0 "STATIONARY" 1 "MOVING" 2 "AMBIGUOUS" 3 "RESERVED" ;
VAL_ 260 ARS_RDI_Quality_Clu_031 0 "INVALID" 1 "LOW" 2 "MID" 3 "HIGH" ;
VAL_ 260 ARS_RDI_DynProp_Clu_024 0 "STATIONARY" 1 "MOVING" 2 "AMBIGUOUS" 3 "RESERVED" ;
VAL_ 260 ARS_RDI_Quality_Clu_024 0 "INVALID" 1 "LOW" 2 "MID" 3 "HIGH" ;
VAL_ 260 ARS_RDI_DynProp_Clu_025 0 "STATIONARY" 1 "MOVING" 2 "AMBIGUOUS" 3 "RESERVED" ;
VAL_ 260 ARS_RDI_Quality_Clu_025 0 "INVALID" 1 "LOW" 2 "MID" 3 "HIGH" ;
VAL_ 261 ARS_RDI_DynProp_Clu_034 0 "STATIONARY" 1 "MOVING" 2 "AMBIGUOUS" 3 "RESERVED" ;
VAL_ 261 ARS_RDI_Quality_Clu_034 0 "INVALID" 1 "LOW" 2 "MID" 3 "HIGH" ;
VAL_ 261 ARS_RDI_DynProp_Clu_035 0 "STATIONARY" 1 "MOVING" 2 "AMBIGUOUS" 3 "RESERVED" ;
VAL_ 261 ARS_RDI_Quality_Clu_035 0 "INVALID" 1 "LOW" 2 "MID" 3 "HIGH" ;
VAL_ 261 ARS_RDI_DynProp_Clu_036 0 "STATIONARY" 1 "MOVING" 2 "AMBIGUOUS" 3 "RESERVED" ;
VAL_ 261 ARS_RDI_Quality_Clu_036 0 "INVALID" 1 "LOW" 2 "MID" 3 "HIGH" ;
VAL_ 261 ARS_RDI_DynProp_Clu_037 0 "STATIONARY" 1 "MOVING" 2 "AMBIGUOUS" 3 "RESERVED" ;
VAL_ 261 ARS_RDI_Quality_Clu_037 0 "INVALID" 1 "LOW" 2 "MID" 3 "HIGH" ;
VAL_ 261 ARS_RDI_DynProp_Clu_038 0 "STATIONARY" 1 "MOVING" 2 "AMBIGUOUS" 3 "RESERVED" ;
VAL_ 261 ARS_RDI_Quality_Clu_038 0 "INVALID" 1 "LOW" 2 "MID" 3 "HIGH" ;
VAL_ 261 ARS_RDI_DynProp_Clu_039 0 "STATIONARY" 1 "MOVING" 2 "AMBIGUOUS" 3 "RESERVED" ;
VAL_ 261 ARS_RDI_Quality_Clu_039 0 "INVALID" 1 "LOW" 2 "MID" 3 "HIGH" ;
VAL_ 261 ARS_RDI_DynProp_Clu_032 0 "STATIONARY" 1 "MOVING" 2 "AMBIGUOUS" 3 "RESERVED" ;
VAL_ 261 ARS_RDI_Quality_Clu_032 0 "INVALID" 1 "LOW" 2 "MID" 3 "HIGH" ;
VAL_ 261 ARS_RDI_DynProp_Clu_033 0 "STATIONARY" 1 "MOVING" 2 "AMBIGUOUS" 3 "RESERVED" ;
VAL_ 261 ARS_RDI_Quality_Clu_033 0 "INVALID" 1 "LOW" 2 "MID" 3 "HIGH" ;
VAL_ 262 ARS_RDI_DynProp_Clu_042 0 "STATIONARY" 1 "MOVING" 2 "AMBIGUOUS" 3 "RESERVED" ;
VAL_ 262 ARS_RDI_Quality_Clu_042 0 "INVALID" 1 "LOW" 2 "MID" 3 "HIGH" ;
VAL_ 262 ARS_RDI_DynProp_Clu_043 0 "STATIONARY" 1 "MOVING" 2 "AMBIGUOUS" 3 "RESERVED" ;
VAL_ 262 ARS_RDI_Quality_Clu_043 0 "INVALID" 1 "LOW" 2 "MID" 3 "HIGH" ;
VAL_ 262 ARS_RDI_DynProp_Clu_044 0 "STATIONARY" 1 "MOVING" 2 "AMBIGUOUS" 3 "RESERVED" ;
VAL_ 262 ARS_RDI_Quality_Clu_044 0 "INVALID" 1 "LOW" 2 "MID" 3 "HIGH" ;
VAL_ 262 ARS_RDI_DynProp_Clu_045 0 "STATIONARY" 1 "MOVING" 2 "AMBIGUOUS" 3 "RESERVED" ;
VAL_ 262 ARS_RDI_Quality_Clu_045 0 "INVALID" 1 "LOW" 2 "MID" 3 "HIGH" ;
VAL_ 262 ARS_RDI_DynProp_Clu_046 0 "STATIONARY" 1 "MOVING" 2 "AMBIGUOUS" 3 "RESERVED" ;
VAL_ 262 ARS_RDI_Quality_Clu_046 0 "INVALID" 1 "LOW" 2 "MID" 3 "HIGH" ;
VAL_ 262 ARS_RDI_DynProp_Clu_047 0 "STATIONARY" 1 "MOVING" 2 "AMBIGUOUS" 3 "RESERVED" ;
VAL_ 262 ARS_RDI_Quality_Clu_047 0 "INVALID" 1 "LOW" 2 "MID" 3 "HIGH" ;
VAL_ 262 ARS_RDI_DynProp_Clu_040 0 "STATIONARY" 1 "MOVING" 2 "AMBIGUOUS" 3 "RESERVED" ;
VAL_ 262 ARS_RDI_Quality_Clu_040 0 "INVALID" 1 "LOW" 2 "MID" 3 "HIGH" ;
VAL_ 262 ARS_RDI_DynProp_Clu_041 0 "STATIONARY" 1 "MOVING" 2 "AMBIGUOUS" 3 "RESERVED" ;
VAL_ 262 ARS_RDI_Quality_Clu_041 0 "INVALID" 1 "LOW" 2 "MID" 3 "HIGH" ;
VAL_ 263 ARS_RDI_DynProp_Clu_050 0 "STATIONARY" 1 "MOVING" 2 "AMBIGUOUS" 3 "RESERVED" ;
VAL_ 263 ARS_RDI_Quality_Clu_050 0 "INVALID" 1 "LOW" 2 "MID" 3 "HIGH" ;
VAL_ 263 ARS_RDI_DynProp_Clu_051 0 "STATIONARY" 1 "MOVING" 2 "AMBIGUOUS" 3 "RESERVED" ;
VAL_ 263 ARS_RDI_Quality_Clu_051 0 "INVALID" 1 "LOW" 2 "MID" 3 "HIGH" ;
VAL_ 263 ARS_RDI_DynProp_Clu_052 0 "STATIONARY" 1 "MOVING" 2 "AMBIGUOUS" 3 "RESERVED" ;
VAL_ 263 ARS_RDI_Quality_Clu_052 0 "INVALID" 1 "LOW" 2 "MID" 3 "HIGH" ;
VAL_ 263 ARS_RDI_DynProp_Clu_053 0 "STATIONARY" 1 "MOVING" 2 "AMBIGUOUS" 3 "RESERVED" ;
VAL_ 263 ARS_RDI_Quality_Clu_053 0 "INVALID" 1 "LOW" 2 "MID" 3 "HIGH" ;
VAL_ 263 ARS_RDI_DynProp_Clu_054 0 "STATIONARY" 1 "MOVING" 2 "AMBIGUOUS" 3 "RESERVED" ;
VAL_ 263 ARS_RDI_Quality_Clu_054 0 "INVALID" 1 "LOW" 2 "MID" 3 "HIGH" ;
VAL_ 263 ARS_RDI_DynProp_Clu_055 0 "STATIONARY" 1 "MOVING" 2 "AMBIGUOUS" 3 "RESERVED" ;
VAL_ 263 ARS_RDI_Quality_Clu_055 0 "INVALID" 1 "LOW" 2 "MID" 3 "HIGH" ;
VAL_ 263 ARS_RDI_DynProp_Clu_048 0 "STATIONARY" 1 "MOVING" 2 "AMBIGUOUS" 3 "RESERVED" ;
VAL_ 263 ARS_RDI_Quality_Clu_048 0 "INVALID" 1 "LOW" 2 "MID" 3 "HIGH" ;
VAL_ 263 ARS_RDI_DynProp_Clu_049 0 "STATIONARY" 1 "MOVING" 2 "AMBIGUOUS" 3 "RESERVED" ;
VAL_ 263 ARS_RDI_Quality_Clu_049 0 "INVALID" 1 "LOW" 2 "MID" 3 "HIGH" ;
VAL_ 264 ARS_RDI_DynProp_Clu_058 0 "STATIONARY" 1 "MOVING" 2 "AMBIGUOUS" 3 "RESERVED" ;
VAL_ 264 ARS_RDI_Quality_Clu_058 0 "INVALID" 1 "LOW" 2 "MID" 3 "HIGH" ;
VAL_ 264 ARS_RDI_DynProp_Clu_059 0 "STATIONARY" 1 "MOVING" 2 "AMBIGUOUS" 3 "RESERVED" ;
VAL_ 264 ARS_RDI_Quality_Clu_059 0 "INVALID" 1 "LOW" 2 "MID" 3 "HIGH" ;
VAL_ 264 ARS_RDI_DynProp_Clu_060 0 "STATIONARY" 1 "MOVING" 2 "AMBIGUOUS" 3 "RESERVED" ;
VAL_ 264 ARS_RDI_Quality_Clu_060 0 "INVALID" 1 "LOW" 2 "MID" 3 "HIGH" ;
VAL_ 264 ARS_RDI_DynProp_Clu_061 0 "STATIONARY" 1 "MOVING" 2 "AMBIGUOUS" 3 "RESERVED" ;
VAL_ 264 ARS_RDI_Quality_Clu_061 0 "INVALID" 1 "LOW" 2 "MID" 3 "HIGH" ;
VAL_ 264 ARS_RDI_DynProp_Clu_062 0 "STATIONARY" 1 "MOVING" 2 "AMBIGUOUS" 3 "RESERVED" ;
VAL_ 264 ARS_RDI_Quality_Clu_062 0 "INVALID" 1 "LOW" 2 "MID" 3 "HIGH" ;
VAL_ 264 ARS_RDI_DynProp_Clu_063 0 "STATIONARY" 1 "MOVING" 2 "AMBIGUOUS" 3 "RESERVED" ;
VAL_ 264 ARS_RDI_Quality_Clu_063 0 "INVALID" 1 "LOW" 2 "MID" 3 "HIGH" ;
VAL_ 264 ARS_RDI_DynProp_Clu_056 0 "STATIONARY" 1 "MOVING" 2 "AMBIGUOUS" 3 "RESERVED" ;
VAL_ 264 ARS_RDI_Quality_Clu_056 0 "INVALID" 1 "LOW" 2 "MID" 3 "HIGH" ;
VAL_ 264 ARS_RDI_DynProp_Clu_057 0 "STATIONARY" 1 "MOVING" 2 "AMBIGUOUS" 3 "RESERVED" ;
VAL_ 264 ARS_RDI_Quality_Clu_057 0 "INVALID" 1 "LOW" 2 "MID" 3 "HIGH" ;
VAL_ 265 ARS_RDI_DynProp_Clu_066 0 "STATIONARY" 1 "MOVING" 2 "AMBIGUOUS" 3 "RESERVED" ;
VAL_ 265 ARS_RDI_Quality_Clu_066 0 "INVALID" 1 "LOW" 2 "MID" 3 "HIGH" ;
VAL_ 265 ARS_RDI_DynProp_Clu_067 0 "STATIONARY" 1 "MOVING" 2 "AMBIGUOUS" 3 "RESERVED" ;
VAL_ 265 ARS_RDI_Quality_Clu_067 0 "INVALID" 1 "LOW" 2 "MID" 3 "HIGH" ;
VAL_ 265 ARS_RDI_DynProp_Clu_068 0 "STATIONARY" 1 "MOVING" 2 "AMBIGUOUS" 3 "RESERVED" ;
VAL_ 265 ARS_RDI_Quality_Clu_068 0 "INVALID" 1 "LOW" 2 "MID" 3 "HIGH" ;
VAL_ 265 ARS_RDI_DynProp_Clu_069 0 "STATIONARY" 1 "MOVING" 2 "AMBIGUOUS" 3 "RESERVED" ;
VAL_ 265 ARS_RDI_Quality_Clu_069 0 "INVALID" 1 "LOW" 2 "MID" 3 "HIGH" ;
VAL_ 265 ARS_RDI_DynProp_Clu_070 0 "STATIONARY" 1 "MOVING" 2 "AMBIGUOUS" 3 "RESERVED" ;
VAL_ 265 ARS_RDI_Quality_Clu_070 0 "INVALID" 1 "LOW" 2 "MID" 3 "HIGH" ;
VAL_ 265 ARS_RDI_DynProp_Clu_071 0 "STATIONARY" 1 "MOVING" 2 "AMBIGUOUS" 3 "RESERVED" ;
VAL_ 265 ARS_RDI_Quality_Clu_071 0 "INVALID" 1 "LOW" 2 "MID" 3 "HIGH" ;
VAL_ 265 ARS_RDI_DynProp_Clu_064 0 "STATIONARY" 1 "MOVING" 2 "AMBIGUOUS" 3 "RESERVED" ;
VAL_ 265 ARS_RDI_Quality_Clu_064 0 "INVALID" 1 "LOW" 2 "MID" 3 "HIGH" ;
VAL_ 265 ARS_RDI_DynProp_Clu_065 0 "STATIONARY" 1 "MOVING" 2 "AMBIGUOUS" 3 "RESERVED" ;
VAL_ 265 ARS_RDI_Quality_Clu_065 0 "INVALID" 1 "LOW" 2 "MID" 3 "HIGH" ;
VAL_ 266 ARS_RDI_DynProp_Clu_074 0 "STATIONARY" 1 "MOVING" 2 "AMBIGUOUS" 3 "RESERVED" ;
VAL_ 266 ARS_RDI_Quality_Clu_074 0 "INVALID" 1 "LOW" 2 "MID" 3 "HIGH" ;
VAL_ 266 ARS_RDI_DynProp_Clu_075 0 "STATIONARY" 1 "MOVING" 2 "AMBIGUOUS" 3 "RESERVED" ;
VAL_ 266 ARS_RDI_Quality_Clu_075 0 "INVALID" 1 "LOW" 2 "MID" 3 "HIGH" ;
VAL_ 266 ARS_RDI_DynProp_Clu_076 0 "STATIONARY" 1 "MOVING" 2 "AMBIGUOUS" 3 "RESERVED" ;
VAL_ 266 ARS_RDI_Quality_Clu_076 0 "INVALID" 1 "LOW" 2 "MID" 3 "HIGH" ;
VAL_ 266 ARS_RDI_DynProp_Clu_077 0 "STATIONARY" 1 "MOVING" 2 "AMBIGUOUS" 3 "RESERVED" ;
VAL_ 266 ARS_RDI_Quality_Clu_077 0 "INVALID" 1 "LOW" 2 "MID" 3 "HIGH" ;
VAL_ 266 ARS_RDI_DynProp_Clu_078 0 "STATIONARY" 1 "MOVING" 2 "AMBIGUOUS" 3 "RESERVED" ;
VAL_ 266 ARS_RDI_Quality_Clu_078 0 "INVALID" 1 "LOW" 2 "MID" 3 "HIGH" ;
VAL_ 266 ARS_RDI_DynProp_Clu_079 0 "STATIONARY" 1 "MOVING" 2 "AMBIGUOUS" 3 "RESERVED" ;
VAL_ 266 ARS_RDI_Quality_Clu_079 0 "INVALID" 1 "LOW" 2 "MID" 3 "HIGH" ;
VAL_ 266 ARS_RDI_DynProp_Clu_072 0 "STATIONARY" 1 "MOVING" 2 "AMBIGUOUS" 3 "RESERVED" ;
VAL_ 266 ARS_RDI_Quality_Clu_072 0 "INVALID" 1 "LOW" 2 "MID" 3 "HIGH" ;
VAL_ 266 ARS_RDI_DynProp_Clu_073 0 "STATIONARY" 1 "MOVING" 2 "AMBIGUOUS" 3 "RESERVED" ;
VAL_ 266 ARS_RDI_Quality_Clu_073 0 "INVALID" 1 "LOW" 2 "MID" 3 "HIGH" ;
VAL_ 267 ARS_RDI_DynProp_Clu_082 0 "STATIONARY" 1 "MOVING" 2 "AMBIGUOUS" 3 "RESERVED" ;
VAL_ 267 ARS_RDI_Quality_Clu_082 0 "INVALID" 1 "LOW" 2 "MID" 3 "HIGH" ;
VAL_ 267 ARS_RDI_DynProp_Clu_083 0 "STATIONARY" 1 "MOVING" 2 "AMBIGUOUS" 3 "RESERVED" ;
VAL_ 267 ARS_RDI_Quality_Clu_083 0 "INVALID" 1 "LOW" 2 "MID" 3 "HIGH" ;
VAL_ 267 ARS_RDI_DynProp_Clu_084 0 "STATIONARY" 1 "MOVING" 2 "AMBIGUOUS" 3 "RESERVED" ;
VAL_ 267 ARS_RDI_Quality_Clu_084 0 "INVALID" 1 "LOW" 2 "MID" 3 "HIGH" ;
VAL_ 267 ARS_RDI_DynProp_Clu_085 0 "STATIONARY" 1 "MOVING" 2 "AMBIGUOUS" 3 "RESERVED" ;
VAL_ 267 ARS_RDI_Quality_Clu_085 0 "INVALID" 1 "LOW" 2 "MID" 3 "HIGH" ;
VAL_ 267 ARS_RDI_DynProp_Clu_086 0 "STATIONARY" 1 "MOVING" 2 "AMBIGUOUS" 3 "RESERVED" ;
VAL_ 267 ARS_RDI_Quality_Clu_086 0 "INVALID" 1 "LOW" 2 "MID" 3 "HIGH" ;
VAL_ 267 ARS_RDI_DynProp_Clu_087 0 "STATIONARY" 1 "MOVING" 2 "AMBIGUOUS" 3 "RESERVED" ;
VAL_ 267 ARS_RDI_Quality_Clu_087 0 "INVALID" 1 "LOW" 2 "MID" 3 "HIGH" ;
VAL_ 267 ARS_RDI_DynProp_Clu_080 0 "STATIONARY" 1 "MOVING" 2 "AMBIGUOUS" 3 "RESERVED" ;
VAL_ 267 ARS_RDI_Quality_Clu_080 0 "INVALID" 1 "LOW" 2 "MID" 3 "HIGH" ;
VAL_ 267 ARS_RDI_DynProp_Clu_081 0 "STATIONARY" 1 "MOVING" 2 "AMBIGUOUS" 3 "RESERVED" ;
VAL_ 267 ARS_RDI_Quality_Clu_081 0 "INVALID" 1 "LOW" 2 "MID" 3 "HIGH" ;
VAL_ 268 ARS_RDI_DynProp_Clu_090 0 "STATIONARY" 1 "MOVING" 2 "AMBIGUOUS" 3 "RESERVED" ;
VAL_ 268 ARS_RDI_Quality_Clu_090 0 "INVALID" 1 "LOW" 2 "MID" 3 "HIGH" ;
VAL_ 268 ARS_RDI_DynProp_Clu_091 0 "STATIONARY" 1 "MOVING" 2 "AMBIGUOUS" 3 "RESERVED" ;
VAL_ 268 ARS_RDI_Quality_Clu_091 0 "INVALID" 1 "LOW" 2 "MID" 3 "HIGH" ;
VAL_ 268 ARS_RDI_DynProp_Clu_092 0 "STATIONARY" 1 "MOVING" 2 "AMBIGUOUS" 3 "RESERVED" ;
VAL_ 268 ARS_RDI_Quality_Clu_092 0 "INVALID" 1 "LOW" 2 "MID" 3 "HIGH" ;
VAL_ 268 ARS_RDI_DynProp_Clu_093 0 "STATIONARY" 1 "MOVING" 2 "AMBIGUOUS" 3 "RESERVED" ;
VAL_ 268 ARS_RDI_Quality_Clu_093 0 "INVALID" 1 "LOW" 2 "MID" 3 "HIGH" ;
VAL_ 268 ARS_RDI_DynProp_Clu_094 0 "STATIONARY" 1 "MOVING" 2 "AMBIGUOUS" 3 "RESERVED" ;
VAL_ 268 ARS_RDI_Quality_Clu_094 0 "INVALID" 1 "LOW" 2 "MID" 3 "HIGH" ;
VAL_ 268 ARS_RDI_DynProp_Clu_095 0 "STATIONARY" 1 "MOVING" 2 "AMBIGUOUS" 3 "RESERVED" ;
VAL_ 268 ARS_RDI_Quality_Clu_095 0 "INVALID" 1 "LOW" 2 "MID" 3 "HIGH" ;
VAL_ 268 ARS_RDI_DynProp_Clu_088 0 "STATIONARY" 1 "MOVING" 2 "AMBIGUOUS" 3 "RESERVED" ;
VAL_ 268 ARS_RDI_Quality_Clu_088 0 "INVALID" 1 "LOW" 2 "MID" 3 "HIGH" ;
VAL_ 268 ARS_RDI_DynProp_Clu_089 0 "STATIONARY" 1 "MOVING" 2 "AMBIGUOUS" 3 "RESERVED" ;
VAL_ 268 ARS_RDI_Quality_Clu_089 0 "INVALID" 1 "LOW" 2 "MID" 3 "HIGH" ;
VAL_ 269 ARS_RDI_DynProp_Clu_098 0 "STATIONARY" 1 "MOVING" 2 "AMBIGUOUS" 3 "RESERVED" ;
VAL_ 269 ARS_RDI_Quality_Clu_098 0 "INVALID" 1 "LOW" 2 "MID" 3 "HIGH" ;
VAL_ 269 ARS_RDI_DynProp_Clu_099 0 "STATIONARY" 1 "MOVING" 2 "AMBIGUOUS" 3 "RESERVED" ;
VAL_ 269 ARS_RDI_Quality_Clu_099 0 "INVALID" 1 "LOW" 2 "MID" 3 "HIGH" ;
VAL_ 269 ARS_RDI_DynProp_Clu_100 0 "STATIONARY" 1 "MOVING" 2 "AMBIGUOUS" 3 "RESERVED" ;
VAL_ 269 ARS_RDI_Quality_Clu_100 0 "INVALID" 1 "LOW" 2 "MID" 3 "HIGH" ;
VAL_ 269 ARS_RDI_DynProp_Clu_101 0 "STATIONARY" 1 "MOVING" 2 "AMBIGUOUS" 3 "RESERVED" ;
VAL_ 269 ARS_RDI_Quality_Clu_101 0 "INVALID" 1 "LOW" 2 "MID" 3 "HIGH" ;
VAL_ 269 ARS_RDI_DynProp_Clu_102 0 "STATIONARY" 1 "MOVING" 2 "AMBIGUOUS" 3 "RESERVED" ;
VAL_ 269 ARS_RDI_Quality_Clu_102 0 "INVALID" 1 "LOW" 2 "MID" 3 "HIGH" ;
VAL_ 269 ARS_RDI_DynProp_Clu_103 0 "STATIONARY" 1 "MOVING" 2 "AMBIGUOUS" 3 "RESERVED" ;
VAL_ 269 ARS_RDI_Quality_Clu_103 0 "INVALID" 1 "LOW" 2 "MID" 3 "HIGH" ;
VAL_ 269 ARS_RDI_DynProp_Clu_096 0 "STATIONARY" 1 "MOVING" 2 "AMBIGUOUS" 3 "RESERVED" ;
VAL_ 269 ARS_RDI_Quality_Clu_096 0 "INVALID" 1 "LOW" 2 "MID" 3 "HIGH" ;
VAL_ 269 ARS_RDI_DynProp_Clu_097 0 "STATIONARY" 1 "MOVING" 2 "AMBIGUOUS" 3 "RESERVED" ;
VAL_ 269 ARS_RDI_Quality_Clu_097 0 "INVALID" 1 "LOW" 2 "MID" 3 "HIGH" ;
VAL_ 270 ARS_RDI_DynProp_Clu_106 0 "STATIONARY" 1 "MOVING" 2 "AMBIGUOUS" 3 "RESERVED" ;
VAL_ 270 ARS_RDI_Quality_Clu_106 0 "INVALID" 1 "LOW" 2 "MID" 3 "HIGH" ;
VAL_ 270 ARS_RDI_DynProp_Clu_107 0 "STATIONARY" 1 "MOVING" 2 "AMBIGUOUS" 3 "RESERVED" ;
VAL_ 270 ARS_RDI_Quality_Clu_107 0 "INVALID" 1 "LOW" 2 "MID" 3 "HIGH" ;
VAL_ 270 ARS_RDI_DynProp_Clu_108 0 "STATIONARY" 1 "MOVING" 2 "AMBIGUOUS" 3 "RESERVED" ;
VAL_ 270 ARS_RDI_Quality_Clu_108 0 "INVALID" 1 "LOW" 2 "MID" 3 "HIGH" ;
VAL_ 270 ARS_RDI_DynProp_Clu_109 0 "STATIONARY" 1 "MOVING" 2 "AMBIGUOUS" 3 "RESERVED" ;
VAL_ 270 ARS_RDI_Quality_Clu_109 0 "INVALID" 1 "LOW" 2 "MID" 3 "HIGH" ;
VAL_ 270 ARS_RDI_DynProp_Clu_110 0 "STATIONARY" 1 "MOVING" 2 "AMBIGUOUS" 3 "RESERVED" ;
VAL_ 270 ARS_RDI_Quality_Clu_110 0 "INVALID" 1 "LOW" 2 "MID" 3 "HIGH" ;
VAL_ 270 ARS_RDI_DynProp_Clu_111 0 "STATIONARY" 1 "MOVING" 2 "AMBIGUOUS" 3 "RESERVED" ;
VAL_ 270 ARS_RDI_Quality_Clu_111 0 "INVALID" 1 "LOW" 2 "MID" 3 "HIGH" ;
VAL_ 270 ARS_RDI_DynProp_Clu_104 0 "STATIONARY" 1 "MOVING" 2 "AMBIGUOUS" 3 "RESERVED" ;
VAL_ 270 ARS_RDI_Quality_Clu_104 0 "INVALID" 1 "LOW" 2 "MID" 3 "HIGH" ;
VAL_ 270 ARS_RDI_DynProp_Clu_105 0 "STATIONARY" 1 "MOVING" 2 "AMBIGUOUS" 3 "RESERVED" ;
VAL_ 270 ARS_RDI_Quality_Clu_105 0 "INVALID" 1 "LOW" 2 "MID" 3 "HIGH" ;
VAL_ 271 ARS_RDI_DynProp_Clu_114 0 "STATIONARY" 1 "MOVING" 2 "AMBIGUOUS" 3 "RESERVED" ;
VAL_ 271 ARS_RDI_Quality_Clu_114 0 "INVALID" 1 "LOW" 2 "MID" 3 "HIGH" ;
VAL_ 271 ARS_RDI_DynProp_Clu_115 0 "STATIONARY" 1 "MOVING" 2 "AMBIGUOUS" 3 "RESERVED" ;
VAL_ 271 ARS_RDI_Quality_Clu_115 0 "INVALID" 1 "LOW" 2 "MID" 3 "HIGH" ;
VAL_ 271 ARS_RDI_DynProp_Clu_116 0 "STATIONARY" 1 "MOVING" 2 "AMBIGUOUS" 3 "RESERVED" ;
VAL_ 271 ARS_RDI_Quality_Clu_116 0 "INVALID" 1 "LOW" 2 "MID" 3 "HIGH" ;
VAL_ 271 ARS_RDI_DynProp_Clu_117 0 "STATIONARY" 1 "MOVING" 2 "AMBIGUOUS" 3 "RESERVED" ;
VAL_ 271 ARS_RDI_Quality_Clu_117 0 "INVALID" 1 "LOW" 2 "MID" 3 "HIGH" ;
VAL_ 271 ARS_RDI_DynProp_Clu_118 0 "STATIONARY" 1 "MOVING" 2 "AMBIGUOUS" 3 "RESERVED" ;
VAL_ 271 ARS_RDI_Quality_Clu_118 0 "INVALID" 1 "LOW" 2 "MID" 3 "HIGH" ;
VAL_ 271 ARS_RDI_DynProp_Clu_119 0 "STATIONARY" 1 "MOVING" 2 "AMBIGUOUS" 3 "RESERVED" ;
VAL_ 271 ARS_RDI_Quality_Clu_119 0 "INVALID" 1 "LOW" 2 "MID" 3 "HIGH" ;
VAL_ 271 ARS_RDI_DynProp_Clu_112 0 "STATIONARY" 1 "MOVING" 2 "AMBIGUOUS" 3 "RESERVED" ;
VAL_ 271 ARS_RDI_Quality_Clu_112 0 "INVALID" 1 "LOW" 2 "MID" 3 "HIGH" ;
VAL_ 271 ARS_RDI_DynProp_Clu_113 0 "STATIONARY" 1 "MOVING" 2 "AMBIGUOUS" 3 "RESERVED" ;
VAL_ 271 ARS_RDI_Quality_Clu_113 0 "INVALID" 1 "LOW" 2 "MID" 3 "HIGH" ;
VAL_ 272 ARS_RDI_DynProp_Clu_122 0 "STATIONARY" 1 "MOVING" 2 "AMBIGUOUS" 3 "RESERVED" ;
VAL_ 272 ARS_RDI_Quality_Clu_122 0 "INVALID" 1 "LOW" 2 "MID" 3 "HIGH" ;
VAL_ 272 ARS_RDI_DynProp_Clu_123 0 "STATIONARY" 1 "MOVING" 2 "AMBIGUOUS" 3 "RESERVED" ;
VAL_ 272 ARS_RDI_Quality_Clu_123 0 "INVALID" 1 "LOW" 2 "MID" 3 "HIGH" ;
VAL_ 272 ARS_RDI_DynProp_Clu_124 0 "STATIONARY" 1 "MOVING" 2 "AMBIGUOUS" 3 "RESERVED" ;
VAL_ 272 ARS_RDI_Quality_Clu_124 0 "INVALID" 1 "LOW" 2 "MID" 3 "HIGH" ;
VAL_ 272 ARS_RDI_DynProp_Clu_125 0 "STATIONARY" 1 "MOVING" 2 "AMBIGUOUS" 3 "RESERVED" ;
VAL_ 272 ARS_RDI_Quality_Clu_125 0 "INVALID" 1 "LOW" 2 "MID" 3 "HIGH" ;
VAL_ 272 ARS_RDI_DynProp_Clu_126 0 "STATIONARY" 1 "MOVING" 2 "AMBIGUOUS" 3 "RESERVED" ;
VAL_ 272 ARS_RDI_Quality_Clu_126 0 "INVALID" 1 "LOW" 2 "MID" 3 "HIGH" ;
VAL_ 272 ARS_RDI_DynProp_Clu_127 0 "STATIONARY" 1 "MOVING" 2 "AMBIGUOUS" 3 "RESERVED" ;
VAL_ 272 ARS_RDI_Quality_Clu_127 0 "INVALID" 1 "LOW" 2 "MID" 3 "HIGH" ;
VAL_ 272 ARS_RDI_DynProp_Clu_120 0 "STATIONARY" 1 "MOVING" 2 "AMBIGUOUS" 3 "RESERVED" ;
VAL_ 272 ARS_RDI_Quality_Clu_120 0 "INVALID" 1 "LOW" 2 "MID" 3 "HIGH" ;
VAL_ 272 ARS_RDI_DynProp_Clu_121 0 "STATIONARY" 1 "MOVING" 2 "AMBIGUOUS" 3 "RESERVED" ;
VAL_ 272 ARS_RDI_Quality_Clu_121 0 "INVALID" 1 "LOW" 2 "MID" 3 "HIGH" ;
SIG_GROUP_ 33 Signal_Group_ADCU_SYNC_FUP 1 : ADCU_TSYNC_Type ADCU_TSYNC_Fup_CRC ADCU_TSYNC_Sync_CRC ADCU_TSYNC_Fup_TimeDomain ADCU_TSYNC_Sync_TimeDomain ADCU_TSYNC_Fup_SeqCounter ADCU_TSYNC_Sync_SeqCounter ADCU_TSYNC_Fup_Reserved ADCU_TSYNC_Sync_UserByte0 ADCU_TSYNC_Fup_SGW ADCU_TSYNC_Fup_OVS ADCU_TSYNC_Fup_SyncTimeNSec ADCU_TSYNC_Sync_TimeSec;
SIG_GROUP_ 48 Signal_Group_ARS_TIME_SYNC 1 : ARS_TSYNC_TimeStampGlobSec ARS_TSYNC_CRC16_Checksum ARS_TSYNC_TimeStampGlobNSec ARS_TSYNC_MaxTimeLeap ARS_TSYNC_LastTimeLeap ARS_TSYNC_MsgCounter;
SIG_GROUP_ 64 Signal_Group_GW_ACU 1 : GW_ACU_LongAccel GW_ACU_LongAccel_ValidFlag GW_ACU_LateralAccel GW_ACU_YawRate GW_ACU_LateralAccel_ValidFlag GW_ACU_YawRate_ValidFlag GW_ACU_MsgCounter GW_ACU_CRC16_Checksum;
SIG_GROUP_ 65 Signal_Group_GW_ESC 1 : GW_ESC_WheelSpeed_FL GW_ESC_MsgCounter GW_ESC_CRC16_Checksum GW_ESC_WheelSpeed_FL_VldFlg GW_ESC_WheelDirection_FL GW_ESC_WheelSpeed_FR GW_ESC_WheelSpeed_FR_VldFlg GW_ESC_WheelDirection_FR GW_ESC_WheelSpeed_RL GW_ESC_WheelSpeed_RL_VldFlg GW_ESC_WheelDirection_RL GW_ESC_WheelSpeed_RR GW_ESC_WheelSpeed_RR_VldFlg GW_ESC_WheelDirection_RR GW_ESC_WheelDirection_FL_VldFlg GW_ESC_WheelDirection_FR_VldFlg GW_ESC_WheelDirection_RL_VldFlg GW_ESC_WheelDirection_RR_VldFlg GW_ESC_ABS_ActiveFlag GW_ESC_ABS_ValidFlag GW_ESC_TCS_ActiveFlag GW_ESC_TCS_ValidFlag GW_ESC_VehicleSpeed GW_ESC_VehicleSpeed_ValidFlag GW_ESC_EPB_ActiveFlag GW_ESC_EPB_ValidFlag;
SIG_GROUP_ 66 Signal_Group_GW_SAS 1 : GW_SAS_SteeringWheelAngle GW_SAS_SteeringWheelAngle_VldFlg GW_SAS_MsgCounter GW_SAS_CRC16_Checksum;
SIG_GROUP_ 67 Signal_Group_GW_TM 1 : GW_TM_PowerModeStatus GW_TM_GearPosition GW_TM_GearPosition_ValidFlag GW_TM_MsgCounter GW_TM_CRC16_Checksum;
SIG_GROUP_ 70 Signal_Group_GW_SENSOR_CONFIG 1 : GW_SENCFG_ID GW_SENCFG_MsgCounter GW_SENCFG_CRC16_Checksum;
SIG_GROUP_ 80 Signal_Group_ARS_CONFIG_STATE 1 : ARS_CFG_Mode ARS_CFG_VParAxisLdDistr_CFGflag ARS_CFG_VParCntrOGrvHght_CFGflag ARS_CFG_VParCntrOGrvHght ARS_CFG_VParVehWeight_CFGflag ARS_CFG_VParTrkWdthRear_CFGflag ARS_CFG_VParAxisLdDistr ARS_CFG_VParTrkWdthFrnt_CFGflag ARS_CFG_VParLatPos ARS_CFG_VParWheelBase_CFGflag ARS_CFG_VParStrRatio_CFGflag ARS_CFG_VParLongPos ARS_CFG_TimeSyncEnableFlag ARS_CFG_VParVertPos ARS_CFG_VParStrRatio ARS_CFG_VParLatPos_CFGflag ARS_CFG_SensorID ARS_CFG_SensorID_CFGflag ARS_CFG_VParLngPos2CoG ARS_CFG_VParYawAngle ARS_CFG_VParLongPos_CFGflag ARS_CFG_VParVertPos_CFGflag ARS_CFG_VParLngPos2CoG_CFGflag ARS_CFG_VParSnsrOrnt ARS_CFG_VParSnsrOrnt_CFGflag ARS_CFG_VParYawAngle_CFGflag ARS_CFG_VParCoverDamping_CFGflag ARS_CFG_VParCoverDamping ARS_CFG_MsgCounter ARS_CFG_CRC16_Checksum ARS_CFG_VParWheelBase ARS_CFG_VParTrkWdthFrnt ARS_CFG_VParTrkWdthRear ARS_CFG_VParVehWeight;
SIG_GROUP_ 82 Signal_Group_ARS_SYS_PERFORM 1 : ARS_SP_OperationMode ARS_SP_CalibrationState ARS_SP_TunnelFlag ARS_SP_AzimuthCorrection ARS_SP_MsgCounter ARS_SP_CRC16_Checksum ARS_SP_ElevationCorrection ARS_SP_ErrStateGroup_1 ARS_SP_ErrStateGroup_2 ARS_SP_ErrStateGroup_3 ARS_SP_ErrStateGroup_4 ARS_SP_VisibilityRange ARS_SP_VisibilityState;
SIG_GROUP_ 256 Signal_Group_ARS_RDI_Header 1 : ARS_RDI_TimeStampGlobSec ARS_RDI_CycleCounter ARS_RDI_NumOfClusters ARS_RDI_RangeResolution ARS_RDI_MaxDetectionRange ARS_RDI_EgoVelocity ARS_RDI_EgoYawRate ARS_RDI_Latency ARS_RDI_EgoVelocityStd ARS_RDI_EgoAcceleration ARS_RDI_EgoCurvature ARS_RDI_AmbigFreeDopplerRange ARS_RDI_TaskValidFlag ARS_RDI_ExtendedCycleFlag ARS_RDI_MsgCounter_Header ARS_RDI_CRC16_Checksum_Header ARS_RDI_TimeStampGlobNSec ARS_RDI_TimeStampLocal ARS_RDI_MeasCounter;
SIG_GROUP_ 257 Signal_Group_ARS_RDI_000_007 1 : ARS_RDI_Range_Clu_000 ARS_RDI_ElevationAng_Clu_001 ARS_RDI_SNR_Clu_001 ARS_RDI_Range_Clu_002 ARS_RDI_VradRel_Clu_000 ARS_RDI_VradRel_Clu_002 ARS_RDI_RCS_Clu_002 ARS_RDI_AzimuthAng_Clu_002 ARS_RDI_ElevationAng_Clu_002 ARS_RDI_SNR_Clu_002 ARS_RDI_DynProp_Clu_002 ARS_RDI_Quality_Clu_002 ARS_RDI_DynProp_Clu_003 ARS_RDI_Quality_Clu_003 ARS_RDI_Range_Clu_003 ARS_RDI_VradRel_Clu_003 ARS_RDI_RCS_Clu_003 ARS_RDI_AzimuthAng_Clu_003 ARS_RDI_ElevationAng_Clu_003 ARS_RDI_SNR_Clu_003 ARS_RDI_RCS_Clu_000 ARS_RDI_Range_Clu_004 ARS_RDI_VradRel_Clu_004 ARS_RDI_RCS_Clu_004 ARS_RDI_AzimuthAng_Clu_004 ARS_RDI_ElevationAng_Clu_004 ARS_RDI_SNR_Clu_004 ARS_RDI_DynProp_Clu_004 ARS_RDI_Quality_Clu_004 ARS_RDI_DynProp_Clu_005 ARS_RDI_Quality_Clu_005 ARS_RDI_Range_Clu_005 ARS_RDI_VradRel_Clu_005 ARS_RDI_RCS_Clu_005 ARS_RDI_AzimuthAng_Clu_000 ARS_RDI_AzimuthAng_Clu_005 ARS_RDI_ElevationAng_Clu_005 ARS_RDI_SNR_Clu_005 ARS_RDI_Range_Clu_006 ARS_RDI_VradRel_Clu_006 ARS_RDI_RCS_Clu_006 ARS_RDI_AzimuthAng_Clu_006 ARS_RDI_ElevationAng_Clu_006 ARS_RDI_SNR_Clu_006 ARS_RDI_DynProp_Clu_006 ARS_RDI_Quality_Clu_006 ARS_RDI_DynProp_Clu_007 ARS_RDI_Quality_Clu_007 ARS_RDI_Range_Clu_007 ARS_RDI_ElevationAng_Clu_000 ARS_RDI_VradRel_Clu_007 ARS_RDI_RCS_Clu_007 ARS_RDI_AzimuthAng_Clu_007 ARS_RDI_ElevationAng_Clu_007 ARS_RDI_SNR_Clu_007 ARS_RDI_MsgCounter_Clu_000_007 ARS_RDI_CRC16_Checksum_Clu_000_0 ARS_RDI_SNR_Clu_000 ARS_RDI_DynProp_Clu_000 ARS_RDI_Quality_Clu_000 ARS_RDI_DynProp_Clu_001 ARS_RDI_Quality_Clu_001 ARS_RDI_Range_Clu_001 ARS_RDI_VradRel_Clu_001 ARS_RDI_RCS_Clu_001 ARS_RDI_AzimuthAng_Clu_001;
SIG_GROUP_ 258 Signal_Group_ARS_RDI_008_015 1 : ARS_RDI_Range_Clu_008 ARS_RDI_ElevationAng_Clu_009 ARS_RDI_SNR_Clu_009 ARS_RDI_Range_Clu_010 ARS_RDI_VradRel_Clu_008 ARS_RDI_VradRel_Clu_010 ARS_RDI_RCS_Clu_010 ARS_RDI_AzimuthAng_Clu_010 ARS_RDI_ElevationAng_Clu_010 ARS_RDI_SNR_Clu_010 ARS_RDI_DynProp_Clu_010 ARS_RDI_Quality_Clu_010 ARS_RDI_DynProp_Clu_011 ARS_RDI_Quality_Clu_011 ARS_RDI_Range_Clu_011 ARS_RDI_VradRel_Clu_011 ARS_RDI_RCS_Clu_011 ARS_RDI_AzimuthAng_Clu_011 ARS_RDI_ElevationAng_Clu_011 ARS_RDI_SNR_Clu_011 ARS_RDI_RCS_Clu_008 ARS_RDI_Range_Clu_012 ARS_RDI_VradRel_Clu_012 ARS_RDI_RCS_Clu_012 ARS_RDI_AzimuthAng_Clu_012 ARS_RDI_ElevationAng_Clu_012 ARS_RDI_SNR_Clu_012 ARS_RDI_DynProp_Clu_012 ARS_RDI_Quality_Clu_012 ARS_RDI_DynProp_Clu_013 ARS_RDI_Quality_Clu_013 ARS_RDI_Range_Clu_013 ARS_RDI_VradRel_Clu_013 ARS_RDI_RCS_Clu_013 ARS_RDI_AzimuthAng_Clu_008 ARS_RDI_AzimuthAng_Clu_013 ARS_RDI_ElevationAng_Clu_013 ARS_RDI_SNR_Clu_013 ARS_RDI_Range_Clu_014 ARS_RDI_VradRel_Clu_014 ARS_RDI_RCS_Clu_014 ARS_RDI_AzimuthAng_Clu_014 ARS_RDI_ElevationAng_Clu_014 ARS_RDI_SNR_Clu_014 ARS_RDI_DynProp_Clu_014 ARS_RDI_Quality_Clu_014 ARS_RDI_DynProp_Clu_015 ARS_RDI_Quality_Clu_015 ARS_RDI_Range_Clu_015 ARS_RDI_ElevationAng_Clu_008 ARS_RDI_VradRel_Clu_015 ARS_RDI_RCS_Clu_015 ARS_RDI_AzimuthAng_Clu_015 ARS_RDI_ElevationAng_Clu_015 ARS_RDI_SNR_Clu_015 ARS_RDI_MsgCounter_Clu_008_015 ARS_RDI_CRC16_Checksum_Clu_008_0 ARS_RDI_SNR_Clu_008 ARS_RDI_DynProp_Clu_008 ARS_RDI_Quality_Clu_008 ARS_RDI_DynProp_Clu_009 ARS_RDI_Quality_Clu_009 ARS_RDI_Range_Clu_009 ARS_RDI_VradRel_Clu_009 ARS_RDI_RCS_Clu_009 ARS_RDI_AzimuthAng_Clu_009;
SIG_GROUP_ 259 Signal_Group_ARS_RDI_016_023 1 : ARS_RDI_Range_Clu_016 ARS_RDI_ElevationAng_Clu_017 ARS_RDI_SNR_Clu_017 ARS_RDI_Range_Clu_018 ARS_RDI_VradRel_Clu_016 ARS_RDI_VradRel_Clu_018 ARS_RDI_RCS_Clu_018 ARS_RDI_AzimuthAng_Clu_018 ARS_RDI_ElevationAng_Clu_018 ARS_RDI_SNR_Clu_018 ARS_RDI_DynProp_Clu_018 ARS_RDI_Quality_Clu_018 ARS_RDI_DynProp_Clu_019 ARS_RDI_Quality_Clu_019 ARS_RDI_Range_Clu_019 ARS_RDI_VradRel_Clu_019 ARS_RDI_RCS_Clu_019 ARS_RDI_AzimuthAng_Clu_019 ARS_RDI_ElevationAng_Clu_019 ARS_RDI_SNR_Clu_019 ARS_RDI_RCS_Clu_016 ARS_RDI_Range_Clu_020 ARS_RDI_VradRel_Clu_020 ARS_RDI_RCS_Clu_020 ARS_RDI_AzimuthAng_Clu_020 ARS_RDI_ElevationAng_Clu_020 ARS_RDI_SNR_Clu_020 ARS_RDI_DynProp_Clu_020 ARS_RDI_Quality_Clu_020 ARS_RDI_DynProp_Clu_021 ARS_RDI_Quality_Clu_021 ARS_RDI_Range_Clu_021 ARS_RDI_VradRel_Clu_021 ARS_RDI_RCS_Clu_021 ARS_RDI_AzimuthAng_Clu_016 ARS_RDI_AzimuthAng_Clu_021 ARS_RDI_ElevationAng_Clu_021 ARS_RDI_SNR_Clu_021 ARS_RDI_Range_Clu_022 ARS_RDI_VradRel_Clu_022 ARS_RDI_RCS_Clu_022 ARS_RDI_AzimuthAng_Clu_022 ARS_RDI_ElevationAng_Clu_022 ARS_RDI_SNR_Clu_022 ARS_RDI_DynProp_Clu_022 ARS_RDI_Quality_Clu_022 ARS_RDI_DynProp_Clu_023 ARS_RDI_Quality_Clu_023 ARS_RDI_Range_Clu_023 ARS_RDI_ElevationAng_Clu_016 ARS_RDI_VradRel_Clu_023 ARS_RDI_RCS_Clu_023 ARS_RDI_AzimuthAng_Clu_023 ARS_RDI_ElevationAng_Clu_023 ARS_RDI_SNR_Clu_023 ARS_RDI_MsgCounter_Clu_016_023 ARS_RDI_CRC16_Checksum_Clu_016_0 ARS_RDI_SNR_Clu_016 ARS_RDI_DynProp_Clu_016 ARS_RDI_Quality_Clu_016 ARS_RDI_DynProp_Clu_017 ARS_RDI_Quality_Clu_017 ARS_RDI_Range_Clu_017 ARS_RDI_VradRel_Clu_017 ARS_RDI_RCS_Clu_017 ARS_RDI_AzimuthAng_Clu_017;
SIG_GROUP_ 260 Signal_Group_ARS_RDI_024_031 1 : ARS_RDI_Range_Clu_024 ARS_RDI_ElevationAng_Clu_025 ARS_RDI_SNR_Clu_025 ARS_RDI_Range_Clu_026 ARS_RDI_VradRel_Clu_024 ARS_RDI_VradRel_Clu_026 ARS_RDI_RCS_Clu_026 ARS_RDI_AzimuthAng_Clu_026 ARS_RDI_ElevationAng_Clu_026 ARS_RDI_SNR_Clu_026 ARS_RDI_DynProp_Clu_026 ARS_RDI_Quality_Clu_026 ARS_RDI_DynProp_Clu_027 ARS_RDI_Quality_Clu_027 ARS_RDI_Range_Clu_027 ARS_RDI_VradRel_Clu_027 ARS_RDI_RCS_Clu_027 ARS_RDI_AzimuthAng_Clu_027 ARS_RDI_ElevationAng_Clu_027 ARS_RDI_SNR_Clu_027 ARS_RDI_RCS_Clu_024 ARS_RDI_Range_Clu_028 ARS_RDI_VradRel_Clu_028 ARS_RDI_RCS_Clu_028 ARS_RDI_AzimuthAng_Clu_028 ARS_RDI_ElevationAng_Clu_028 ARS_RDI_SNR_Clu_028 ARS_RDI_DynProp_Clu_028 ARS_RDI_Quality_Clu_028 ARS_RDI_DynProp_Clu_029 ARS_RDI_Quality_Clu_029 ARS_RDI_Range_Clu_029 ARS_RDI_VradRel_Clu_029 ARS_RDI_RCS_Clu_029 ARS_RDI_AzimuthAng_Clu_024 ARS_RDI_AzimuthAng_Clu_029 ARS_RDI_ElevationAng_Clu_029 ARS_RDI_SNR_Clu_029 ARS_RDI_Range_Clu_030 ARS_RDI_VradRel_Clu_030 ARS_RDI_RCS_Clu_030 ARS_RDI_AzimuthAng_Clu_030 ARS_RDI_ElevationAng_Clu_030 ARS_RDI_SNR_Clu_030 ARS_RDI_DynProp_Clu_030 ARS_RDI_Quality_Clu_030 ARS_RDI_DynProp_Clu_031 ARS_RDI_Quality_Clu_031 ARS_RDI_Range_Clu_031 ARS_RDI_ElevationAng_Clu_024 ARS_RDI_VradRel_Clu_031 ARS_RDI_RCS_Clu_031 ARS_RDI_AzimuthAng_Clu_031 ARS_RDI_ElevationAng_Clu_031 ARS_RDI_SNR_Clu_031 ARS_RDI_MsgCounter_Clu_024_031 ARS_RDI_CRC16_Checksum_Clu_024_0 ARS_RDI_SNR_Clu_024 ARS_RDI_DynProp_Clu_024 ARS_RDI_Quality_Clu_024 ARS_RDI_DynProp_Clu_025 ARS_RDI_Quality_Clu_025 ARS_RDI_Range_Clu_025 ARS_RDI_VradRel_Clu_025 ARS_RDI_RCS_Clu_025 ARS_RDI_AzimuthAng_Clu_025;
SIG_GROUP_ 261 Signal_Group_ARS_RDI_032_039 1 : ARS_RDI_Range_Clu_032 ARS_RDI_ElevationAng_Clu_033 ARS_RDI_SNR_Clu_033 ARS_RDI_Range_Clu_034 ARS_RDI_VradRel_Clu_032 ARS_RDI_VradRel_Clu_034 ARS_RDI_RCS_Clu_034 ARS_RDI_AzimuthAng_Clu_034 ARS_RDI_ElevationAng_Clu_034 ARS_RDI_SNR_Clu_034 ARS_RDI_DynProp_Clu_034 ARS_RDI_Quality_Clu_034 ARS_RDI_DynProp_Clu_035 ARS_RDI_Quality_Clu_035 ARS_RDI_Range_Clu_035 ARS_RDI_VradRel_Clu_035 ARS_RDI_RCS_Clu_035 ARS_RDI_AzimuthAng_Clu_035 ARS_RDI_ElevationAng_Clu_035 ARS_RDI_SNR_Clu_035 ARS_RDI_RCS_Clu_032 ARS_RDI_Range_Clu_036 ARS_RDI_VradRel_Clu_036 ARS_RDI_RCS_Clu_036 ARS_RDI_AzimuthAng_Clu_036 ARS_RDI_ElevationAng_Clu_036 ARS_RDI_SNR_Clu_036 ARS_RDI_DynProp_Clu_036 ARS_RDI_Quality_Clu_036 ARS_RDI_DynProp_Clu_037 ARS_RDI_Quality_Clu_037 ARS_RDI_Range_Clu_037 ARS_RDI_VradRel_Clu_037 ARS_RDI_RCS_Clu_037 ARS_RDI_AzimuthAng_Clu_032 ARS_RDI_AzimuthAng_Clu_037 ARS_RDI_ElevationAng_Clu_037 ARS_RDI_SNR_Clu_037 ARS_RDI_Range_Clu_038 ARS_RDI_VradRel_Clu_038 ARS_RDI_RCS_Clu_038 ARS_RDI_AzimuthAng_Clu_038 ARS_RDI_ElevationAng_Clu_038 ARS_RDI_SNR_Clu_038 ARS_RDI_DynProp_Clu_038 ARS_RDI_Quality_Clu_038 ARS_RDI_DynProp_Clu_039 ARS_RDI_Quality_Clu_039 ARS_RDI_Range_Clu_039 ARS_RDI_ElevationAng_Clu_032 ARS_RDI_VradRel_Clu_039 ARS_RDI_RCS_Clu_039 ARS_RDI_AzimuthAng_Clu_039 ARS_RDI_ElevationAng_Clu_039 ARS_RDI_SNR_Clu_039 ARS_RDI_MsgCounter_Clu_032_039 ARS_RDI_CRC16_Checksum_Clu_032_0 ARS_RDI_SNR_Clu_032 ARS_RDI_DynProp_Clu_032 ARS_RDI_Quality_Clu_032 ARS_RDI_DynProp_Clu_033 ARS_RDI_Quality_Clu_033 ARS_RDI_Range_Clu_033 ARS_RDI_VradRel_Clu_033 ARS_RDI_RCS_Clu_033 ARS_RDI_AzimuthAng_Clu_033;
SIG_GROUP_ 262 Signal_Group_ARS_RDI_040_047 1 : ARS_RDI_Range_Clu_040 ARS_RDI_ElevationAng_Clu_041 ARS_RDI_SNR_Clu_041 ARS_RDI_Range_Clu_042 ARS_RDI_VradRel_Clu_040 ARS_RDI_VradRel_Clu_042 ARS_RDI_RCS_Clu_042 ARS_RDI_AzimuthAng_Clu_042 ARS_RDI_ElevationAng_Clu_042 ARS_RDI_SNR_Clu_042 ARS_RDI_DynProp_Clu_042 ARS_RDI_Quality_Clu_042 ARS_RDI_DynProp_Clu_043 ARS_RDI_Quality_Clu_043 ARS_RDI_Range_Clu_043 ARS_RDI_VradRel_Clu_043 ARS_RDI_RCS_Clu_043 ARS_RDI_AzimuthAng_Clu_043 ARS_RDI_ElevationAng_Clu_043 ARS_RDI_SNR_Clu_043 ARS_RDI_RCS_Clu_040 ARS_RDI_Range_Clu_044 ARS_RDI_VradRel_Clu_044 ARS_RDI_RCS_Clu_044 ARS_RDI_AzimuthAng_Clu_044 ARS_RDI_ElevationAng_Clu_044 ARS_RDI_SNR_Clu_044 ARS_RDI_DynProp_Clu_044 ARS_RDI_Quality_Clu_044 ARS_RDI_DynProp_Clu_045 ARS_RDI_Quality_Clu_045 ARS_RDI_Range_Clu_045 ARS_RDI_VradRel_Clu_045 ARS_RDI_RCS_Clu_045 ARS_RDI_AzimuthAng_Clu_040 ARS_RDI_AzimuthAng_Clu_045 ARS_RDI_ElevationAng_Clu_045 ARS_RDI_SNR_Clu_045 ARS_RDI_Range_Clu_046 ARS_RDI_VradRel_Clu_046 ARS_RDI_RCS_Clu_046 ARS_RDI_AzimuthAng_Clu_046 ARS_RDI_ElevationAng_Clu_046 ARS_RDI_SNR_Clu_046 ARS_RDI_DynProp_Clu_046 ARS_RDI_Quality_Clu_046 ARS_RDI_DynProp_Clu_047 ARS_RDI_Quality_Clu_047 ARS_RDI_Range_Clu_047 ARS_RDI_ElevationAng_Clu_040 ARS_RDI_VradRel_Clu_047 ARS_RDI_RCS_Clu_047 ARS_RDI_AzimuthAng_Clu_047 ARS_RDI_ElevationAng_Clu_047 ARS_RDI_SNR_Clu_047 ARS_RDI_MsgCounter_Clu_040_047 ARS_RDI_CRC16_Checksum_Clu_040_0 ARS_RDI_SNR_Clu_040 ARS_RDI_DynProp_Clu_040 ARS_RDI_Quality_Clu_040 ARS_RDI_DynProp_Clu_041 ARS_RDI_Quality_Clu_041 ARS_RDI_Range_Clu_041 ARS_RDI_VradRel_Clu_041 ARS_RDI_RCS_Clu_041 ARS_RDI_AzimuthAng_Clu_041;
SIG_GROUP_ 263 Signal_Group_ARS_RDI_048_055 1 : ARS_RDI_Range_Clu_048 ARS_RDI_ElevationAng_Clu_049 ARS_RDI_SNR_Clu_049 ARS_RDI_Range_Clu_050 ARS_RDI_VradRel_Clu_048 ARS_RDI_VradRel_Clu_050 ARS_RDI_RCS_Clu_050 ARS_RDI_AzimuthAng_Clu_050 ARS_RDI_ElevationAng_Clu_050 ARS_RDI_SNR_Clu_050 ARS_RDI_DynProp_Clu_050 ARS_RDI_Quality_Clu_050 ARS_RDI_DynProp_Clu_051 ARS_RDI_Quality_Clu_051 ARS_RDI_Range_Clu_051 ARS_RDI_VradRel_Clu_051 ARS_RDI_RCS_Clu_051 ARS_RDI_AzimuthAng_Clu_051 ARS_RDI_ElevationAng_Clu_051 ARS_RDI_SNR_Clu_051 ARS_RDI_RCS_Clu_048 ARS_RDI_Range_Clu_052 ARS_RDI_VradRel_Clu_052 ARS_RDI_RCS_Clu_052 ARS_RDI_AzimuthAng_Clu_052 ARS_RDI_ElevationAng_Clu_052 ARS_RDI_SNR_Clu_052 ARS_RDI_DynProp_Clu_052 ARS_RDI_Quality_Clu_052 ARS_RDI_DynProp_Clu_053 ARS_RDI_Quality_Clu_053 ARS_RDI_Range_Clu_053 ARS_RDI_VradRel_Clu_053 ARS_RDI_RCS_Clu_053 ARS_RDI_AzimuthAng_Clu_048 ARS_RDI_AzimuthAng_Clu_053 ARS_RDI_ElevationAng_Clu_053 ARS_RDI_SNR_Clu_053 ARS_RDI_Range_Clu_054 ARS_RDI_VradRel_Clu_054 ARS_RDI_RCS_Clu_054 ARS_RDI_AzimuthAng_Clu_054 ARS_RDI_ElevationAng_Clu_054 ARS_RDI_SNR_Clu_054 ARS_RDI_DynProp_Clu_054 ARS_RDI_Quality_Clu_054 ARS_RDI_DynProp_Clu_055 ARS_RDI_Quality_Clu_055 ARS_RDI_Range_Clu_055 ARS_RDI_ElevationAng_Clu_048 ARS_RDI_VradRel_Clu_055 ARS_RDI_RCS_Clu_055 ARS_RDI_AzimuthAng_Clu_055 ARS_RDI_ElevationAng_Clu_055 ARS_RDI_SNR_Clu_055 ARS_RDI_MsgCounter_Clu_048_055 ARS_RDI_CRC16_Checksum_Clu_048_0 ARS_RDI_SNR_Clu_048 ARS_RDI_DynProp_Clu_048 ARS_RDI_Quality_Clu_048 ARS_RDI_DynProp_Clu_049 ARS_RDI_Quality_Clu_049 ARS_RDI_Range_Clu_049 ARS_RDI_VradRel_Clu_049 ARS_RDI_RCS_Clu_049 ARS_RDI_AzimuthAng_Clu_049;
SIG_GROUP_ 264 Signal_Group_ARS_RDI_056_063 1 : ARS_RDI_Range_Clu_056 ARS_RDI_ElevationAng_Clu_057 ARS_RDI_SNR_Clu_057 ARS_RDI_Range_Clu_058 ARS_RDI_VradRel_Clu_056 ARS_RDI_VradRel_Clu_058 ARS_RDI_RCS_Clu_058 ARS_RDI_AzimuthAng_Clu_058 ARS_RDI_ElevationAng_Clu_058 ARS_RDI_SNR_Clu_058 ARS_RDI_DynProp_Clu_058 ARS_RDI_Quality_Clu_058 ARS_RDI_DynProp_Clu_059 ARS_RDI_Quality_Clu_059 ARS_RDI_Range_Clu_059 ARS_RDI_VradRel_Clu_059 ARS_RDI_RCS_Clu_059 ARS_RDI_AzimuthAng_Clu_059 ARS_RDI_ElevationAng_Clu_059 ARS_RDI_SNR_Clu_059 ARS_RDI_RCS_Clu_056 ARS_RDI_Range_Clu_060 ARS_RDI_VradRel_Clu_060 ARS_RDI_RCS_Clu_060 ARS_RDI_AzimuthAng_Clu_060 ARS_RDI_ElevationAng_Clu_060 ARS_RDI_SNR_Clu_060 ARS_RDI_DynProp_Clu_060 ARS_RDI_Quality_Clu_060 ARS_RDI_DynProp_Clu_061 ARS_RDI_Quality_Clu_061 ARS_RDI_Range_Clu_061 ARS_RDI_VradRel_Clu_061 ARS_RDI_RCS_Clu_061 ARS_RDI_AzimuthAng_Clu_056 ARS_RDI_AzimuthAng_Clu_061 ARS_RDI_ElevationAng_Clu_061 ARS_RDI_SNR_Clu_061 ARS_RDI_Range_Clu_062 ARS_RDI_VradRel_Clu_062 ARS_RDI_RCS_Clu_062 ARS_RDI_AzimuthAng_Clu_062 ARS_RDI_ElevationAng_Clu_062 ARS_RDI_SNR_Clu_062 ARS_RDI_DynProp_Clu_062 ARS_RDI_Quality_Clu_062 ARS_RDI_DynProp_Clu_063 ARS_RDI_Quality_Clu_063 ARS_RDI_Range_Clu_063 ARS_RDI_ElevationAng_Clu_056 ARS_RDI_VradRel_Clu_063 ARS_RDI_RCS_Clu_063 ARS_RDI_AzimuthAng_Clu_063 ARS_RDI_ElevationAng_Clu_063 ARS_RDI_SNR_Clu_063 ARS_RDI_MsgCounter_Clu_056_063 ARS_RDI_CRC16_Checksum_Clu_056_0 ARS_RDI_SNR_Clu_056 ARS_RDI_DynProp_Clu_056 ARS_RDI_Quality_Clu_056 ARS_RDI_DynProp_Clu_057 ARS_RDI_Quality_Clu_057 ARS_RDI_Range_Clu_057 ARS_RDI_VradRel_Clu_057 ARS_RDI_RCS_Clu_057 ARS_RDI_AzimuthAng_Clu_057;
SIG_GROUP_ 265 Signal_Group_ARS_RDI_064_071 1 : ARS_RDI_Range_Clu_064 ARS_RDI_ElevationAng_Clu_065 ARS_RDI_SNR_Clu_065 ARS_RDI_Range_Clu_066 ARS_RDI_VradRel_Clu_064 ARS_RDI_VradRel_Clu_066 ARS_RDI_RCS_Clu_066 ARS_RDI_AzimuthAng_Clu_066 ARS_RDI_ElevationAng_Clu_066 ARS_RDI_SNR_Clu_066 ARS_RDI_DynProp_Clu_066 ARS_RDI_Quality_Clu_066 ARS_RDI_DynProp_Clu_067 ARS_RDI_Quality_Clu_067 ARS_RDI_Range_Clu_067 ARS_RDI_VradRel_Clu_067 ARS_RDI_RCS_Clu_067 ARS_RDI_AzimuthAng_Clu_067 ARS_RDI_ElevationAng_Clu_067 ARS_RDI_SNR_Clu_067 ARS_RDI_RCS_Clu_064 ARS_RDI_Range_Clu_068 ARS_RDI_VradRel_Clu_068 ARS_RDI_RCS_Clu_068 ARS_RDI_AzimuthAng_Clu_068 ARS_RDI_ElevationAng_Clu_068 ARS_RDI_SNR_Clu_068 ARS_RDI_DynProp_Clu_068 ARS_RDI_Quality_Clu_068 ARS_RDI_DynProp_Clu_069 ARS_RDI_Quality_Clu_069 ARS_RDI_Range_Clu_069 ARS_RDI_VradRel_Clu_069 ARS_RDI_RCS_Clu_069 ARS_RDI_AzimuthAng_Clu_064 ARS_RDI_AzimuthAng_Clu_069 ARS_RDI_ElevationAng_Clu_069 ARS_RDI_SNR_Clu_069 ARS_RDI_Range_Clu_070 ARS_RDI_VradRel_Clu_070 ARS_RDI_RCS_Clu_070 ARS_RDI_AzimuthAng_Clu_070 ARS_RDI_ElevationAng_Clu_070 ARS_RDI_SNR_Clu_070 ARS_RDI_DynProp_Clu_070 ARS_RDI_Quality_Clu_070 ARS_RDI_DynProp_Clu_071 ARS_RDI_Quality_Clu_071 ARS_RDI_Range_Clu_071 ARS_RDI_ElevationAng_Clu_064 ARS_RDI_VradRel_Clu_071 ARS_RDI_RCS_Clu_071 ARS_RDI_AzimuthAng_Clu_071 ARS_RDI_ElevationAng_Clu_071 ARS_RDI_SNR_Clu_071 ARS_RDI_MsgCounter_Clu_064_071 ARS_RDI_CRC16_Checksum_Clu_064_0 ARS_RDI_SNR_Clu_064 ARS_RDI_DynProp_Clu_064 ARS_RDI_Quality_Clu_064 ARS_RDI_DynProp_Clu_065 ARS_RDI_Quality_Clu_065 ARS_RDI_Range_Clu_065 ARS_RDI_VradRel_Clu_065 ARS_RDI_RCS_Clu_065 ARS_RDI_AzimuthAng_Clu_065;
SIG_GROUP_ 266 Signal_Group_ARS_RDI_072_079 1 : ARS_RDI_Range_Clu_072 ARS_RDI_ElevationAng_Clu_073 ARS_RDI_SNR_Clu_073 ARS_RDI_Range_Clu_074 ARS_RDI_VradRel_Clu_072 ARS_RDI_VradRel_Clu_074 ARS_RDI_RCS_Clu_074 ARS_RDI_AzimuthAng_Clu_074 ARS_RDI_ElevationAng_Clu_074 ARS_RDI_SNR_Clu_074 ARS_RDI_DynProp_Clu_074 ARS_RDI_Quality_Clu_074 ARS_RDI_DynProp_Clu_075 ARS_RDI_Quality_Clu_075 ARS_RDI_Range_Clu_075 ARS_RDI_VradRel_Clu_075 ARS_RDI_RCS_Clu_075 ARS_RDI_AzimuthAng_Clu_075 ARS_RDI_ElevationAng_Clu_075 ARS_RDI_SNR_Clu_075 ARS_RDI_RCS_Clu_072 ARS_RDI_Range_Clu_076 ARS_RDI_VradRel_Clu_076 ARS_RDI_RCS_Clu_076 ARS_RDI_AzimuthAng_Clu_076 ARS_RDI_ElevationAng_Clu_076 ARS_RDI_SNR_Clu_076 ARS_RDI_DynProp_Clu_076 ARS_RDI_Quality_Clu_076 ARS_RDI_DynProp_Clu_077 ARS_RDI_Quality_Clu_077 ARS_RDI_Range_Clu_077 ARS_RDI_VradRel_Clu_077 ARS_RDI_RCS_Clu_077 ARS_RDI_AzimuthAng_Clu_072 ARS_RDI_AzimuthAng_Clu_077 ARS_RDI_ElevationAng_Clu_077 ARS_RDI_SNR_Clu_077 ARS_RDI_Range_Clu_078 ARS_RDI_VradRel_Clu_078 ARS_RDI_RCS_Clu_078 ARS_RDI_AzimuthAng_Clu_078 ARS_RDI_ElevationAng_Clu_078 ARS_RDI_SNR_Clu_078 ARS_RDI_DynProp_Clu_078 ARS_RDI_Quality_Clu_078 ARS_RDI_DynProp_Clu_079 ARS_RDI_Quality_Clu_079 ARS_RDI_Range_Clu_079 ARS_RDI_ElevationAng_Clu_072 ARS_RDI_VradRel_Clu_079 ARS_RDI_RCS_Clu_079 ARS_RDI_AzimuthAng_Clu_079 ARS_RDI_ElevationAng_Clu_079 ARS_RDI_SNR_Clu_079 ARS_RDI_MsgCounter_Clu_072_079 ARS_RDI_CRC16_Checksum_Clu_072_0 ARS_RDI_SNR_Clu_072 ARS_RDI_DynProp_Clu_072 ARS_RDI_Quality_Clu_072 ARS_RDI_DynProp_Clu_073 ARS_RDI_Quality_Clu_073 ARS_RDI_Range_Clu_073 ARS_RDI_VradRel_Clu_073 ARS_RDI_RCS_Clu_073 ARS_RDI_AzimuthAng_Clu_073;
SIG_GROUP_ 267 Signal_Group_ARS_RDI_080_087 1 : ARS_RDI_Range_Clu_080 ARS_RDI_ElevationAng_Clu_081 ARS_RDI_SNR_Clu_081 ARS_RDI_Range_Clu_082 ARS_RDI_VradRel_Clu_080 ARS_RDI_VradRel_Clu_082 ARS_RDI_RCS_Clu_082 ARS_RDI_AzimuthAng_Clu_082 ARS_RDI_ElevationAng_Clu_082 ARS_RDI_SNR_Clu_082 ARS_RDI_DynProp_Clu_082 ARS_RDI_Quality_Clu_082 ARS_RDI_DynProp_Clu_083 ARS_RDI_Quality_Clu_083 ARS_RDI_Range_Clu_083 ARS_RDI_VradRel_Clu_083 ARS_RDI_RCS_Clu_083 ARS_RDI_AzimuthAng_Clu_083 ARS_RDI_ElevationAng_Clu_083 ARS_RDI_SNR_Clu_083 ARS_RDI_RCS_Clu_080 ARS_RDI_Range_Clu_084 ARS_RDI_VradRel_Clu_084 ARS_RDI_RCS_Clu_084 ARS_RDI_AzimuthAng_Clu_084 ARS_RDI_ElevationAng_Clu_084 ARS_RDI_SNR_Clu_084 ARS_RDI_DynProp_Clu_084 ARS_RDI_Quality_Clu_084 ARS_RDI_DynProp_Clu_085 ARS_RDI_Quality_Clu_085 ARS_RDI_Range_Clu_085 ARS_RDI_VradRel_Clu_085 ARS_RDI_RCS_Clu_085 ARS_RDI_AzimuthAng_Clu_080 ARS_RDI_AzimuthAng_Clu_085 ARS_RDI_ElevationAng_Clu_085 ARS_RDI_SNR_Clu_085 ARS_RDI_Range_Clu_086 ARS_RDI_VradRel_Clu_086 ARS_RDI_RCS_Clu_086 ARS_RDI_AzimuthAng_Clu_086 ARS_RDI_ElevationAng_Clu_086 ARS_RDI_SNR_Clu_086 ARS_RDI_DynProp_Clu_086 ARS_RDI_Quality_Clu_086 ARS_RDI_DynProp_Clu_087 ARS_RDI_Quality_Clu_087 ARS_RDI_Range_Clu_087 ARS_RDI_ElevationAng_Clu_080 ARS_RDI_VradRel_Clu_087 ARS_RDI_RCS_Clu_087 ARS_RDI_AzimuthAng_Clu_087 ARS_RDI_ElevationAng_Clu_087 ARS_RDI_SNR_Clu_087 ARS_RDI_MsgCounter_Clu_080_087 ARS_RDI_CRC16_Checksum_Clu_080_0 ARS_RDI_SNR_Clu_080 ARS_RDI_DynProp_Clu_080 ARS_RDI_Quality_Clu_080 ARS_RDI_DynProp_Clu_081 ARS_RDI_Quality_Clu_081 ARS_RDI_Range_Clu_081 ARS_RDI_VradRel_Clu_081 ARS_RDI_RCS_Clu_081 ARS_RDI_AzimuthAng_Clu_081;
SIG_GROUP_ 268 Signal_Group_ARS_RDI_088_095 1 : ARS_RDI_Range_Clu_088 ARS_RDI_ElevationAng_Clu_089 ARS_RDI_SNR_Clu_089 ARS_RDI_Range_Clu_090 ARS_RDI_VradRel_Clu_088 ARS_RDI_VradRel_Clu_090 ARS_RDI_RCS_Clu_090 ARS_RDI_AzimuthAng_Clu_090 ARS_RDI_ElevationAng_Clu_090 ARS_RDI_SNR_Clu_090 ARS_RDI_DynProp_Clu_090 ARS_RDI_Quality_Clu_090 ARS_RDI_DynProp_Clu_091 ARS_RDI_Quality_Clu_091 ARS_RDI_Range_Clu_091 ARS_RDI_VradRel_Clu_091 ARS_RDI_RCS_Clu_091 ARS_RDI_AzimuthAng_Clu_091 ARS_RDI_ElevationAng_Clu_091 ARS_RDI_SNR_Clu_091 ARS_RDI_RCS_Clu_088 ARS_RDI_Range_Clu_092 ARS_RDI_VradRel_Clu_092 ARS_RDI_RCS_Clu_092 ARS_RDI_AzimuthAng_Clu_092 ARS_RDI_ElevationAng_Clu_092 ARS_RDI_SNR_Clu_092 ARS_RDI_DynProp_Clu_092 ARS_RDI_Quality_Clu_092 ARS_RDI_DynProp_Clu_093 ARS_RDI_Quality_Clu_093 ARS_RDI_Range_Clu_093 ARS_RDI_VradRel_Clu_093 ARS_RDI_RCS_Clu_093 ARS_RDI_AzimuthAng_Clu_088 ARS_RDI_AzimuthAng_Clu_093 ARS_RDI_ElevationAng_Clu_093 ARS_RDI_SNR_Clu_093 ARS_RDI_Range_Clu_094 ARS_RDI_VradRel_Clu_094 ARS_RDI_RCS_Clu_094 ARS_RDI_AzimuthAng_Clu_094 ARS_RDI_ElevationAng_Clu_094 ARS_RDI_SNR_Clu_094 ARS_RDI_DynProp_Clu_094 ARS_RDI_Quality_Clu_094 ARS_RDI_DynProp_Clu_095 ARS_RDI_Quality_Clu_095 ARS_RDI_Range_Clu_095 ARS_RDI_ElevationAng_Clu_088 ARS_RDI_VradRel_Clu_095 ARS_RDI_RCS_Clu_095 ARS_RDI_AzimuthAng_Clu_095 ARS_RDI_ElevationAng_Clu_095 ARS_RDI_SNR_Clu_095 ARS_RDI_MsgCounter_Clu_088_095 ARS_RDI_CRC16_Checksum_Clu_088_0 ARS_RDI_SNR_Clu_088 ARS_RDI_DynProp_Clu_088 ARS_RDI_Quality_Clu_088 ARS_RDI_DynProp_Clu_089 ARS_RDI_Quality_Clu_089 ARS_RDI_Range_Clu_089 ARS_RDI_VradRel_Clu_089 ARS_RDI_RCS_Clu_089 ARS_RDI_AzimuthAng_Clu_089;
SIG_GROUP_ 269 Signal_Group_ARS_RDI_096_103 1 : ARS_RDI_Range_Clu_096 ARS_RDI_ElevationAng_Clu_097 ARS_RDI_SNR_Clu_097 ARS_RDI_Range_Clu_098 ARS_RDI_VradRel_Clu_096 ARS_RDI_VradRel_Clu_098 ARS_RDI_RCS_Clu_098 ARS_RDI_AzimuthAng_Clu_098 ARS_RDI_ElevationAng_Clu_098 ARS_RDI_SNR_Clu_098 ARS_RDI_DynProp_Clu_098 ARS_RDI_Quality_Clu_098 ARS_RDI_DynProp_Clu_099 ARS_RDI_Quality_Clu_099 ARS_RDI_Range_Clu_099 ARS_RDI_VradRel_Clu_099 ARS_RDI_RCS_Clu_099 ARS_RDI_AzimuthAng_Clu_099 ARS_RDI_ElevationAng_Clu_099 ARS_RDI_SNR_Clu_099 ARS_RDI_RCS_Clu_096 ARS_RDI_Range_Clu_100 ARS_RDI_VradRel_Clu_100 ARS_RDI_RCS_Clu_100 ARS_RDI_AzimuthAng_Clu_100 ARS_RDI_ElevationAng_Clu_100 ARS_RDI_SNR_Clu_100 ARS_RDI_DynProp_Clu_100 ARS_RDI_Quality_Clu_100 ARS_RDI_DynProp_Clu_101 ARS_RDI_Quality_Clu_101 ARS_RDI_Range_Clu_101 ARS_RDI_VradRel_Clu_101 ARS_RDI_RCS_Clu_101 ARS_RDI_AzimuthAng_Clu_096 ARS_RDI_AzimuthAng_Clu_101 ARS_RDI_ElevationAng_Clu_101 ARS_RDI_SNR_Clu_101 ARS_RDI_Range_Clu_102 ARS_RDI_VradRel_Clu_102 ARS_RDI_RCS_Clu_102 ARS_RDI_AzimuthAng_Clu_102 ARS_RDI_ElevationAng_Clu_102 ARS_RDI_SNR_Clu_102 ARS_RDI_DynProp_Clu_102 ARS_RDI_Quality_Clu_102 ARS_RDI_DynProp_Clu_103 ARS_RDI_Quality_Clu_103 ARS_RDI_Range_Clu_103 ARS_RDI_ElevationAng_Clu_096 ARS_RDI_VradRel_Clu_103 ARS_RDI_RCS_Clu_103 ARS_RDI_AzimuthAng_Clu_103 ARS_RDI_ElevationAng_Clu_103 ARS_RDI_SNR_Clu_103 ARS_RDI_MsgCounter_Clu_096_103 ARS_RDI_CRC16_Checksum_Clu_096_1 ARS_RDI_SNR_Clu_096 ARS_RDI_DynProp_Clu_096 ARS_RDI_Quality_Clu_096 ARS_RDI_DynProp_Clu_097 ARS_RDI_Quality_Clu_097 ARS_RDI_Range_Clu_097 ARS_RDI_VradRel_Clu_097 ARS_RDI_RCS_Clu_097 ARS_RDI_AzimuthAng_Clu_097;
SIG_GROUP_ 270 Signal_Group_ARS_RDI_104_111 1 : ARS_RDI_Range_Clu_104 ARS_RDI_ElevationAng_Clu_105 ARS_RDI_SNR_Clu_105 ARS_RDI_Range_Clu_106 ARS_RDI_VradRel_Clu_104 ARS_RDI_VradRel_Clu_106 ARS_RDI_RCS_Clu_106 ARS_RDI_AzimuthAng_Clu_106 ARS_RDI_ElevationAng_Clu_106 ARS_RDI_SNR_Clu_106 ARS_RDI_DynProp_Clu_106 ARS_RDI_Quality_Clu_106 ARS_RDI_DynProp_Clu_107 ARS_RDI_Quality_Clu_107 ARS_RDI_Range_Clu_107 ARS_RDI_VradRel_Clu_107 ARS_RDI_RCS_Clu_107 ARS_RDI_AzimuthAng_Clu_107 ARS_RDI_ElevationAng_Clu_107 ARS_RDI_SNR_Clu_107 ARS_RDI_RCS_Clu_104 ARS_RDI_Range_Clu_108 ARS_RDI_VradRel_Clu_108 ARS_RDI_RCS_Clu_108 ARS_RDI_AzimuthAng_Clu_108 ARS_RDI_ElevationAng_Clu_108 ARS_RDI_SNR_Clu_108 ARS_RDI_DynProp_Clu_108 ARS_RDI_Quality_Clu_108 ARS_RDI_DynProp_Clu_109 ARS_RDI_Quality_Clu_109 ARS_RDI_Range_Clu_109 ARS_RDI_VradRel_Clu_109 ARS_RDI_RCS_Clu_109 ARS_RDI_AzimuthAng_Clu_104 ARS_RDI_AzimuthAng_Clu_109 ARS_RDI_ElevationAng_Clu_109 ARS_RDI_SNR_Clu_109 ARS_RDI_Range_Clu_110 ARS_RDI_VradRel_Clu_110 ARS_RDI_RCS_Clu_110 ARS_RDI_AzimuthAng_Clu_110 ARS_RDI_ElevationAng_Clu_110 ARS_RDI_SNR_Clu_110 ARS_RDI_DynProp_Clu_110 ARS_RDI_Quality_Clu_110 ARS_RDI_DynProp_Clu_111 ARS_RDI_Quality_Clu_111 ARS_RDI_Range_Clu_111 ARS_RDI_ElevationAng_Clu_104 ARS_RDI_VradRel_Clu_111 ARS_RDI_RCS_Clu_111 ARS_RDI_AzimuthAng_Clu_111 ARS_RDI_ElevationAng_Clu_111 ARS_RDI_SNR_Clu_111 ARS_RDI_MsgCounter_Clu_104_111 ARS_RDI_CRC16_Checksum_Clu_104_1 ARS_RDI_SNR_Clu_104 ARS_RDI_DynProp_Clu_104 ARS_RDI_Quality_Clu_104 ARS_RDI_DynProp_Clu_105 ARS_RDI_Quality_Clu_105 ARS_RDI_Range_Clu_105 ARS_RDI_VradRel_Clu_105 ARS_RDI_RCS_Clu_105 ARS_RDI_AzimuthAng_Clu_105;
SIG_GROUP_ 271 Signal_Group_ARS_RDI_112_119 1 : ARS_RDI_Range_Clu_112 ARS_RDI_ElevationAng_Clu_113 ARS_RDI_SNR_Clu_113 ARS_RDI_Range_Clu_114 ARS_RDI_VradRel_Clu_112 ARS_RDI_VradRel_Clu_114 ARS_RDI_RCS_Clu_114 ARS_RDI_AzimuthAng_Clu_114 ARS_RDI_ElevationAng_Clu_114 ARS_RDI_SNR_Clu_114 ARS_RDI_DynProp_Clu_114 ARS_RDI_Quality_Clu_114 ARS_RDI_DynProp_Clu_115 ARS_RDI_Quality_Clu_115 ARS_RDI_Range_Clu_115 ARS_RDI_VradRel_Clu_115 ARS_RDI_RCS_Clu_115 ARS_RDI_AzimuthAng_Clu_115 ARS_RDI_ElevationAng_Clu_115 ARS_RDI_SNR_Clu_115 ARS_RDI_RCS_Clu_112 ARS_RDI_Range_Clu_116 ARS_RDI_VradRel_Clu_116 ARS_RDI_RCS_Clu_116 ARS_RDI_AzimuthAng_Clu_116 ARS_RDI_ElevationAng_Clu_116 ARS_RDI_SNR_Clu_116 ARS_RDI_DynProp_Clu_116 ARS_RDI_Quality_Clu_116 ARS_RDI_DynProp_Clu_117 ARS_RDI_Quality_Clu_117 ARS_RDI_Range_Clu_117 ARS_RDI_VradRel_Clu_117 ARS_RDI_RCS_Clu_117 ARS_RDI_AzimuthAng_Clu_112 ARS_RDI_AzimuthAng_Clu_117 ARS_RDI_ElevationAng_Clu_117 ARS_RDI_SNR_Clu_117 ARS_RDI_Range_Clu_118 ARS_RDI_VradRel_Clu_118 ARS_RDI_RCS_Clu_118 ARS_RDI_AzimuthAng_Clu_118 ARS_RDI_ElevationAng_Clu_118 ARS_RDI_SNR_Clu_118 ARS_RDI_DynProp_Clu_118 ARS_RDI_Quality_Clu_118 ARS_RDI_DynProp_Clu_119 ARS_RDI_Quality_Clu_119 ARS_RDI_Range_Clu_119 ARS_RDI_ElevationAng_Clu_112 ARS_RDI_VradRel_Clu_119 ARS_RDI_RCS_Clu_119 ARS_RDI_AzimuthAng_Clu_119 ARS_RDI_ElevationAng_Clu_119 ARS_RDI_SNR_Clu_119 ARS_RDI_MsgCounter_Clu_112_119 ARS_RDI_CRC16_Checksum_Clu_112_1 ARS_RDI_SNR_Clu_112 ARS_RDI_DynProp_Clu_112 ARS_RDI_Quality_Clu_112 ARS_RDI_DynProp_Clu_113 ARS_RDI_Quality_Clu_113 ARS_RDI_Range_Clu_113 ARS_RDI_VradRel_Clu_113 ARS_RDI_RCS_Clu_113 ARS_RDI_AzimuthAng_Clu_113;
SIG_GROUP_ 272 Signal_Group_ARS_RDI_120_127 1 : ARS_RDI_Range_Clu_120 ARS_RDI_ElevationAng_Clu_121 ARS_RDI_SNR_Clu_121 ARS_RDI_Range_Clu_122 ARS_RDI_VradRel_Clu_120 ARS_RDI_VradRel_Clu_122 ARS_RDI_RCS_Clu_122 ARS_RDI_AzimuthAng_Clu_122 ARS_RDI_ElevationAng_Clu_122 ARS_RDI_SNR_Clu_122 ARS_RDI_DynProp_Clu_122 ARS_RDI_Quality_Clu_122 ARS_RDI_DynProp_Clu_123 ARS_RDI_Quality_Clu_123 ARS_RDI_Range_Clu_123 ARS_RDI_VradRel_Clu_123 ARS_RDI_RCS_Clu_123 ARS_RDI_AzimuthAng_Clu_123 ARS_RDI_ElevationAng_Clu_123 ARS_RDI_SNR_Clu_123 ARS_RDI_RCS_Clu_120 ARS_RDI_Range_Clu_124 ARS_RDI_VradRel_Clu_124 ARS_RDI_RCS_Clu_124 ARS_RDI_AzimuthAng_Clu_124 ARS_RDI_ElevationAng_Clu_124 ARS_RDI_SNR_Clu_124 ARS_RDI_DynProp_Clu_124 ARS_RDI_Quality_Clu_124 ARS_RDI_DynProp_Clu_125 ARS_RDI_Quality_Clu_125 ARS_RDI_Range_Clu_125 ARS_RDI_VradRel_Clu_125 ARS_RDI_RCS_Clu_125 ARS_RDI_AzimuthAng_Clu_120 ARS_RDI_AzimuthAng_Clu_125 ARS_RDI_ElevationAng_Clu_125 ARS_RDI_SNR_Clu_125 ARS_RDI_Range_Clu_126 ARS_RDI_VradRel_Clu_126 ARS_RDI_RCS_Clu_126 ARS_RDI_AzimuthAng_Clu_126 ARS_RDI_ElevationAng_Clu_126 ARS_RDI_SNR_Clu_126 ARS_RDI_DynProp_Clu_126 ARS_RDI_Quality_Clu_126 ARS_RDI_DynProp_Clu_127 ARS_RDI_Quality_Clu_127 ARS_RDI_Range_Clu_127 ARS_RDI_ElevationAng_Clu_120 ARS_RDI_VradRel_Clu_127 ARS_RDI_RCS_Clu_127 ARS_RDI_AzimuthAng_Clu_127 ARS_RDI_ElevationAng_Clu_127 ARS_RDI_SNR_Clu_127 ARS_RDI_MsgCounter_Clu_120_127 ARS_RDI_CRC16_Checksum_Clu_120_1 ARS_RDI_SNR_Clu_120 ARS_RDI_DynProp_Clu_120 ARS_RDI_Quality_Clu_120 ARS_RDI_DynProp_Clu_121 ARS_RDI_Quality_Clu_121 ARS_RDI_Range_Clu_121 ARS_RDI_VradRel_Clu_121 ARS_RDI_RCS_Clu_121 ARS_RDI_AzimuthAng_Clu_121;
